VERSION ""

NS_ :

BS_:

BU_: DSAU vHS_M SHVU_RR DPSS AMP ICC RLPSM APSM RWPC RRHV RRPSM CGW_CCU APSS ATS RLHV FPM RDC PSM ASAU

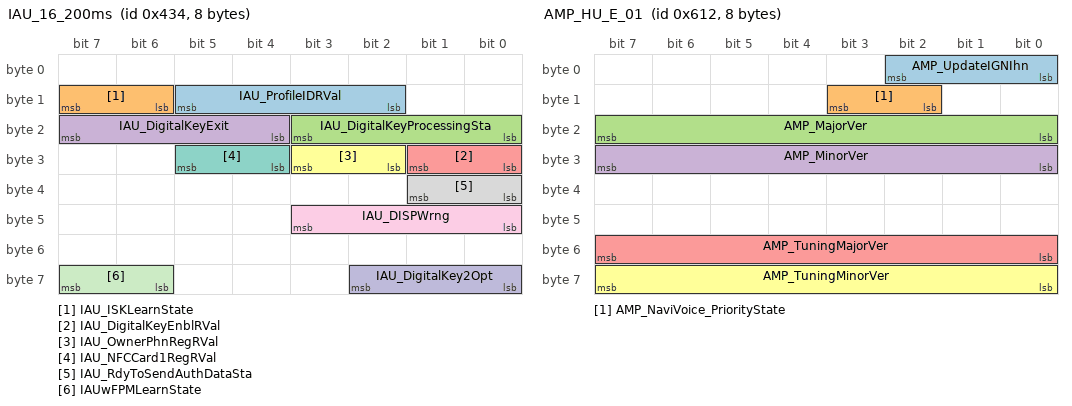
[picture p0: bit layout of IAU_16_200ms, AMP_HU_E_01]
BO_ 1076 IAU_16_200ms: 8 CGW_CCU
 SG_ IAU_ProfileIDRVal : 10|4@1+ (1,0) [0|0] ""  PSM,FPM
 SG_ IAU_ISKLearnState : 14|2@1+ (1,0) [0|0] ""  Vector__XXX
 SG_ IAU_DigitalKeyProcessingSta : 16|4@1+ (1,0) [0|0] ""  Vector__XXX
 SG_ IAU_DigitalKeyExit : 20|4@1+ (1,0) [0|0] ""  Vector__XXX
 SG_ IAU_DigitalKeyEnblRVal : 24|2@1+ (1,0) [0|0] ""  Vector__XXX
 SG_ IAU_OwnerPhnRegRVal : 26|2@1+ (1,0) [0|0] ""  Vector__XXX
 SG_ IAU_NFCCard1RegRVal : 28|2@1+ (1,0) [0|0] ""  Vector__XXX
 SG_ IAU_RdyToSendAuthDataSta : 32|2@1+ (1,0) [0|0] ""  Vector__XXX
 SG_ IAU_DISPWrng : 40|4@1+ (1,0) [0|0] ""  Vector__XXX
 SG_ IAU_DigitalKey2Opt : 56|3@1+ (1,0) [0|0] ""  Vector__XXX
 SG_ IAUwFPMLearnState : 62|2@1+ (1,0) [0|0] ""  FPM

BO_ 1554 AMP_HU_E_01: 8 AMP
 SG_ AMP_UpdateIGNIhn : 0|3@1+ (1,0) [0|0] ""  CGW_CCU
 SG_ AMP_NaviVoice_PriorityState : 10|2@1+ (1,0) [0|0] ""  CGW_CCU
 SG_ AMP_MajorVer : 16|8@1+ (1,0) [0|0] ""  CGW_CCU
 SG_ AMP_MinorVer : 24|8@1+ (1,0) [0|0] ""  CGW_CCU
 SG_ AMP_TuningMajorVer : 48|8@1+ (1,0) [0|0] ""  CGW_CCU
 SG_ AMP_TuningMinorVer : 56|8@1+ (1,0) [0|0] ""  CGW_CCU

BO_ 2563126529 HU_AMP_E_06_1: 8 CGW_CCU
 SG_ AMP_MTSVolumeStep : 0|8@1+ (1,0) [0|0] ""  AMP

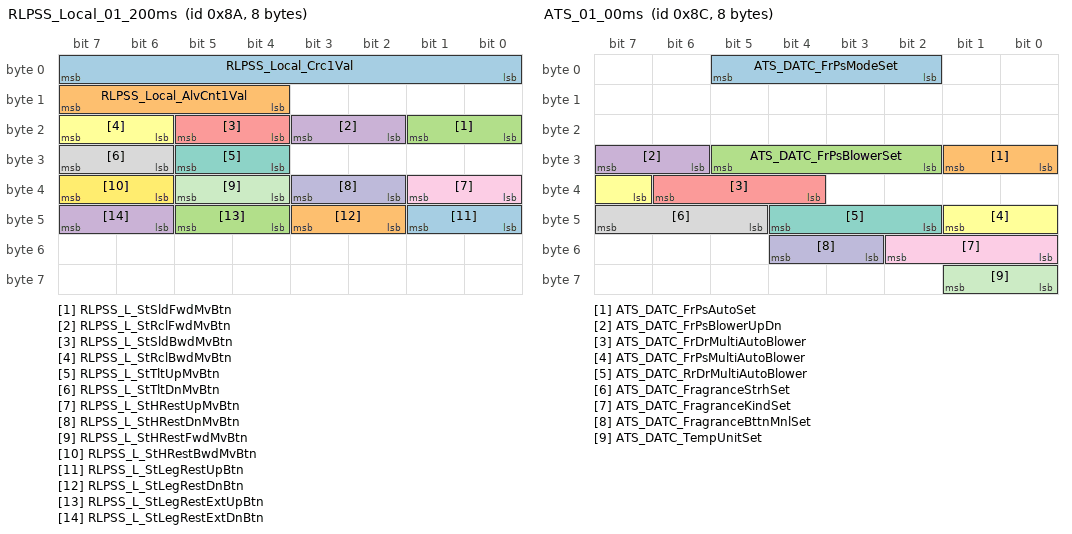
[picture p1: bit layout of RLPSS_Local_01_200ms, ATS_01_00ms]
BO_ 138 RLPSS_Local_01_200ms: 8 RLPSM
 SG_ RLPSS_Local_Crc1Val : 0|8@1+ (1,0) [0|0] ""  CGW_CCU
 SG_ RLPSS_Local_AlvCnt1Val : 12|4@1+ (1,0) [0|0] ""  CGW_CCU
 SG_ RLPSS_L_StSldFwdMvBtn : 16|2@1+ (1,0) [0|0] ""  ATS,CGW_CCU
 SG_ RLPSS_L_StRclFwdMvBtn : 18|2@1+ (1,0) [0|0] ""  ATS,CGW_CCU
 SG_ RLPSS_L_StSldBwdMvBtn : 20|2@1+ (1,0) [0|0] ""  ATS,CGW_CCU
 SG_ RLPSS_L_StRclBwdMvBtn : 22|2@1+ (1,0) [0|0] ""  ATS,CGW_CCU
 SG_ RLPSS_L_StTltUpMvBtn : 28|2@1+ (1,0) [0|0] ""  ATS,CGW_CCU
 SG_ RLPSS_L_StTltDnMvBtn : 30|2@1+ (1,0) [0|0] ""  ATS,CGW_CCU
 SG_ RLPSS_L_StHRestUpMvBtn : 32|2@1+ (1,0) [0|0] ""  ATS,CGW_CCU
 SG_ RLPSS_L_StHRestDnMvBtn : 34|2@1+ (1,0) [0|0] ""  ATS,CGW_CCU
 SG_ RLPSS_L_StHRestFwdMvBtn : 36|2@1+ (1,0) [0|0] ""  ATS,CGW_CCU
 SG_ RLPSS_L_StHRestBwdMvBtn : 38|2@1+ (1,0) [0|0] ""  ATS,CGW_CCU
 SG_ RLPSS_L_StLegRestUpBtn : 40|2@1+ (1,0) [0|0] ""  ATS,CGW_CCU
 SG_ RLPSS_L_StLegRestDnBtn : 42|2@1+ (1,0) [0|0] ""  ATS,CGW_CCU
 SG_ RLPSS_L_StLegRestExtUpBtn : 44|2@1+ (1,0) [0|0] ""  ATS,CGW_CCU
 SG_ RLPSS_L_StLegRestExtDnBtn : 46|2@1+ (1,0) [0|0] ""  ATS,CGW_CCU

BO_ 140 ATS_01_00ms: 8 ATS
 SG_ ATS_DATC_FrPsModeSet : 2|4@1+ (1,0) [0|0] ""  CGW_CCU
 SG_ ATS_DATC_FrPsAutoSet : 24|2@1+ (1,0) [0|0] ""  CGW_CCU
 SG_ ATS_DATC_FrPsBlowerSet : 26|4@1+ (1,0) [0|0] ""  CGW_CCU
 SG_ ATS_DATC_FrPsBlowerUpDn : 30|2@1+ (1,0) [0|0] ""  CGW_CCU
 SG_ ATS_DATC_FrDrMultiAutoBlower : 36|3@1+ (1,0) [0|0] ""  CGW_CCU
 SG_ ATS_DATC_FrPsMultiAutoBlower : 39|3@1+ (1,0) [0|0] ""  CGW_CCU
 SG_ ATS_DATC_RrDrMultiAutoBlower : 42|3@1+ (1,0) [0|0] ""  CGW_CCU
 SG_ ATS_DATC_FragranceStrhSet : 45|3@1+ (1,0) [0|0] ""  CGW_CCU
 SG_ ATS_DATC_FragranceKindSet : 48|3@1+ (1,0) [0|0] ""  CGW_CCU
 SG_ ATS_DATC_FragranceBttnMnlSet : 51|2@1+ (1,0) [0|0] ""  CGW_CCU
 SG_ ATS_DATC_TempUnitSet : 56|2@1+ (1,0) [0|0] ""  CGW_CCU

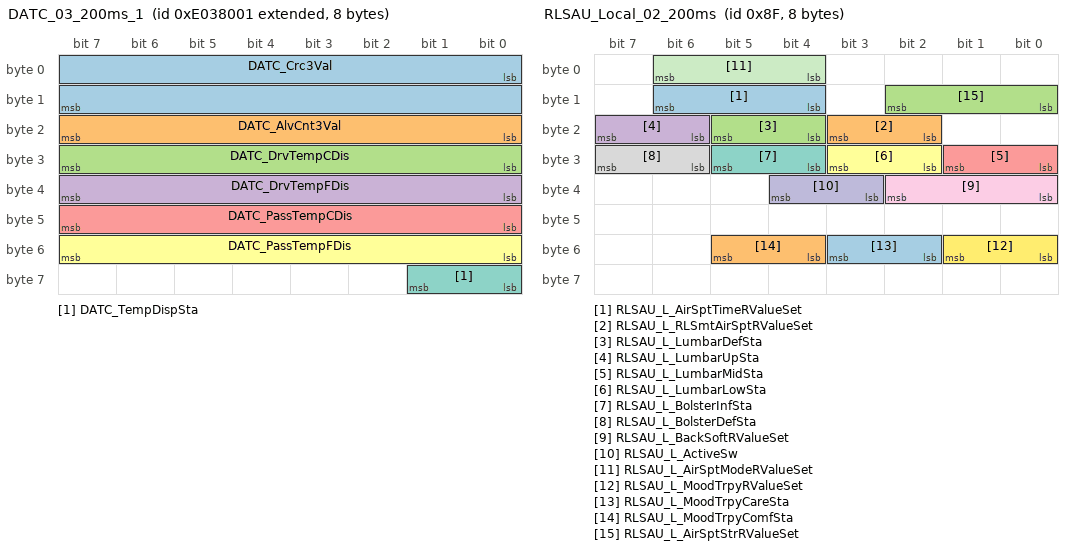
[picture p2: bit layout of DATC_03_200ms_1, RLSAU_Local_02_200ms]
BO_ 2382594049 DATC_03_200ms_1: 8 CGW_CCU
 SG_ DATC_Crc3Val : 0|16@1+ (1,0) [0|0] ""  Vector__XXX
 SG_ DATC_AlvCnt3Val : 16|8@1+ (1,0) [0|0] ""  Vector__XXX
 SG_ DATC_DrvTempCDis : 24|8@1+ (0.5,14) [0|0] "℃"  ATS
 SG_ DATC_DrvTempFDis : 32|8@1+ (1,56) [0|0] "℉"  ATS
 SG_ DATC_PassTempCDis : 40|8@1+ (0.5,14) [0|0] "℃"  ATS
 SG_ DATC_PassTempFDis : 48|8@1+ (1,56) [0|0] "℉"  ATS
 SG_ DATC_TempDispSta : 56|2@1+ (1,0) [0|0] ""  Vector__XXX

BO_ 143 RLSAU_Local_02_200ms: 8 RLPSM
 SG_ RLSAU_L_AirSptTimeRValueSet : 12|3@1+ (1,0) [0|0] ""  ATS,CGW_CCU
 SG_ RLSAU_L_RLSmtAirSptRValueSet : 18|2@1+ (1,0) [0|0] ""  ATS,CGW_CCU
 SG_ RLSAU_L_LumbarDefSta : 20|2@1+ (1,0) [0|0] ""  ATS,CGW_CCU
 SG_ RLSAU_L_LumbarUpSta : 22|2@1+ (1,0) [0|0] ""  ATS,CGW_CCU
 SG_ RLSAU_L_LumbarMidSta : 24|2@1+ (1,0) [0|0] ""  ATS,CGW_CCU
 SG_ RLSAU_L_LumbarLowSta : 26|2@1+ (1,0) [0|0] ""  ATS,CGW_CCU
 SG_ RLSAU_L_BolsterInfSta : 28|2@1+ (1,0) [0|0] ""  ATS,CGW_CCU
 SG_ RLSAU_L_BolsterDefSta : 30|2@1+ (1,0) [0|0] ""  ATS,CGW_CCU
 SG_ RLSAU_L_BackSoftRValueSet : 32|3@1+ (1,0) [0|0] ""  ATS,CGW_CCU
 SG_ RLSAU_L_ActiveSw : 35|2@1+ (1,0) [0|0] ""  ATS
 SG_ RLSAU_L_AirSptModeRValueSet : 4|3@1+ (1,0) [0|0] ""  ATS,CGW_CCU
 SG_ RLSAU_L_MoodTrpyRValueSet : 48|2@1+ (1,0) [0|0] ""  CGW_CCU
 SG_ RLSAU_L_MoodTrpyCareSta : 50|2@1+ (1,0) [0|0] ""  CGW_CCU
 SG_ RLSAU_L_MoodTrpyComfSta : 52|2@1+ (1,0) [0|0] ""  CGW_CCU
 SG_ RLSAU_L_AirSptStrRValueSet : 8|3@1+ (1,0) [0|0] ""  ATS,CGW_CCU

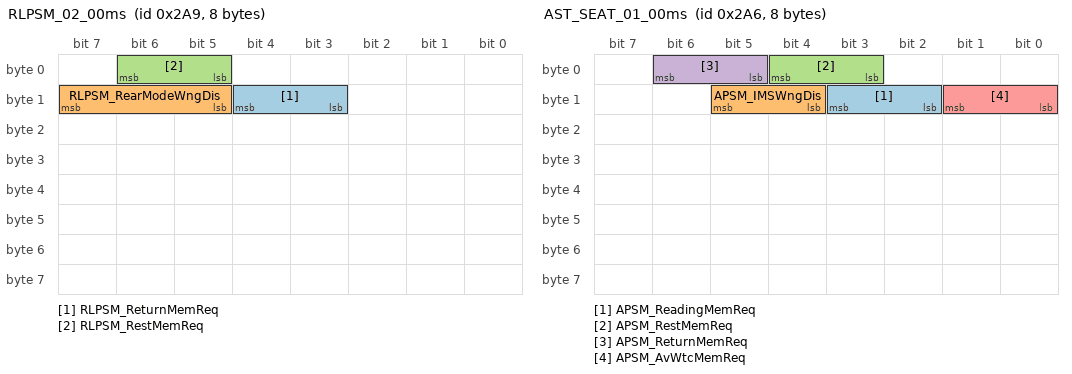
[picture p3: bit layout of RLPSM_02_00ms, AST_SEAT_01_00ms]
BO_ 681 RLPSM_02_00ms: 8 RLPSM
 SG_ RLPSM_ReturnMemReq : 11|2@1+ (1,0) [0|0] ""  ATS
 SG_ RLPSM_RearModeWngDis : 13|3@1+ (1,0) [0|0] ""  CGW_CCU
 SG_ RLPSM_RestMemReq : 5|2@1+ (1,0) [0|0] ""  ATS

BO_ 2323816451 CCU_CCS_01_00ms_3: 8 CGW_CCU

BO_ 2323816450 CCU_CCS_01_00ms_2: 8 CGW_CCU
 SG_ C_EsyAcsProfileID_CCU : 8|4@1+ (1,0) [0|0] ""  PSM

BO_ 678 AST_SEAT_01_00ms: 8 APSM
 SG_ APSM_ReadingMemReq : 10|2@1+ (1,0) [0|0] ""  ATS,RRPSM
 SG_ APSM_IMSWngDis : 12|2@1+ (1,0) [0|0] ""  ATS,CGW_CCU
 SG_ APSM_RestMemReq : 3|2@1+ (1,0) [0|0] ""  ATS,RRPSM
 SG_ APSM_ReturnMemReq : 5|2@1+ (1,0) [0|0] ""  ATS,RRPSM
 SG_ APSM_AvWtcMemReq : 8|2@1+ (1,0) [0|0] ""  ATS,RRPSM

BO_ 2323816449 CCU_CCS_01_00ms_1: 8 CGW_CCU
 SG_ C_CtrlDrLockRlyCCS_Copy_2 : 0|2@1+ (1,0) [0|0] ""  Vector__XXX
 SG_ C_TeleStrgWhlHeatingCmdIBOX_Copy_2 : 12|2@1+ (1,0) [0|0] ""  Vector__XXX
 SG_ C_TeleDefoggerHeatingCmdIBOX_Copy_2 : 14|2@1+ (1,0) [0|0] ""  Vector__XXX
 SG_ C_TeleDrvSeatOpCmdIBOX_Copy_2 : 16|4@1+ (1,0) [0|0] ""  PSM,APSM
 SG_ C_CtrlDrUnlockRlyCCS_Copy_2 : 2|2@1+ (1,0) [0|0] ""  Vector__XXX
 SG_ C_TeleAstSeatOpCmdIBOX_Copy_2 : 20|4@1+ (1,0) [0|0] ""  PSM,APSM
 SG_ C_TeleRRSeatOpCmdIBOX_Copy_2 : 24|4@1+ (1,0) [0|0] ""  RLPSM,RRPSM,RLHV,RRHV,SHVU_RR,ATS
 SG_ C_TeleRLSeatOpCmdIBOX_Copy_1 : 28|4@1+ (1,0) [0|0] ""  RLPSM,RRPSM,RLHV,RRHV,SHVU_RR,ATS
 SG_ C_DrvWindowCmdAVN_Copy_2 : 38|4@1+ (1,0) [0|0] ""  Vector__XXX
 SG_ C_HazardFromCCS_Copy_2 : 4|2@1+ (1,0) [0|0] ""  Vector__XXX
 SG_ C_AstWindowCmdAVN_Copy_2 : 42|4@1+ (1,0) [0|0] ""  Vector__XXX
 SG_ C_RRWindowCmdAVN_Copy_2 : 46|4@1+ (1,0) [0|0] ""  RDC
 SG_ C_RLWindowCmdAVN_Copy_2 : 50|4@1+ (1,0) [0|0] ""  RDC
 SG_ TailCtrlReq_Copy : 54|2@1+ (1,0) [0|0] ""  Vector__XXX
 SG_ HazardCtrlReq_Copy : 56|2@1+ (1,0) [0|0] ""  Vector__XXX
 SG_ C_PanicFromCCS_Copy_2 : 6|2@1+ (1,0) [0|0] ""  Vector__XXX
 SG_ RAC_AirCleaningCtrlReq_Copy_1 : 62|2@1+ (1,0) [0|0] ""  Vector__XXX
 SG_ C_PreCrankReq_Copy : 8|2@1+ (1,0) [0|0] ""  Vector__XXX

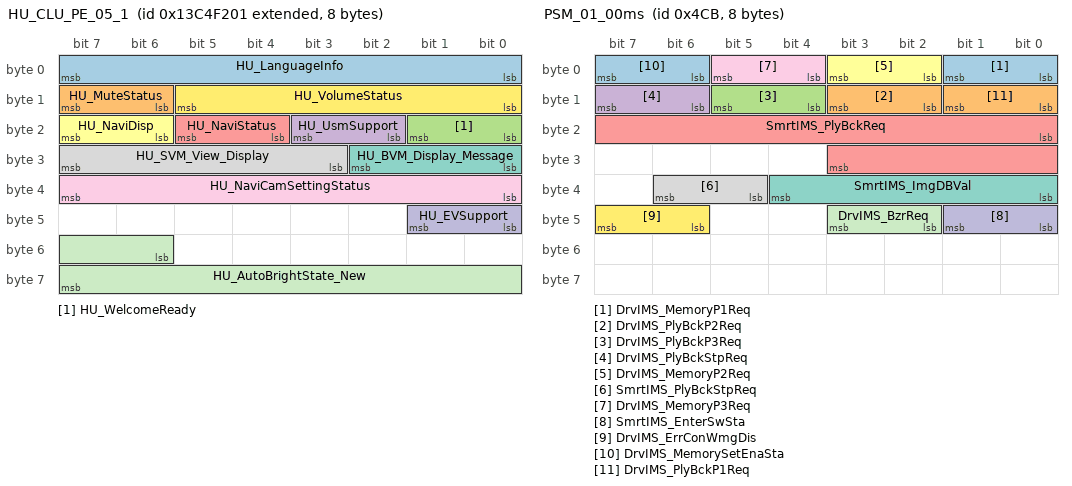
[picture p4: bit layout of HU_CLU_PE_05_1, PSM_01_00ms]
BO_ 2479157761 HU_CLU_PE_05_1: 8 CGW_CCU
 SG_ HU_LanguageInfo : 0|8@1+ (1,0) [0|0] ""  ATS
 SG_ HU_MuteStatus : 14|2@1+ (1,0) [0|0] ""  Vector__XXX
 SG_ HU_WelcomeReady : 16|2@1+ (1,0) [0|0] ""  Vector__XXX
 SG_ HU_UsmSupport : 18|2@1+ (1,0) [0|0] ""  Vector__XXX
 SG_ HU_NaviStatus : 20|2@1+ (1,0) [0|0] ""  DSAU
 SG_ HU_NaviDisp : 22|2@1+ (1,0) [0|0] ""  Vector__XXX
 SG_ HU_BVM_Display_Message : 24|3@1+ (1,0) [0|0] ""  Vector__XXX
 SG_ HU_SVM_View_Display : 27|5@1+ (1,0) [0|0] ""  Vector__XXX
 SG_ HU_NaviCamSettingStatus : 32|8@1+ (1,0) [0|0] ""  Vector__XXX
 SG_ HU_EVSupport : 40|2@1+ (1,0) [0|0] ""  Vector__XXX
 SG_ HU_AutoBrightState_New : 54|10@1+ (1,0) [0|0] ""  Vector__XXX
 SG_ HU_VolumeStatus : 8|6@1+ (1,0) [0|0] ""  Vector__XXX

BO_ 1227 PSM_01_00ms: 8 PSM
 SG_ DrvIMS_MemoryP1Req : 0|2@1+ (1,0) [0|0] ""  CGW_CCU
 SG_ DrvIMS_PlyBckP2Req : 10|2@1+ (1,0) [0|0] ""  CGW_CCU
 SG_ DrvIMS_PlyBckP3Req : 12|2@1+ (1,0) [0|0] ""  CGW_CCU
 SG_ DrvIMS_PlyBckStpReq : 14|2@1+ (1,0) [0|0] ""  CGW_CCU
 SG_ SmrtIMS_PlyBckReq : 16|12@1+ (1,0) [0|0] ""  CGW_CCU
 SG_ DrvIMS_MemoryP2Req : 2|2@1+ (1,0) [0|0] ""  CGW_CCU
 SG_ SmrtIMS_ImgDBVal : 32|5@1+ (1,0) [0|0] ""  CGW_CCU
 SG_ SmrtIMS_PlyBckStpReq : 37|2@1+ (1,0) [0|0] ""  CGW_CCU
 SG_ DrvIMS_MemoryP3Req : 4|2@1+ (1,0) [0|0] ""  CGW_CCU
 SG_ SmrtIMS_EnterSwSta : 40|2@1+ (1,0) [0|0] ""  CGW_CCU
 SG_ DrvIMS_BzrReq : 42|2@1+ (1,0) [0|0] ""  CGW_CCU
 SG_ DrvIMS_ErrConWmgDis : 46|2@1+ (1,0) [0|0] ""  CGW_CCU
 SG_ DrvIMS_MemorySetEnaSta : 6|2@1+ (1,0) [0|0] ""  CGW_CCU
 SG_ DrvIMS_PlyBckP1Req : 8|2@1+ (1,0) [0|0] ""  CGW_CCU

BO_ 2298626049 HU_HDP_PE_00_1: 8 CGW_CCU
 SG_ HU_DSW_HeadPoseYawStat : 0|5@1+ (1,0) [0|0] ""  Vector__XXX
 SG_ HU_DSW_EyeOpenStat : 13|3@1+ (1,0) [0|0] ""  Vector__XXX
 SG_ HU_DSW_RightEyeOpenStat : 16|5@1+ (1,0) [0|0] ""  Vector__XXX
 SG_ HU_DSW_LatestNumBlink : 21|3@1+ (1,0) [0|0] ""  Vector__XXX
 SG_ HU_DSW_HeadPosePitchStat : 24|4@1+ (1,0) [0|0] ""  Vector__XXX
 SG_ HU_DSW_FaceDectStat : 28|2@1+ (1,0) [0|0] ""  Vector__XXX
 SG_ HU_DSW_CamBlckdSta : 30|2@1+ (1,0) [0|0] ""  Vector__XXX
 SG_ HU_DSW_EyeGazePitchStat : 32|4@1+ (1,0) [0|0] ""  Vector__XXX
 SG_ HU_DSW_FakeStat : 36|2@1+ (1,0) [0|0] ""  Vector__XXX
 SG_ HU_DSW_DistWrngTypSta : 38|2@1+ (1,0) [0|0] ""  Vector__XXX
 SG_ HU_DSW_PerclosStat : 40|2@1+ (1,0) [0|0] ""  Vector__XXX
 SG_ HU_DSW_LongBlinkStat : 42|2@1+ (1,0) [0|0] ""  Vector__XXX
 SG_ HU_DSW_TalkStat : 44|2@1+ (1,0) [0|0] ""  Vector__XXX
 SG_ HU_DSW_DistFtgWrngSta : 46|2@1+ (1,0) [0|0] ""  DSAU
 SG_ HU_DSW_EyeGazeYawStat : 48|5@1+ (1,0) [0|0] ""  Vector__XXX
 SG_ HU_DSW_SymSta : 5|3@1+ (1,0) [0|0] ""  DSAU
 SG_ HU_DSW_EyeStat : 53|2@1+ (1,0) [0|0] ""  Vector__XXX
 SG_ HU_DSW_LatestLongClosedStat : 62|2@1+ (1,0) [0|0] ""  Vector__XXX
 SG_ HU_DSW_LeftEyeOpenStat : 8|5@1+ (1,0) [0|0] ""  Vector__XXX

BO_ 2323816452 CCU_CCS_01_00ms_4: 8 CGW_CCU

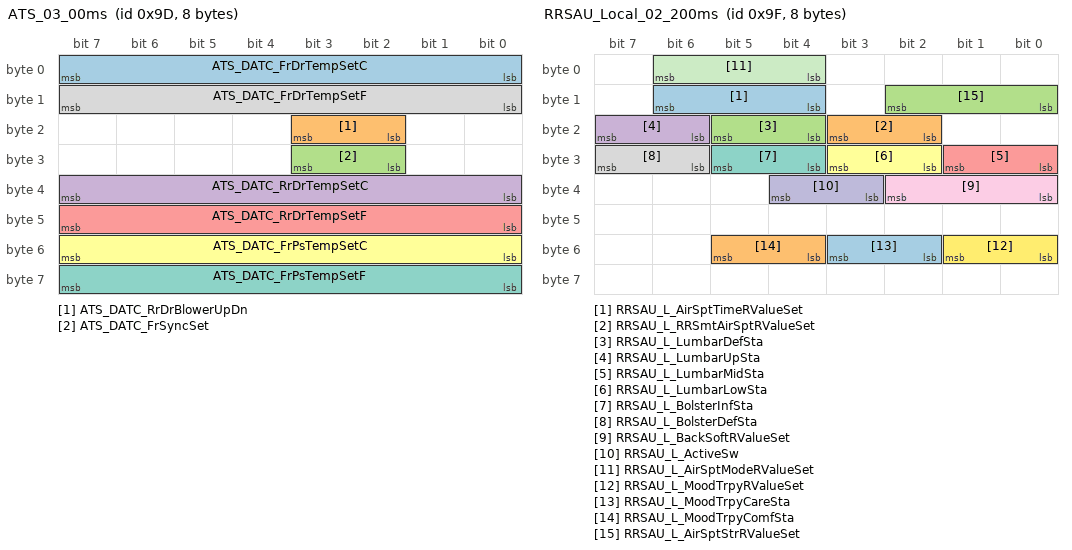
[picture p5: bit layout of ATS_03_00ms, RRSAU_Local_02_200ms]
BO_ 157 ATS_03_00ms: 8 ATS
 SG_ ATS_DATC_FrDrTempSetC : 0|8@1+ (0.5,14) [0|0] ""  CGW_CCU
 SG_ ATS_DATC_RrDrBlowerUpDn : 18|2@1+ (1,0) [0|0] ""  CGW_CCU
 SG_ ATS_DATC_FrSyncSet : 26|2@1+ (1,0) [0|0] ""  CGW_CCU
 SG_ ATS_DATC_RrDrTempSetC : 32|8@1+ (0.5,14) [0|0] ""  CGW_CCU
 SG_ ATS_DATC_RrDrTempSetF : 40|8@1+ (1,56) [0|0] ""  CGW_CCU
 SG_ ATS_DATC_FrPsTempSetC : 48|8@1+ (0.5,14) [0|0] ""  CGW_CCU
 SG_ ATS_DATC_FrPsTempSetF : 56|8@1+ (1,56) [0|0] ""  CGW_CCU
 SG_ ATS_DATC_FrDrTempSetF : 8|8@1+ (1,56) [0|0] ""  CGW_CCU

BO_ 158 ATS_02_00ms: 8 ATS
 SG_ ATS_DATC_FrDrBlowerSet : 12|4@1+ (1,0) [0|0] ""  CGW_CCU
 SG_ ATS_DATC_RrDrTempUpDn : 2|2@1+ (1,0) [0|0] ""  CGW_CCU
 SG_ ATS_DATC_RrDrBlowerSet : 20|4@1+ (1,0) [0|0] ""  CGW_CCU
 SG_ ATS_DATC_RrDrModeSet : 24|4@1+ (1,0) [0|0] ""  CGW_CCU
 SG_ ATS_DATC_FrDrModeSet : 28|4@1+ (1,0) [0|0] ""  CGW_CCU
 SG_ ATS_DATC_RrOnOffSet : 32|2@1+ (1,0) [0|0] ""  Vector__XXX
 SG_ ATS_DATC_IntakeSet : 34|2@1+ (1,0) [0|0] ""  CGW_CCU
 SG_ ATS_DATC_OffReq : 36|2@1+ (1,0) [0|0] ""  Vector__XXX
 SG_ ATS_DATC_FrDrAutoSet : 38|2@1+ (1,0) [0|0] ""  CGW_CCU
 SG_ ATS_DATC_FrPsTempUpDn : 4|2@1+ (1,0) [0|0] ""  CGW_CCU
 SG_ ATS_DATC_FrDefog : 42|2@1+ (1,0) [0|0] ""  CGW_CCU
 SG_ ATS_DATC_RrSyncSet : 44|2@1+ (1,0) [0|0] ""  CGW_CCU
 SG_ ATS_DATC_AcSet : 46|2@1+ (1,0) [0|0] ""  CGW_CCU
 SG_ ATS_DATC_AirCleaningSet : 56|2@1+ (1,0) [0|0] ""  CGW_CCU
 SG_ ATS_DATC_FrDrBlowerUpDn : 58|2@1+ (1,0) [0|0] ""  CGW_CCU
 SG_ ATS_DATC_FrDrTempUpDn : 6|2@1+ (1,0) [0|0] ""  CGW_CCU
 SG_ ATS_DATC_RrDrAutoSet : 62|2@1+ (1,0) [0|0] ""  CGW_CCU

BO_ 159 RRSAU_Local_02_200ms: 8 RLPSM
 SG_ RRSAU_L_AirSptTimeRValueSet : 12|3@1+ (1,0) [0|0] ""  ATS,CGW_CCU
 SG_ RRSAU_L_RRSmtAirSptRValueSet : 18|2@1+ (1,0) [0|0] ""  ATS,CGW_CCU
 SG_ RRSAU_L_LumbarDefSta : 20|2@1+ (1,0) [0|0] ""  ATS,CGW_CCU
 SG_ RRSAU_L_LumbarUpSta : 22|2@1+ (1,0) [0|0] ""  ATS,CGW_CCU
 SG_ RRSAU_L_LumbarMidSta : 24|2@1+ (1,0) [0|0] ""  ATS,CGW_CCU
 SG_ RRSAU_L_LumbarLowSta : 26|2@1+ (1,0) [0|0] ""  ATS,CGW_CCU
 SG_ RRSAU_L_BolsterInfSta : 28|2@1+ (1,0) [0|0] ""  ATS,CGW_CCU
 SG_ RRSAU_L_BolsterDefSta : 30|2@1+ (1,0) [0|0] ""  ATS,CGW_CCU
 SG_ RRSAU_L_BackSoftRValueSet : 32|3@1+ (1,0) [0|0] ""  ATS,CGW_CCU
 SG_ RRSAU_L_ActiveSw : 35|2@1+ (1,0) [0|0] ""  ATS
 SG_ RRSAU_L_AirSptModeRValueSet : 4|3@1+ (1,0) [0|0] ""  ATS,CGW_CCU
 SG_ RRSAU_L_MoodTrpyRValueSet : 48|2@1+ (1,0) [0|0] ""  CGW_CCU
 SG_ RRSAU_L_MoodTrpyCareSta : 50|2@1+ (1,0) [0|0] ""  CGW_CCU
 SG_ RRSAU_L_MoodTrpyComfSta : 52|2@1+ (1,0) [0|0] ""  CGW_CCU
 SG_ RRSAU_L_AirSptStrRValueSet : 8|3@1+ (1,0) [0|0] ""  ATS,CGW_CCU

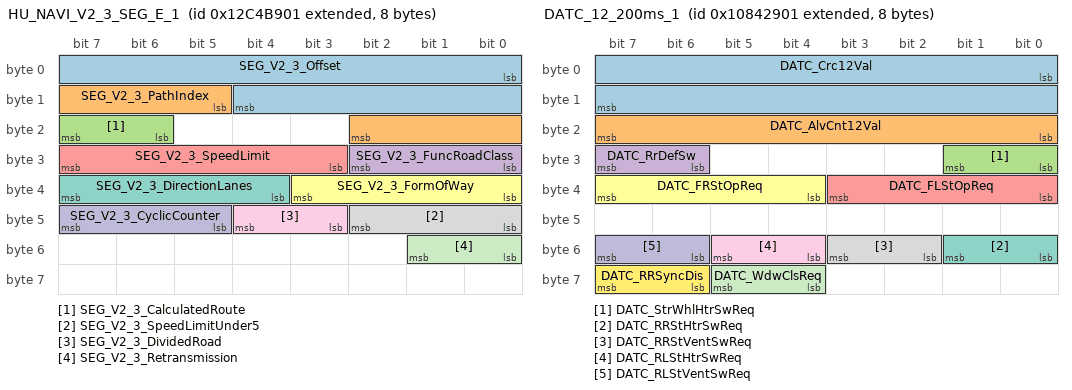
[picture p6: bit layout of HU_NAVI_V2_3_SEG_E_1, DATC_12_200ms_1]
BO_ 2462365953 HU_NAVI_V2_3_SEG_E_1: 8 CGW_CCU
 SG_ SEG_V2_3_Offset : 0|13@1+ (1,0) [0|0] "m"  DSAU
 SG_ SEG_V2_3_PathIndex : 13|6@1+ (1,0) [0|0] ""  Vector__XXX
 SG_ SEG_V2_3_CalculatedRoute : 22|2@1+ (1,0) [0|0] ""  DSAU
 SG_ SEG_V2_3_FuncRoadClass : 24|3@1+ (1,0) [0|0] ""  DSAU
 SG_ SEG_V2_3_SpeedLimit : 27|5@1+ (1,0) [0|0] ""  Vector__XXX
 SG_ SEG_V2_3_FormOfWay : 32|4@1+ (1,0) [0|0] ""  DSAU
 SG_ SEG_V2_3_DirectionLanes : 36|4@1+ (1,0) [0|0] ""  Vector__XXX
 SG_ SEG_V2_3_SpeedLimitUnder5 : 40|3@1+ (1,0) [0|0] ""  Vector__XXX
 SG_ SEG_V2_3_DividedRoad : 43|2@1+ (1,0) [0|0] ""  Vector__XXX
 SG_ SEG_V2_3_CyclicCounter : 45|3@1+ (1,0) [0|0] ""  DSAU
 SG_ SEG_V2_3_Retransmission : 48|2@1+ (1,0) [0|0] ""  Vector__XXX

BO_ 694 ASAU_02_00ms: 8 ASAU
 SG_ ASAU_NotFootMsgOperStaWarn : 0|2@1+ (1,0) [0|0] ""  CGW_CCU

BO_ 2260840449 DATC_02_20ms_1: 8 CGW_CCU
 SG_ DATC_Crc2Val : 0|16@1+ (1,0) [0|0] ""  Vector__XXX
 SG_ DATC_AlvCnt2Val : 16|8@1+ (1,0) [0|0] ""  Vector__XXX

BO_ 2260840450 DATC_02_20ms_2: 8 CGW_CCU

BO_ 2260840451 DATC_02_20ms_3: 8 CGW_CCU
 SG_ DATC_IncarSnsrTempCTestVal : 40|8@1+ (0.5,-40) [0|0] "℃"  AMP

BO_ 2260840452 DATC_02_20ms_4: 8 CGW_CCU

BO_ 2424580353 DATC_12_200ms_1: 8 CGW_CCU
 SG_ DATC_Crc12Val : 0|16@1+ (1,0) [0|0] ""  Vector__XXX
 SG_ DATC_AlvCnt12Val : 16|8@1+ (1,0) [0|0] ""  Vector__XXX
 SG_ DATC_StrWhlHtrSwReq : 24|2@1+ (1,0) [0|0] ""  Vector__XXX
 SG_ DATC_RrDefSw : 30|2@1+ (1,0) [0|0] ""  Vector__XXX
 SG_ DATC_FLStOpReq : 32|4@1+ (1,0) [0|0] ""  PSM,APSM,SHVU_RR
 SG_ DATC_FRStOpReq : 36|4@1+ (1,0) [0|0] ""  PSM,APSM,SHVU_RR
 SG_ DATC_RRStHtrSwReq : 48|2@1+ (1,0) [0|0] ""  RLPSM,RRPSM,RLHV,RRHV
 SG_ DATC_RRStVentSwReq : 50|2@1+ (1,0) [0|0] ""  RLPSM,RRPSM,RLHV,RRHV
 SG_ DATC_RLStHtrSwReq : 52|2@1+ (1,0) [0|0] ""  RLPSM,RRPSM,RLHV,RRHV
 SG_ DATC_RLStVentSwReq : 54|2@1+ (1,0) [0|0] ""  RLPSM,RRPSM,RLHV,RRHV
 SG_ DATC_WdwClsReq : 60|2@1+ (1,0) [0|0] ""  Vector__XXX
 SG_ DATC_RRSyncDis : 62|2@1+ (1,0) [0|0] ""  ATS

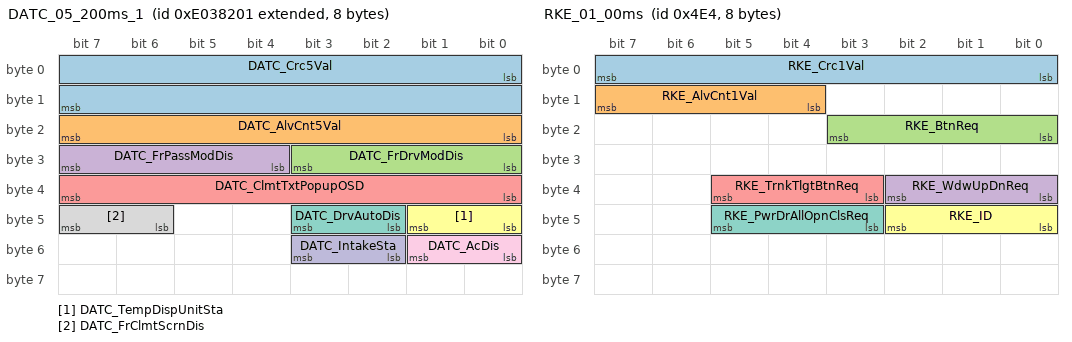
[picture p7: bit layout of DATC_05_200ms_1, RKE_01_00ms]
BO_ 2382594561 DATC_05_200ms_1: 8 CGW_CCU
 SG_ DATC_Crc5Val : 0|16@1+ (1,0) [0|0] ""  Vector__XXX
 SG_ DATC_AlvCnt5Val : 16|8@1+ (1,0) [0|0] ""  Vector__XXX
 SG_ DATC_FrDrvModDis : 24|4@1+ (1,0) [0|0] ""  ATS
 SG_ DATC_FrPassModDis : 28|4@1+ (1,0) [0|0] ""  ATS
 SG_ DATC_ClmtTxtPopupOSD : 32|8@1+ (1,0) [0|0] ""  ATS
 SG_ DATC_TempDispUnitSta : 40|2@1+ (1,0) [0|0] ""  ATS
 SG_ DATC_DrvAutoDis : 42|2@1+ (1,0) [0|0] ""  ATS
 SG_ DATC_FrClmtScrnDis : 46|2@1+ (1,0) [0|0] ""  ATS
 SG_ DATC_AcDis : 48|2@1+ (1,0) [0|0] ""  ATS
 SG_ DATC_IntakeSta : 50|2@1+ (1,0) [0|0] ""  Vector__XXX

BO_ 1253 SMK_01_00ms: 8 CGW_CCU
 SG_ SMK_Crc1Val : 0|8@1+ (1,0) [0|0] ""  Vector__XXX
 SG_ SMK_AlvCnt1Val : 12|4@1+ (1,0) [0|0] ""  Vector__XXX
 SG_ DoorLock_PsvDrLkReq : 16|3@1+ (1,0) [0|0] ""  Vector__XXX
 SG_ DoorLock_PsvDrUnLkReq : 19|3@1+ (1,0) [0|0] ""  Vector__XXX
 SG_ DoorLock_DrvDrPsvAcsReq : 22|2@1+ (1,0) [0|0] ""  Vector__XXX
 SG_ DoorLock_AsstDrPsvAcsReq : 24|2@1+ (1,0) [0|0] ""  Vector__XXX
 SG_ DoorLock_TrnkTlgtPsvAcsReq : 26|2@1+ (1,0) [0|0] ""  Vector__XXX
 SG_ DoorLock_RrLftDrPsvAcsReq : 28|2@1+ (1,0) [0|0] ""  Vector__XXX
 SG_ DoorLock_RrRtDrPsvAcsReq : 30|2@1+ (1,0) [0|0] ""  Vector__XXX
 SG_ Auth_Req : 35|3@1+ (1,0) [0|0] ""  Vector__XXX
 SG_ RSPA_DigitalKeyAuth : 38|2@1+ (1,0) [0|0] ""  Vector__XXX
 SG_ Auth_Method : 42|4@1+ (1,0) [0|0] ""  FPM
 SG_ RSPA_CanTmotFlagSta : 48|2@1+ (1,0) [0|0] ""  Vector__XXX
 SG_ Auth_ISKLearnFdbck : 50|4@1+ (1,0) [0|0] ""  Vector__XXX
 SG_ Mirror_SmrtWlcmMirrReq : 56|2@1+ (1,0) [0|0] ""  Vector__XXX
 SG_ SecureCom_Req : 58|3@1+ (1,0) [0|0] ""  Vector__XXX
 SG_ Auth_Event : 8|4@1+ (1,0) [0|0] ""  Vector__XXX

BO_ 1252 RKE_01_00ms: 8 CGW_CCU
 SG_ RKE_Crc1Val : 0|8@1+ (1,0) [0|0] ""  Vector__XXX
 SG_ RKE_AlvCnt1Val : 12|4@1+ (1,0) [0|0] ""  Vector__XXX
 SG_ RKE_BtnReq : 16|4@1+ (1,0) [0|0] ""  ATS
 SG_ RKE_WdwUpDnReq : 32|3@1+ (1,0) [0|0] ""  RDC
 SG_ RKE_TrnkTlgtBtnReq : 35|3@1+ (1,0) [0|0] ""  Vector__XXX
 SG_ RKE_ID : 40|3@1+ (1,0) [0|0] ""  Vector__XXX
 SG_ RKE_PwrDrAllOpnClsReq : 43|3@1+ (1,0) [0|0] ""  Vector__XXX

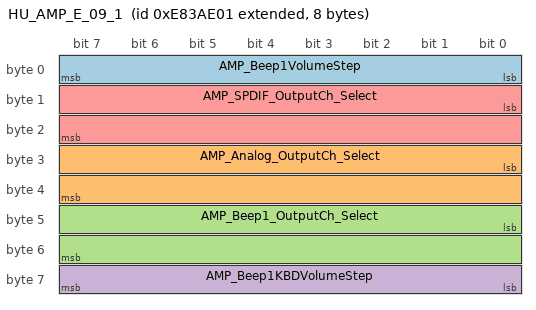
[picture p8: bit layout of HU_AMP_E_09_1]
BO_ 2390994433 HU_AMP_E_09_1: 8 CGW_CCU
 SG_ AMP_Beep1VolumeStep : 0|8@1+ (1,0) [0|0] ""  AMP,ATS
 SG_ AMP_Analog_OutputCh_Select : 24|16@1+ (1,0) [0|0] ""  AMP
 SG_ AMP_Beep1_OutputCh_Select : 40|16@1+ (1,0) [0|0] ""  AMP
 SG_ AMP_Beep1KBDVolumeStep : 56|8@1+ (1,0) [0|0] ""  AMP
 SG_ AMP_SPDIF_OutputCh_Select : 8|16@1+ (1,0) [0|0] ""  AMP

CM_ BO_ 1554 "[EC] On Event and On Change";
CM_ SG_ 1554 AMP_NaviVoice_PriorityState "Information for Current Navi Voice Priority Status-Feedback";
CM_ SG_ 1554 AMP_MajorVer "Information for Version of AMP Software";
CM_ SG_ 1554 AMP_MinorVer "Information for Version of AMP Software";
CM_ SG_ 1554 AMP_TuningMajorVer "Information for Version of AMP EQ tuning data";
CM_ SG_ 1554 AMP_TuningMinorVer "Information for Version of AMP EQ tuning data";
CM_ BO_ 694 "[EC] On Event and On Change";
CM_ SG_ 694 ASAU_NotFootMsgOperStaWarn "Passenger Foot Massage Operation Disable Mode";
CM_ BO_ 678 "[EC] On Event and On Change";
CM_ SG_ 678 APSM_ReadingMemReq "APSM_ReadingPositionMemoryRequest";
CM_ SG_ 678 APSM_IMSWngDis "Ast IMS information";
CM_ SG_ 678 APSM_RestMemReq "APSM_RestModePositionMemoryRequest";
CM_ SG_ 678 APSM_ReturnMemReq "APSM_ReturnModePositionMemoryRequest";
CM_ SG_ 678 APSM_AvWtcMemReq "APSM_AvWatchingPositionMemoryRequest";
CM_ BO_ 140 "[EC] On Event and On Change";
CM_ SG_ 140 ATS_DATC_FrPsModeSet "Front Passenger side Mode Set";
CM_ SG_ 140 ATS_DATC_FrPsAutoSet "Front Passenger side Auto Set";
CM_ SG_ 140 ATS_DATC_FrPsBlowerSet "Front Passenger side Blower Set";
CM_ SG_ 140 ATS_DATC_FrPsBlowerUpDn "Front Passenger side Blower Up Down";
CM_ SG_ 140 ATS_DATC_FrDrMultiAutoBlower "Front Driver side Multi-Auto Blower set";
CM_ SG_ 140 ATS_DATC_FrPsMultiAutoBlower "Front Passenger side Multi-Auto Blower set";
CM_ SG_ 140 ATS_DATC_RrDrMultiAutoBlower "Rear Driver side Multi-Auto Blower set";
CM_ SG_ 140 ATS_DATC_FragranceStrhSet "Fragrance Strength Set (발향 기능 향 세기 설정)";
CM_ SG_ 140 ATS_DATC_FragranceKindSet "Fragrance Kind Set (발향 기능 향 종류 설정)";
CM_ SG_ 140 ATS_DATC_FragranceBttnMnlSet "Fragrance Button Manual Set (발향 기능 버튼 수동 입력)";
CM_ SG_ 140 ATS_DATC_TempUnitSet "Temp Unit Set (온도 단위 설정)";
CM_ BO_ 158 "[EC] On Event and On Change";
CM_ SG_ 158 ATS_DATC_FrDrBlowerSet "Front Driver side Blower Set";
CM_ SG_ 158 ATS_DATC_RrDrTempUpDn "Rear Driver side Temp Up Down";
CM_ SG_ 158 ATS_DATC_RrDrBlowerSet "Rear Driver side Blower Up Down";
CM_ SG_ 158 ATS_DATC_RrDrModeSet "Rear Driver side Mode Set";
CM_ SG_ 158 ATS_DATC_FrDrModeSet "Front Driver side Mode Set";
CM_ SG_ 158 ATS_DATC_RrOnOffSet "Rear Climate On/Off Set";
CM_ SG_ 158 ATS_DATC_IntakeSet "Intake Set";
CM_ SG_ 158 ATS_DATC_OffReq "Front Climate Off Set";
CM_ SG_ 158 ATS_DATC_FrDrAutoSet "Front Driver side Auto Set";
CM_ SG_ 158 ATS_DATC_FrPsTempUpDn "Front Passenger side Temp Up Down";
CM_ SG_ 158 ATS_DATC_FrDefog "Front Defog set";
CM_ SG_ 158 ATS_DATC_RrSyncSet "Rear Sync Set";
CM_ SG_ 158 ATS_DATC_AcSet "Ac Set";
CM_ SG_ 158 ATS_DATC_AirCleaningSet "AirCleaning Set";
CM_ SG_ 158 ATS_DATC_FrDrBlowerUpDn "Front Driver Blower Up Down";
CM_ SG_ 158 ATS_DATC_FrDrTempUpDn "Front Driver side Temp Up Down";
CM_ SG_ 158 ATS_DATC_RrDrAutoSet "Rear Driver side Auto Set";
CM_ BO_ 157 "[EC] On Event and On Change";
CM_ SG_ 157 ATS_DATC_FrDrTempSetC "Front Driver side Temp Set (Celsius)";
CM_ SG_ 157 ATS_DATC_RrDrBlowerUpDn "Rear Driver side Blower Up Down";
CM_ SG_ 157 ATS_DATC_FrSyncSet "Front Sync Set";
CM_ SG_ 157 ATS_DATC_RrDrTempSetC "Rear Driver side Temp Set (Celsius)";
CM_ SG_ 157 ATS_DATC_RrDrTempSetF "Rear Driver side Temp Set (Fahrenheit)";
CM_ SG_ 157 ATS_DATC_FrPsTempSetC "Front Passenger side Temp Set (Celsius)";
CM_ SG_ 157 ATS_DATC_FrPsTempSetF "Front Passenger side Temp Set (Fahrenheit)";
CM_ SG_ 157 ATS_DATC_FrDrTempSetF "Front Driver side Temp Set (Fahrenheit)";
CM_ BO_ 2323816449 "[EC] On Event and On Change";
CM_ SG_ 2323816449 C_CtrlDrLockRlyCCS_Copy_2 "Command for Remote Door Lock";
CM_ SG_ 2323816449 C_TeleStrgWhlHeatingCmdIBOX_Copy_2 "'Command for Remote Heating
(Steering Wheel)";
CM_ SG_ 2323816449 C_TeleDefoggerHeatingCmdIBOX_Copy_2 "'Command for Remote Heating
(Rear Window, Side Mirror)";
CM_ SG_ 2323816449 C_TeleDrvSeatOpCmdIBOX_Copy_2 "Command for Remote Seat Heat/Vent control (Driver)";
CM_ SG_ 2323816449 C_CtrlDrUnlockRlyCCS_Copy_2 "Command for Remote Door UnLock";
CM_ SG_ 2323816449 C_TeleAstSeatOpCmdIBOX_Copy_2 "Command for Remote Seat Heat/Vent control (Passenger)";
CM_ SG_ 2323816449 C_TeleRRSeatOpCmdIBOX_Copy_2 "Command for Remote Seat Heat/Vent control (Rear Right)";
CM_ SG_ 2323816449 C_TeleRLSeatOpCmdIBOX_Copy_1 "Command for Remote Seat Heat/Vent control (Rear Left)";
CM_ SG_ 2323816449 C_DrvWindowCmdAVN_Copy_2 "This signal indicates DRV Window Open/Close Command";
CM_ SG_ 2323816449 C_HazardFromCCS_Copy_2 "Command for Remote Hazard";
CM_ SG_ 2323816449 C_AstWindowCmdAVN_Copy_2 "This signal indicates AST Window Open/Close Command";
CM_ SG_ 2323816449 C_RRWindowCmdAVN_Copy_2 "This signal indicates RR Window Open/Close Command";
CM_ SG_ 2323816449 C_RLWindowCmdAVN_Copy_2 "This signal indicates RL Window Open/Close Command";
CM_ SG_ 2323816449 TailCtrlReq_Copy "This signal is for cotroling Tail lamp.";
CM_ SG_ 2323816449 HazardCtrlReq_Copy "This signal is request for controling Hazard lamp.";
CM_ SG_ 2323816449 C_PanicFromCCS_Copy_2 "Command for Remote Panic (Only for USA)";
CM_ SG_ 2323816449 RAC_AirCleaningCtrlReq_Copy_1 "RAC_Air Cleaning Control Request";
CM_ SG_ 2323816449 C_PreCrankReq_Copy "Command for B-CAN wake up singal (Need to send this signal before other remote commands)";
CM_ BO_ 2323816450 "[EC] On Event and On Change";
CM_ SG_ 2323816450 C_EsyAcsProfileID_CCU "This signal indicates the current detected profile ID by smartphone APP.
(The drv seat move to the easy access position of the detected profile ID when receive the signal)";
CM_ BO_ 2323816451 "[EC] On Event and On Change";
CM_ BO_ 2323816452 "[EC] On Event and On Change";
CM_ BO_ 2260840449 "[P] Periodic";
CM_ SG_ 2260840449 DATC_Crc2Val "DATC_CyclicRedundancyCheckValue";
CM_ SG_ 2260840449 DATC_AlvCnt2Val "DATC_AliveCounter2Value";
CM_ BO_ 2260840450 "[P] Periodic";
CM_ BO_ 2260840451 "[P] Periodic";
CM_ SG_ 2260840451 DATC_IncarSnsrTempCTestVal "DATC_IncarSensorTemperatureCelciusTestValue";
CM_ BO_ 2260840452 "[P] Periodic";
CM_ BO_ 2382594049 "[PE] Periodic and On Event";
CM_ SG_ 2382594049 DATC_Crc3Val "DATC_CyclicRedundancyCheck3Value";
CM_ SG_ 2382594049 DATC_AlvCnt3Val "DATC_AliveCounter3Value";
CM_ SG_ 2382594049 DATC_DrvTempCDis "DATC_DriverTemperatureCelciusDisplay";
CM_ SG_ 2382594049 DATC_DrvTempFDis "DATC_DriverTemperatureFahrenheitDisplay";
CM_ SG_ 2382594049 DATC_PassTempCDis "DATC_PassengerTemperatureCelciusDisplay";
CM_ SG_ 2382594049 DATC_PassTempFDis "DATC_PassengerTemperatureFahrenheitDisplay";
CM_ SG_ 2382594049 DATC_TempDispSta "DATCTempDisplayStatus";
CM_ BO_ 2382594561 "[PE] Periodic and On Event";
CM_ SG_ 2382594561 DATC_Crc5Val "DATC_CyclicRedundancyCheck5Value";
CM_ SG_ 2382594561 DATC_AlvCnt5Val "DATC_AliveCounter5Value";
CM_ SG_ 2382594561 DATC_FrDrvModDis "DATC_FrontDriverModeDisplay";
CM_ SG_ 2382594561 DATC_FrPassModDis "DATC_FrontPassengerModeDisplay";
CM_ SG_ 2382594561 DATC_ClmtTxtPopupOSD "Climate Text Pop-up OSD";
CM_ SG_ 2382594561 DATC_TempDispUnitSta "DATC_TemperatureDiplayUnitStatus";
CM_ SG_ 2382594561 DATC_DrvAutoDis "DATC_DriverAutoDisplay";
CM_ SG_ 2382594561 DATC_FrClmtScrnDis "DATC_FrontClimateScreenDisplay";
CM_ SG_ 2382594561 DATC_AcDis "DATC_ACDisplay";
CM_ SG_ 2382594561 DATC_IntakeSta "DATC_IntakeStatus";
CM_ BO_ 2424580353 "[PE] Periodic and On Event";
CM_ SG_ 2424580353 DATC_Crc12Val "DATC_CyclicRedundancyCheck12Value";
CM_ SG_ 2424580353 DATC_AlvCnt12Val "DATC_AliveCounter12Value";
CM_ SG_ 2424580353 DATC_StrWhlHtrSwReq "DATC_SteeringWheelHeaterSwitchRequest";
CM_ SG_ 2424580353 DATC_RrDefSw "Rear Defog Switch";
CM_ SG_ 2424580353 DATC_FLStOpReq "DATC_FrontLeftSeatOperationRequest";
CM_ SG_ 2424580353 DATC_FRStOpReq "DATC_FrontRightSeatOperationRequest";
CM_ SG_ 2424580353 DATC_RRStHtrSwReq "DATC_RearRightSeatHeaterSwitchRequest";
CM_ SG_ 2424580353 DATC_RRStVentSwReq "DATC_RearRightSeatVentilationSwitchRequest";
CM_ SG_ 2424580353 DATC_RLStHtrSwReq "DATC_RearLeftSeatHeaterSwitchRequest";
CM_ SG_ 2424580353 DATC_RLStVentSwReq "DATC_RearLefttSeatVentilationSwitchRequest";
CM_ SG_ 2424580353 DATC_WdwClsReq "DATC_WindowCloseRequest";
CM_ SG_ 2424580353 DATC_RRSyncDis "DATC_RRSyncDisplay";
CM_ BO_ 2563126529 "[EC] On Event and On Change";
CM_ SG_ 2563126529 AMP_MTSVolumeStep "Command for MTS Call Voume Setting
-range : 0 ~ max
-max : value of AMP_MTSVolumeState(0x083)
For AVN 4.0 production diagnostic";
CM_ BO_ 2390994433 "[EC] On Event and On Change";
CM_ SG_ 2390994433 AMP_Beep1VolumeStep "Command for Touch Beep Sound Volume Setting 
-range : 0 ~ max
-max : value of AMP_MaxBeep1VolumeState(0x087)
Harman AMP Only
-This Signal's Feedback is AMP_Beep1VolumeState(0x08A)@AMP";
CM_ BO_ 2479157761 "[PE] Periodic and On Event";
CM_ SG_ 2479157761 HU_LanguageInfo "Information for System Language (for Display Font)";
CM_ SG_ 2479157761 HU_MuteStatus "Information for System Mute Display";
CM_ SG_ 2479157761 HU_WelcomeReady "HU playback ready signal to play welcome animation video";
CM_ SG_ 2479157761 HU_UsmSupport "Information whether HU can support USM or not";
CM_ SG_ 2479157761 HU_NaviStatus "Information for Navigation Status (Booting, Normal Operation, No SD card)
-AVN NAVI Transmission Signal";
CM_ SG_ 2479157761 HU_NaviDisp "Information for Navi Display status on Front Monitor";
CM_ SG_ 2479157761 HU_BVM_Display_Message "BVM Operation Message";
CM_ SG_ 2479157761 HU_SVM_View_Display "BVM View display to cluster";
CM_ SG_ 2479157761 HU_NaviCamSettingStatus "Information for Navi Camera alert setting status

+ Bit-coded field (On 1, Off 0)
   - bit 0 : Fixed Camera
   - bit 1 : Signal/Speed Violation Camera
   - bit 2 : Movable Camera
   - bit 3 : User Registration Fixed Camera
   - bit 4 : User Registration Signal/Speed Violation Camera
   - bit 5~6 : Reserved
-AVN NAVI Transmission Signal";
CM_ SG_ 2479157761 HU_EVSupport "Notification whether EV function support or not.";
CM_ SG_ 2479157761 HU_AutoBrightState_New "HU Display Brightness State(When automatically adjusted)";
CM_ SG_ 2479157761 HU_VolumeStatus "Information for AVN Volume";
CM_ BO_ 2298626049 "[PE] Periodic and On Event";
CM_ SG_ 2298626049 HU_DSW_HeadPoseYawStat "Yaw angle state of driver’s head pose";
CM_ SG_ 2298626049 HU_DSW_EyeOpenStat "Driver’s eye open state (0: fully closed, 100%: fully opened)";
CM_ SG_ 2298626049 HU_DSW_RightEyeOpenStat "Right Eye Open State (0: fully closed, 100%: fully opend)";
CM_ SG_ 2298626049 HU_DSW_LatestNumBlink "현재 송출 주기[200ms] 에서의 blink 횟수";
CM_ SG_ 2298626049 HU_DSW_HeadPosePitchStat "Pitch angle state of driver’s head pose";
CM_ SG_ 2298626049 HU_DSW_FaceDectStat "Driver’s face detection state";
CM_ SG_ 2298626049 HU_DSW_CamBlckdSta "Interior view camera blockage";
CM_ SG_ 2298626049 HU_DSW_EyeGazePitchStat "Pitch angle state of driver’s eye gaze";
CM_ SG_ 2298626049 HU_DSW_FakeStat "Real face or photo (fake)";
CM_ SG_ 2298626049 HU_DSW_DistWrngTypSta "Warning type";
CM_ SG_ 2298626049 HU_DSW_PerclosStat "PERCLOS (percentage of eye closure)";
CM_ SG_ 2298626049 HU_DSW_LongBlinkStat "Long blink repeat pattern";
CM_ SG_ 2298626049 HU_DSW_TalkStat "Driver talking type";
CM_ SG_ 2298626049 HU_DSW_DistFtgWrngSta "Distraction or fatigue/drowsiness warning based on head pose, eye gaze, and drowsiness.";
CM_ SG_ 2298626049 HU_DSW_EyeGazeYawStat "Yaw angle state of driver’s eye gaze";
CM_ SG_ 2298626049 HU_DSW_SymSta "DSW System State";
CM_ SG_ 2298626049 HU_DSW_EyeStat "현재 eye open/close 상태";
CM_ SG_ 2298626049 HU_DSW_LatestLongClosedStat "현재 [4]초 이상 연속적으로 눈 감음(eye closed) 상태인지 여부";
CM_ SG_ 2298626049 HU_DSW_LeftEyeOpenStat "Left Eye Open State (0: fully closed, 100%: fully opend)";
CM_ BO_ 2462365953 "[EC] On Event and On Change";
CM_ SG_ 2462365953 SEG_V2_3_Offset "Information for Offset of this Segment from current position";
CM_ SG_ 2462365953 SEG_V2_3_PathIndex "Information for Index of path of which this segment is part";
CM_ SG_ 2462365953 SEG_V2_3_CalculatedRoute "Information for Calculated Route: MPP/On Route/Off Route(Recalculating Route)
-MPP: Predicted Route(Not the Link from Searched Route). Used if users don’t set Destination. Used with Current Link Information.
-On Route: Link from Searched Route. Used with Current Link Information.
-Off Route: Used when trying to enter the Rest Area. 'SEG_CalculatedRoute', 'SEG_FormOfWay' and 'SEG_FunctionalRoadClass' are used together. But if it is impossible to decide values of 'SEG_FormOfWay' and 'SEG_FunctionalRoadClass', transmitt Unknown Value. If additional Information happens in forward unit distance, retransmitt it by Event.";
CM_ SG_ 2462365953 SEG_V2_3_FuncRoadClass "Information for Functional Road Class indicates relative importance of the road in the routing network and lower values indicate higher priority";
CM_ SG_ 2462365953 SEG_V2_3_SpeedLimit "Information for Current Link Speed Limit expressed as km/h or mph according to META_SpeedUnit";
CM_ SG_ 2462365953 SEG_V2_3_FormOfWay "Information for Link Class Value of Segment";
CM_ SG_ 2462365953 SEG_V2_3_DirectionLanes "Information for the Number of lanes in driving direction";
CM_ SG_ 2462365953 SEG_V2_3_SpeedLimitUnder5 "Current Link Speed Limit of less than 5 kph or mph according to META_SpeedUnit";
CM_ SG_ 2462365953 SEG_V2_3_DividedRoad "Inform whether there is a Physical Separation on the road";
CM_ SG_ 2462365953 SEG_V2_3_CyclicCounter "Information for Cyclic counter of this message type: Reconstructor can use this value to detect missing messages";
CM_ SG_ 2462365953 SEG_V2_3_Retransmission "Information for Retransmission Flag: If true, this message was sent already at least once before.";
CM_ BO_ 1076 "[PE] Periodic and On Event";
CM_ SG_ 1076 IAU_ProfileIDRVal "This signal Indicate the Current detected Profile ID by IAU.";
CM_ SG_ 1076 IAU_DigitalKeyProcessingSta "Digital Key USM settitng Process State";
CM_ SG_ 1076 IAU_DigitalKeyExit "Digital Key USM setting Exit Condition";
CM_ SG_ 1076 IAU_DigitalKeyEnblRVal "Digital Key Function Enable / Disable flag (Fob is required for changing flag)";
CM_ SG_ 1076 IAU_OwnerPhnRegRVal "Vehicle Owner's Phone is Registered for Digital Key function";
CM_ SG_ 1076 IAU_NFCCard1RegRVal "NFC Card 1 is Registered for Digital Key function";
CM_ SG_ 1076 IAU_RdyToSendAuthDataSta "This signal is sent when IAU is ready to send Authentication data";
CM_ SG_ 1076 IAU_DigitalKey2Opt "Digital Key2 Option Signal";
CM_ BO_ 1227 "[EC] On Event and On Change";
CM_ SG_ 1227 DrvIMS_MemoryP1Req "PSM_DriverSeatPositionMemoryP1Request";
CM_ SG_ 1227 DrvIMS_PlyBckP2Req "PSM_PlayBackP2Request";
CM_ SG_ 1227 DrvIMS_PlyBckP3Req "PSM_PlayBackP3Request";
CM_ SG_ 1227 DrvIMS_PlyBckStpReq "PSM_PlayBackStopRequest";
CM_ SG_ 1227 SmrtIMS_PlyBckReq "HCIMS_PlayBackRequest";
CM_ SG_ 1227 DrvIMS_MemoryP2Req "PSM_DriverSeatPositionMemoryP2Request";
CM_ SG_ 1227 SmrtIMS_ImgDBVal "Smart IMS image DB number";
CM_ SG_ 1227 SmrtIMS_PlyBckStpReq "HCIMS_Status";
CM_ SG_ 1227 DrvIMS_MemoryP3Req "PSM_DriverSeatPositionMemoryP3Request";
CM_ SG_ 1227 SmrtIMS_EnterSwSta "Smart IMS switch on using IMS switch";
CM_ SG_ 1227 DrvIMS_BzrReq "PSM_DriverSeatImsBuzzerRequest";
CM_ SG_ 1227 DrvIMS_ErrConWmgDis "Warning about IMS Mem/Play Error Condition";
CM_ SG_ 1227 DrvIMS_MemorySetEnaSta "PSM_MemorySetEnableStatus";
CM_ SG_ 1227 DrvIMS_PlyBckP1Req "PSM_PlayBackP1Request";
CM_ BO_ 1252 "[EC] On Event and On Change";
CM_ SG_ 1252 RKE_Crc1Val "RKE_CyclicRedundancyCheck1Value";
CM_ SG_ 1252 RKE_AlvCnt1Val "RKE_AliveCounter1Value";
CM_ SG_ 1252 RKE_BtnReq "RemoteKey_ButtonRequest ##2G##BCM - BCMmsg01 - C_RKECmd";
CM_ SG_ 1252 RKE_WdwUpDnReq "RemoteKey_WindowUpDownRequest ##2G##BCM - BCMmsg01 - C_WdwComfortCMDBCM";
CM_ SG_ 1252 RKE_TrnkTlgtBtnReq "RemoteKey_Trunk/TailgateButtonRequest ##2G##BCM - BCMmsg01 - C_TailgateTrunkRKECMD";
CM_ SG_ 1252 RKE_ID "RemoteKey_ID ##2G##BCM - BCMmsg01 - C_BCMRKEID";
CM_ BO_ 681 "[EC] On Event and On Change";
CM_ SG_ 681 RLPSM_ReturnMemReq "RLPSM_ReturnPositionMemoryRequest";
CM_ SG_ 681 RLPSM_RearModeWngDis "Rear Mode information for AVN Display";
CM_ SG_ 681 RLPSM_RestMemReq "RLPSM_RestModePositionMemoryRequest";
CM_ BO_ 138 "[PE] Periodic and On Event";
CM_ SG_ 138 RLPSS_Local_Crc1Val "RLPSS_CyclicRedundancyCheck1Value";
CM_ SG_ 138 RLPSS_Local_AlvCnt1Val "RLPSS_AliveCounter1Value";
CM_ SG_ 138 RLPSS_L_StSldFwdMvBtn "RLPSS_SlideForwardMoveButton";
CM_ SG_ 138 RLPSS_L_StRclFwdMvBtn "RLPSS_ReclinerForwardMoveButton";
CM_ SG_ 138 RLPSS_L_StSldBwdMvBtn "RLPSS_SlideBackwardMoveButton";
CM_ SG_ 138 RLPSS_L_StRclBwdMvBtn "RLPSS_ReclinerBackwardMoveButton";
CM_ SG_ 138 RLPSS_L_StTltUpMvBtn "RLPSS_TiltUpMoveButton";
CM_ SG_ 138 RLPSS_L_StTltDnMvBtn "RLPSS_TiltDownMoveButton";
CM_ SG_ 138 RLPSS_L_StHRestUpMvBtn "RLPSS_Head Rest UpMoveButton";
CM_ SG_ 138 RLPSS_L_StHRestDnMvBtn "RLPSS_Head Rest DownMoveButton";
CM_ SG_ 138 RLPSS_L_StHRestFwdMvBtn "RLPSS_Head Rest ForwardMoveButton";
CM_ SG_ 138 RLPSS_L_StHRestBwdMvBtn "RLPSS_StHRestBwdMvBtn";
CM_ SG_ 138 RLPSS_L_StLegRestUpBtn "RLPSS_Leg Rest Up MoveButton";
CM_ SG_ 138 RLPSS_L_StLegRestDnBtn "RLPSS_Leg Rest Down MoveButton";
CM_ SG_ 138 RLPSS_L_StLegRestExtUpBtn "RLPSS_Leg Rest Forward Move Button";
CM_ SG_ 138 RLPSS_L_StLegRestExtDnBtn "RLPSS_Leg Rest Backward Move Button";
CM_ BO_ 143 "[PE] Periodic and On Event";
CM_ SG_ 143 RLSAU_L_AirSptTimeRValueSet "RLSAU_AirSptTimeRValueSet";
CM_ SG_ 143 RLSAU_L_RLSmtAirSptRValueSet "RLSAU_RLSmtAirSptRValueSet";
CM_ SG_ 143 RLSAU_L_LumbarDefSta "Back Lumbar Def State";
CM_ SG_ 143 RLSAU_L_LumbarUpSta "Back Lumbar Up State";
CM_ SG_ 143 RLSAU_L_LumbarMidSta "Back Lumbar Mid State";
CM_ SG_ 143 RLSAU_L_LumbarLowSta "Back Lumbar Low State";
CM_ SG_ 143 RLSAU_L_BolsterInfSta "Back Bolster Inflate State";
CM_ SG_ 143 RLSAU_L_BolsterDefSta "Back Bolster Deflate State";
CM_ SG_ 143 RLSAU_L_BackSoftRValueSet "RLSAU_BackSoftRValueSet";
CM_ SG_ 143 RLSAU_L_ActiveSw "Active Switch(Massage Strenth Control) Staus";
CM_ SG_ 143 RLSAU_L_AirSptModeRValueSet "RLSAU_AirSptModeRValueSet";
CM_ SG_ 143 RLSAU_L_MoodTrpyRValueSet "Rear Left Seat Mood Therapy R Value";
CM_ SG_ 143 RLSAU_L_MoodTrpyCareSta "Rear Left Seat Mood Therapy Care Mode R Value";
CM_ SG_ 143 RLSAU_L_MoodTrpyComfSta "Rear Left Seat Mood Therapy Comfort Mode R Value";
CM_ SG_ 143 RLSAU_L_AirSptStrRValueSet "RLSAU_AirSptStrRValueSet";
CM_ BO_ 159 "[PE] Periodic and On Event";
CM_ SG_ 159 RRSAU_L_AirSptTimeRValueSet "RRSAU_AirSptTimeRValueSet";
CM_ SG_ 159 RRSAU_L_RRSmtAirSptRValueSet "RRSAU_RRSmtAirSptRValueSet";
CM_ SG_ 159 RRSAU_L_LumbarDefSta "Back Lumbar Deflate State";
CM_ SG_ 159 RRSAU_L_LumbarUpSta "Back Lumbar Up State";
CM_ SG_ 159 RRSAU_L_LumbarMidSta "Back Lumbar Mid State";
CM_ SG_ 159 RRSAU_L_LumbarLowSta "Back Lumbar Low State";
CM_ SG_ 159 RRSAU_L_BolsterInfSta "Back Bolster Inflate State";
CM_ SG_ 159 RRSAU_L_BolsterDefSta "Back Bolster Deflate State";
CM_ SG_ 159 RRSAU_L_BackSoftRValueSet "RRSAU_BackSoftRValueSet";
CM_ SG_ 159 RRSAU_L_ActiveSw "Active Switch(Massage Strenth Control) Staus";
CM_ SG_ 159 RRSAU_L_AirSptModeRValueSet "RRSAU_AirSptModeRValueSet";
CM_ SG_ 159 RRSAU_L_MoodTrpyRValueSet "Rear Right Seat Mood Therapy R Value";
CM_ SG_ 159 RRSAU_L_MoodTrpyCareSta "Rear Right Seat Mood Therapy Care Mode R Value";
CM_ SG_ 159 RRSAU_L_MoodTrpyComfSta "Rear Right Seat Mood Therapy Comfort Mode R Value";
CM_ SG_ 159 RRSAU_L_AirSptStrRValueSet "RRSAU_AirSptStrRValueSet";
CM_ BO_ 1253 "[EC] On Event and On Change";
CM_ SG_ 1253 SMK_Crc1Val "SMK_CyclicRedundancyCheck1Value";
CM_ SG_ 1253 SMK_AlvCnt1Val "SMK_AliveCounter1Value";
CM_ SG_ 1253 DoorLock_PsvDrLkReq "DoorLock_PassiveDoorLockRequest ##2G##SMK - SMKmsg01 - C_PassiveAccessLock";
CM_ SG_ 1253 DoorLock_PsvDrUnLkReq "DoorLock_PassiveDoorUnLockRequest ##2G##SMK - SMKmsg01 - C_PassiveAccessUnlock";
CM_ SG_ 1253 DoorLock_DrvDrPsvAcsReq "DoorLock_DriverDoorPassiveAccessRequest ##2G##SMK - SMKmsg01 - C_PassiveFrtDrv";
CM_ SG_ 1253 DoorLock_AsstDrPsvAcsReq "DoorLock_AssistDoorPassiveAccessRequest ##2G##SMK - SMKmsg01 - C_PassiveFrtAst";
CM_ SG_ 1253 DoorLock_TrnkTlgtPsvAcsReq "DoorLock_TrunkTailgatePassiveAccessRequest ##2G##SMK - SMKmsg01 - C_PassiveTrunkTg";
CM_ SG_ 1253 DoorLock_RrLftDrPsvAcsReq "DoorLock_RearLeftDoorPassiveAccessRequest ##2G##SMK - SMKmsg01 - C_PassiveRrDrv";
CM_ SG_ 1253 DoorLock_RrRtDrPsvAcsReq "DoorLock_RearRightDoorPassiveAccessRequest ##2G##SMK - SMKmsg01 - C_PassiveRrAst";
CM_ SG_ 1253 Auth_Req "Authentication_Request ##2G##SMK - SMKmsg03 - C_SMK_AuthReq";
CM_ SG_ 1253 RSPA_DigitalKeyAuth "2G##SMK - SMKmsg01 - C_RSPADigitalKeyAuth";
CM_ SG_ 1253 Auth_Method "Authentication_Request ##2G##SMK - SMKmsg01 -C_SMK_AuthMethod";
CM_ SG_ 1253 RSPA_CanTmotFlagSta "RSPA_CANTimeoutFlagStatus ##2G##SMK - SMKmsg18 - C_RSPATimeoutFlag";
CM_ SG_ 1253 Auth_ISKLearnFdbck "Authentication_Request ##2G##SMK - SMKmsg01 - C_IBUISKLearnFB";
CM_ SG_ 1253 Mirror_SmrtWlcmMirrReq "Mirror_SmartWelcomeMirrorRequest ##2G##SMK - SMKmsg01 - C_OSMirrCmdSMK";
BA_DEF_ BO_ "DiagState" ENUM "No","Yes" ;
BA_DEF_ BO_ "DiagResponse" ENUM "No","Yes" ;
BA_DEF_ BO_ "DiagRequest" ENUM "No","Yes" ;
BA_DEF_ BO_ "TpMessage" ENUM "No","Yes" ;
BA_DEF_ BO_ "UsrMsgIDSforwardDeviation" INT 0 100 ;
BA_DEF_ BO_ "UsrMsgIDSbackwardDeviation" INT 50 1000 ;
BA_DEF_ BO_ "GenMsgCycleTime" INT 0 2000 ;
BA_DEF_ BO_ "GenMsgStartDelayTime" INT 0 2000 ;
BA_DEF_ BO_ "GenMsgSendType" ENUM "Cyclic","NoMsgSendType" ;
BA_DEF_ BO_ "GenMsgCycleTimeFast" INT 0 500 ;
BA_DEF_ BO_ "GenMsgDelayTime" INT 0 20 ;
BA_DEF_ BO_ "GenMsgILSupport" ENUM "No","Yes" ;
BA_DEF_ BO_ "GenMsgNrOfRepetition" INT 0 3 ;
BA_DEF_ BO_ "NmMessage" ENUM "No","Yes" ;
BA_DEF_ BO_ "NWM-Botschaft" ENUM "No","Yes" ;
BA_DEF_ BO_ "TpTxIndex" INT 0 255 ;
BA_DEF_ BO_ "VFrameFormat" ENUM "StandardCAN","ExtendedCAN","reserved","reserved","reserved","reserved","reserved","reserved","reserved","reserved","reserved","reserved","reserved","reserved","StandardCAN_FD","ExtendedCAN_FD" ;
BA_DEF_ SG_ "UserSigValidity" ENUM "B+","ACC","IG","IG1","IG2","IG3","IG1 or IG2","IG1 or IG3","Undef" ;
BA_DEF_ SG_ "TimeoutValue" STRING ;
BA_DEF_ SG_ "UsrSigPurpose" ENUM "Undef","FN","DIAG","DIAG(Req)","DIAG(Res)","DIAG(Phy)","DEV","CCP(Req)","CCP(Res)","NM","TP" ;
BA_DEF_ SG_ "GenSigStartValue" INT 0 1215752192 ;
BA_DEF_ SG_ "NetworkRequest" ENUM "Yes","No" ;
BA_DEF_ SG_ "NetworkRequestHoldingTime" INT 0 65535 ;
BA_DEF_ SG_ "Description" STRING ;
BA_DEF_ SG_ "Version" STRING ;
BA_DEF_ SG_ "GenSigEnvVarType" ENUM "Int","Float","Undef" ;
BA_DEF_ SG_ "GenSigSendType" ENUM "Cyclic","OnWrite","OnWriteWithRepetition","OnChange","OnChangeWithRepetition","IfActive","IfActiveWithRepetition","NoSigSendType","OnChangeAndIfActive","OnChangeAndIfActiveWithRepetition" ;
BA_DEF_ SG_ "GwSigLatencyTime" INT 0 65536 ;
BA_DEF_ SG_ "GwSigMissingSourceType" ENUM "Undef","OldValue","DefaultValue","InitialValue" ;
BA_DEF_ SG_ "NWM-WakeupAllowed" ENUM "<n.a.>" ;
BA_DEF_ SG_ "RoutingFactor" INT 1 1215752192 ;
BA_DEF_REL_ BU_SG_REL_ "GenSigTimeoutTime" INT 0 7000 ;
BA_DEF_DEF_ "DiagState" "No" ;
BA_DEF_DEF_ "DiagResponse" "No" ;
BA_DEF_DEF_ "DiagRequest" "No" ;
BA_DEF_DEF_ "TpMessage" "No" ;
BA_DEF_DEF_ "UsrMsgIDSforwardDeviation" 10 ;
BA_DEF_DEF_ "UsrMsgIDSbackwardDeviation" 100 ;
BA_DEF_DEF_ "GenMsgCycleTime" 200 ;
BA_DEF_DEF_ "GenMsgStartDelayTime" 0 ;
BA_DEF_DEF_ "GenMsgSendType" "NoMsgSendType" ;
BA_DEF_DEF_ "GenMsgCycleTimeFast" 40 ;
BA_DEF_DEF_ "GenMsgDelayTime" 20 ;
BA_DEF_DEF_ "GenMsgILSupport" "Yes" ;
BA_DEF_DEF_ "GenMsgNrOfRepetition" 3 ;
BA_DEF_DEF_ "NmMessage" "No" ;
BA_DEF_DEF_ "NWM-Botschaft" "No" ;
BA_DEF_DEF_ "TpTxIndex" 0 ;
BA_DEF_DEF_ "VFrameFormat" "StandardCAN" ;
BA_DEF_DEF_ "UserSigValidity" "IG" ;
BA_DEF_DEF_ "TimeoutValue" "" ;
BA_DEF_DEF_ "UsrSigPurpose" "FN" ;
BA_DEF_DEF_ "GenSigStartValue" 0 ;
BA_DEF_DEF_ "NetworkRequest" "No" ;
BA_DEF_DEF_ "NetworkRequestHoldingTime" 0 ;
BA_DEF_DEF_ "Description" "" ;
BA_DEF_DEF_ "Version" "" ;
BA_DEF_DEF_ "GenSigEnvVarType" "Undef" ;
BA_DEF_DEF_ "GenSigSendType" "NoSigSendType" ;
BA_DEF_DEF_ "GwSigLatencyTime" 40 ;
BA_DEF_DEF_ "GwSigMissingSourceType" "Undef" ;
BA_DEF_DEF_ "NWM-WakeupAllowed" "<n.a.>" ;
BA_DEF_DEF_ "RoutingFactor" 1 ;
BA_DEF_DEF_REL_ "GenSigTimeoutTime" 500 ;
BA_ "GenMsgCycleTime" BO_ 1554 0;
BA_ "Description" SG_ 1554 AMP_UpdateIGNIhn "This signal is only used by IBU for Ignition control.



This signal is applied for External AMP software update



Other units should not use this signal.";
BA_ "GenSigSendType" SG_ 1554 AMP_UpdateIGNIhn 4;
BA_ "UserSigValidity" SG_ 1554 AMP_UpdateIGNIhn 0;
BA_REL_ "GenSigTimeoutTime" BU_SG_REL_ CGW_CCU SG_ 1554 AMP_UpdateIGNIhn 0;
BA_ "NetworkRequest" SG_ 1554 AMP_UpdateIGNIhn 0;
BA_ "NetworkRequestHoldingTime" SG_ 1554 AMP_UpdateIGNIhn 5000;
BA_ "Version" SG_ 1554 AMP_UpdateIGNIhn "20.07.10";
BA_ "Description" SG_ 1554 AMP_NaviVoice_PriorityState "Navi voice priority status";
BA_ "GenSigSendType" SG_ 1554 AMP_NaviVoice_PriorityState 4;
BA_ "GenSigStartValue" SG_ 1554 AMP_NaviVoice_PriorityState 3;
BA_ "UserSigValidity" SG_ 1554 AMP_NaviVoice_PriorityState 1;
BA_REL_ "GenSigTimeoutTime" BU_SG_REL_ CGW_CCU SG_ 1554 AMP_NaviVoice_PriorityState 0;
BA_ "Version" SG_ 1554 AMP_NaviVoice_PriorityState "19.01.07";
BA_ "GenSigSendType" SG_ 1554 AMP_MajorVer 4;
BA_ "GenSigStartValue" SG_ 1554 AMP_MajorVer 255;
BA_ "UserSigValidity" SG_ 1554 AMP_MajorVer 1;
BA_REL_ "GenSigTimeoutTime" BU_SG_REL_ CGW_CCU SG_ 1554 AMP_MajorVer 0;
BA_ "NetworkRequest" SG_ 1554 AMP_MajorVer 0;
BA_ "Version" SG_ 1554 AMP_MajorVer "19.01.07";
BA_ "GenSigSendType" SG_ 1554 AMP_MinorVer 4;
BA_ "GenSigStartValue" SG_ 1554 AMP_MinorVer 255;
BA_ "UserSigValidity" SG_ 1554 AMP_MinorVer 1;
BA_REL_ "GenSigTimeoutTime" BU_SG_REL_ CGW_CCU SG_ 1554 AMP_MinorVer 0;
BA_ "NetworkRequest" SG_ 1554 AMP_MinorVer 0;
BA_ "Version" SG_ 1554 AMP_MinorVer "19.01.07";
BA_ "GenSigSendType" SG_ 1554 AMP_TuningMajorVer 4;
BA_ "GenSigStartValue" SG_ 1554 AMP_TuningMajorVer 255;
BA_ "UserSigValidity" SG_ 1554 AMP_TuningMajorVer 1;
BA_REL_ "GenSigTimeoutTime" BU_SG_REL_ CGW_CCU SG_ 1554 AMP_TuningMajorVer 0;
BA_ "NetworkRequest" SG_ 1554 AMP_TuningMajorVer 0;
BA_ "Version" SG_ 1554 AMP_TuningMajorVer "19.01.07";
BA_ "GenSigSendType" SG_ 1554 AMP_TuningMinorVer 4;
BA_ "GenSigStartValue" SG_ 1554 AMP_TuningMinorVer 255;
BA_ "UserSigValidity" SG_ 1554 AMP_TuningMinorVer 1;
BA_REL_ "GenSigTimeoutTime" BU_SG_REL_ CGW_CCU SG_ 1554 AMP_TuningMinorVer 0;
BA_ "NetworkRequest" SG_ 1554 AMP_TuningMinorVer 0;
BA_ "Version" SG_ 1554 AMP_TuningMinorVer "19.01.07";
BA_ "GenMsgCycleTime" BO_ 694 0;
BA_ "Description" SG_ 694 ASAU_NotFootMsgOperStaWarn "Passenger Foot Massage Operation Disable Mode";
BA_ "GenSigSendType" SG_ 694 ASAU_NotFootMsgOperStaWarn 4;
BA_ "UserSigValidity" SG_ 694 ASAU_NotFootMsgOperStaWarn 3;
BA_REL_ "GenSigTimeoutTime" BU_SG_REL_ CGW_CCU SG_ 694 ASAU_NotFootMsgOperStaWarn 0;
BA_ "NetworkRequest" SG_ 694 ASAU_NotFootMsgOperStaWarn 0;
BA_ "NetworkRequestHoldingTime" SG_ 694 ASAU_NotFootMsgOperStaWarn 5000;
BA_ "RoutingFactor" SG_ 694 ASAU_NotFootMsgOperStaWarn 0;
BA_ "Version" SG_ 694 ASAU_NotFootMsgOperStaWarn "20.08.00";
BA_ "GenMsgCycleTime" BO_ 678 0;
BA_ "GenSigSendType" SG_ 678 APSM_ReadingMemReq 4;
BA_ "UserSigValidity" SG_ 678 APSM_ReadingMemReq 3;
BA_REL_ "GenSigTimeoutTime" BU_SG_REL_ ATS SG_ 678 APSM_ReadingMemReq 0;
BA_REL_ "GenSigTimeoutTime" BU_SG_REL_ RRPSM SG_ 678 APSM_ReadingMemReq 0;
BA_ "NetworkRequest" SG_ 678 APSM_ReadingMemReq 0;
BA_ "NetworkRequestHoldingTime" SG_ 678 APSM_ReadingMemReq 5000;
BA_ "RoutingFactor" SG_ 678 APSM_ReadingMemReq 0;
BA_ "Version" SG_ 678 APSM_ReadingMemReq "21.01.02";
BA_ "GenSigSendType" SG_ 678 APSM_IMSWngDis 4;
BA_ "UserSigValidity" SG_ 678 APSM_IMSWngDis 0;
BA_REL_ "GenSigTimeoutTime" BU_SG_REL_ ATS SG_ 678 APSM_IMSWngDis 0;
BA_REL_ "GenSigTimeoutTime" BU_SG_REL_ CGW_CCU SG_ 678 APSM_IMSWngDis 0;
BA_ "NetworkRequest" SG_ 678 APSM_IMSWngDis 0;
BA_ "NetworkRequestHoldingTime" SG_ 678 APSM_IMSWngDis 5000;
BA_ "RoutingFactor" SG_ 678 APSM_IMSWngDis 0;
BA_ "Version" SG_ 678 APSM_IMSWngDis "21.08.01";
BA_ "GenSigSendType" SG_ 678 APSM_RestMemReq 4;
BA_ "UserSigValidity" SG_ 678 APSM_RestMemReq 3;
BA_REL_ "GenSigTimeoutTime" BU_SG_REL_ ATS SG_ 678 APSM_RestMemReq 0;
BA_REL_ "GenSigTimeoutTime" BU_SG_REL_ RRPSM SG_ 678 APSM_RestMemReq 0;
BA_ "NetworkRequest" SG_ 678 APSM_RestMemReq 0;
BA_ "NetworkRequestHoldingTime" SG_ 678 APSM_RestMemReq 5000;
BA_ "RoutingFactor" SG_ 678 APSM_RestMemReq 0;
BA_ "Version" SG_ 678 APSM_RestMemReq "21.01.02";
BA_ "GenSigSendType" SG_ 678 APSM_ReturnMemReq 4;
BA_ "UserSigValidity" SG_ 678 APSM_ReturnMemReq 3;
BA_REL_ "GenSigTimeoutTime" BU_SG_REL_ ATS SG_ 678 APSM_ReturnMemReq 0;
BA_REL_ "GenSigTimeoutTime" BU_SG_REL_ RRPSM SG_ 678 APSM_ReturnMemReq 0;
BA_ "NetworkRequest" SG_ 678 APSM_ReturnMemReq 0;
BA_ "NetworkRequestHoldingTime" SG_ 678 APSM_ReturnMemReq 5000;
BA_ "RoutingFactor" SG_ 678 APSM_ReturnMemReq 0;
BA_ "Version" SG_ 678 APSM_ReturnMemReq "21.01.02";
BA_ "GenSigSendType" SG_ 678 APSM_AvWtcMemReq 4;
BA_ "UserSigValidity" SG_ 678 APSM_AvWtcMemReq 3;
BA_REL_ "GenSigTimeoutTime" BU_SG_REL_ ATS SG_ 678 APSM_AvWtcMemReq 0;
BA_REL_ "GenSigTimeoutTime" BU_SG_REL_ RRPSM SG_ 678 APSM_AvWtcMemReq 0;
BA_ "NetworkRequest" SG_ 678 APSM_AvWtcMemReq 0;
BA_ "NetworkRequestHoldingTime" SG_ 678 APSM_AvWtcMemReq 5000;
BA_ "RoutingFactor" SG_ 678 APSM_AvWtcMemReq 0;
BA_ "Version" SG_ 678 APSM_AvWtcMemReq "21.01.02";
BA_ "GenMsgCycleTime" BO_ 140 0;
BA_ "Description" SG_ 140 ATS_DATC_FrPsModeSet "전석 조수석 측 모드 설정";
BA_ "GenSigSendType" SG_ 140 ATS_DATC_FrPsModeSet 4;
BA_ "UserSigValidity" SG_ 140 ATS_DATC_FrPsModeSet 3;
BA_REL_ "GenSigTimeoutTime" BU_SG_REL_ CGW_CCU SG_ 140 ATS_DATC_FrPsModeSet 0;
BA_ "Version" SG_ 140 ATS_DATC_FrPsModeSet "19.12.08";
BA_ "Description" SG_ 140 ATS_DATC_FrPsAutoSet "전석 조수석 측 AUTO 설정";
BA_ "GenSigSendType" SG_ 140 ATS_DATC_FrPsAutoSet 4;
BA_ "UserSigValidity" SG_ 140 ATS_DATC_FrPsAutoSet 3;
BA_REL_ "GenSigTimeoutTime" BU_SG_REL_ CGW_CCU SG_ 140 ATS_DATC_FrPsAutoSet 0;
BA_ "Version" SG_ 140 ATS_DATC_FrPsAutoSet "19.12.08";
BA_ "Description" SG_ 140 ATS_DATC_FrPsBlowerSet "전석 조수석 측 블로워 단수 설정";
BA_ "GenSigSendType" SG_ 140 ATS_DATC_FrPsBlowerSet 4;
BA_ "GenSigStartValue" SG_ 140 ATS_DATC_FrPsBlowerSet 15;
BA_ "UserSigValidity" SG_ 140 ATS_DATC_FrPsBlowerSet 3;
BA_REL_ "GenSigTimeoutTime" BU_SG_REL_ CGW_CCU SG_ 140 ATS_DATC_FrPsBlowerSet 0;
BA_ "Version" SG_ 140 ATS_DATC_FrPsBlowerSet "19.12.08";
BA_ "Description" SG_ 140 ATS_DATC_FrPsBlowerUpDn "전석 조수석 측 블로워 증감 설정";
BA_ "GenSigSendType" SG_ 140 ATS_DATC_FrPsBlowerUpDn 4;
BA_ "UserSigValidity" SG_ 140 ATS_DATC_FrPsBlowerUpDn 3;
BA_REL_ "GenSigTimeoutTime" BU_SG_REL_ CGW_CCU SG_ 140 ATS_DATC_FrPsBlowerUpDn 0;
BA_ "Version" SG_ 140 ATS_DATC_FrPsBlowerUpDn "19.12.08";
BA_ "Description" SG_ 140 ATS_DATC_FrDrMultiAutoBlower "전석 운전석 측 멀티오토블로워 설정";
BA_ "GenSigSendType" SG_ 140 ATS_DATC_FrDrMultiAutoBlower 4;
BA_ "UserSigValidity" SG_ 140 ATS_DATC_FrDrMultiAutoBlower 3;
BA_REL_ "GenSigTimeoutTime" BU_SG_REL_ CGW_CCU SG_ 140 ATS_DATC_FrDrMultiAutoBlower 0;
BA_ "Version" SG_ 140 ATS_DATC_FrDrMultiAutoBlower "19.12.08";
BA_ "Description" SG_ 140 ATS_DATC_FrPsMultiAutoBlower "전석 조수석 측 멀티오토블로워 설정";
BA_ "GenSigSendType" SG_ 140 ATS_DATC_FrPsMultiAutoBlower 4;
BA_ "UserSigValidity" SG_ 140 ATS_DATC_FrPsMultiAutoBlower 3;
BA_REL_ "GenSigTimeoutTime" BU_SG_REL_ CGW_CCU SG_ 140 ATS_DATC_FrPsMultiAutoBlower 0;
BA_ "Version" SG_ 140 ATS_DATC_FrPsMultiAutoBlower "19.12.08";
BA_ "Description" SG_ 140 ATS_DATC_RrDrMultiAutoBlower "후석 운전석 측 멀티오토블로워 설정";
BA_ "GenSigSendType" SG_ 140 ATS_DATC_RrDrMultiAutoBlower 4;
BA_ "UserSigValidity" SG_ 140 ATS_DATC_RrDrMultiAutoBlower 3;
BA_REL_ "GenSigTimeoutTime" BU_SG_REL_ CGW_CCU SG_ 140 ATS_DATC_RrDrMultiAutoBlower 0;
BA_ "Version" SG_ 140 ATS_DATC_RrDrMultiAutoBlower "19.12.08";
BA_ "Description" SG_ 140 ATS_DATC_FragranceStrhSet "Fragrance Strength Set (발향 기능 향 세기 설정)";
BA_ "GenSigSendType" SG_ 140 ATS_DATC_FragranceStrhSet 4;
BA_ "GenSigStartValue" SG_ 140 ATS_DATC_FragranceStrhSet 7;
BA_ "UserSigValidity" SG_ 140 ATS_DATC_FragranceStrhSet 3;
BA_REL_ "GenSigTimeoutTime" BU_SG_REL_ CGW_CCU SG_ 140 ATS_DATC_FragranceStrhSet 0;
BA_ "Version" SG_ 140 ATS_DATC_FragranceStrhSet "20.03.01";
BA_ "Description" SG_ 140 ATS_DATC_FragranceKindSet "Fragrance Kind Set (발향 기능 향 종류 설정)";
BA_ "GenSigSendType" SG_ 140 ATS_DATC_FragranceKindSet 4;
BA_ "GenSigStartValue" SG_ 140 ATS_DATC_FragranceKindSet 7;
BA_ "UserSigValidity" SG_ 140 ATS_DATC_FragranceKindSet 3;
BA_REL_ "GenSigTimeoutTime" BU_SG_REL_ CGW_CCU SG_ 140 ATS_DATC_FragranceKindSet 0;
BA_ "Version" SG_ 140 ATS_DATC_FragranceKindSet "20.03.01";
BA_ "Description" SG_ 140 ATS_DATC_FragranceBttnMnlSet "Fragrance Button Manual Set (발향 기능 버튼 수동 입력)";
BA_ "GenSigSendType" SG_ 140 ATS_DATC_FragranceBttnMnlSet 4;
BA_ "GenSigStartValue" SG_ 140 ATS_DATC_FragranceBttnMnlSet 3;
BA_ "UserSigValidity" SG_ 140 ATS_DATC_FragranceBttnMnlSet 3;
BA_REL_ "GenSigTimeoutTime" BU_SG_REL_ CGW_CCU SG_ 140 ATS_DATC_FragranceBttnMnlSet 0;
BA_ "Version" SG_ 140 ATS_DATC_FragranceBttnMnlSet "20.03.01";
BA_ "Description" SG_ 140 ATS_DATC_TempUnitSet "Temp Unit Set (온도 단위 설정)";
BA_ "GenSigSendType" SG_ 140 ATS_DATC_TempUnitSet 4;
BA_ "GenSigStartValue" SG_ 140 ATS_DATC_TempUnitSet 3;
BA_ "UserSigValidity" SG_ 140 ATS_DATC_TempUnitSet 3;
BA_REL_ "GenSigTimeoutTime" BU_SG_REL_ CGW_CCU SG_ 140 ATS_DATC_TempUnitSet 0;
BA_ "Version" SG_ 140 ATS_DATC_TempUnitSet "20.04.02";
BA_ "GenMsgCycleTime" BO_ 158 0;
BA_ "Description" SG_ 158 ATS_DATC_FrDrBlowerSet "전석 운전석 측 블로워 단수 설정";
BA_ "GenSigSendType" SG_ 158 ATS_DATC_FrDrBlowerSet 4;
BA_ "GenSigStartValue" SG_ 158 ATS_DATC_FrDrBlowerSet 15;
BA_ "UserSigValidity" SG_ 158 ATS_DATC_FrDrBlowerSet 3;
BA_REL_ "GenSigTimeoutTime" BU_SG_REL_ CGW_CCU SG_ 158 ATS_DATC_FrDrBlowerSet 0;
BA_ "Version" SG_ 158 ATS_DATC_FrDrBlowerSet "19.12.08";
BA_ "Description" SG_ 158 ATS_DATC_RrDrTempUpDn "후석 운전석 측 설정온도 증감 설정";
BA_ "GenSigSendType" SG_ 158 ATS_DATC_RrDrTempUpDn 4;
BA_ "UserSigValidity" SG_ 158 ATS_DATC_RrDrTempUpDn 3;
BA_REL_ "GenSigTimeoutTime" BU_SG_REL_ CGW_CCU SG_ 158 ATS_DATC_RrDrTempUpDn 0;
BA_ "Version" SG_ 158 ATS_DATC_RrDrTempUpDn "19.12.08";
BA_ "Description" SG_ 158 ATS_DATC_RrDrBlowerSet "후석 운전석 측 블로워 증감 설정";
BA_ "GenSigSendType" SG_ 158 ATS_DATC_RrDrBlowerSet 4;
BA_ "GenSigStartValue" SG_ 158 ATS_DATC_RrDrBlowerSet 15;
BA_ "UserSigValidity" SG_ 158 ATS_DATC_RrDrBlowerSet 3;
BA_REL_ "GenSigTimeoutTime" BU_SG_REL_ CGW_CCU SG_ 158 ATS_DATC_RrDrBlowerSet 0;
BA_ "Version" SG_ 158 ATS_DATC_RrDrBlowerSet "19.12.08";
BA_ "Description" SG_ 158 ATS_DATC_RrDrModeSet "후석 운전석 측 모드 설정";
BA_ "GenSigSendType" SG_ 158 ATS_DATC_RrDrModeSet 4;
BA_ "GenSigStartValue" SG_ 158 ATS_DATC_RrDrModeSet 15;
BA_ "UserSigValidity" SG_ 158 ATS_DATC_RrDrModeSet 3;
BA_REL_ "GenSigTimeoutTime" BU_SG_REL_ CGW_CCU SG_ 158 ATS_DATC_RrDrModeSet 0;
BA_ "Version" SG_ 158 ATS_DATC_RrDrModeSet "19.12.08";
BA_ "Description" SG_ 158 ATS_DATC_FrDrModeSet "전석 운전석 측 모드 설정";
BA_ "GenSigSendType" SG_ 158 ATS_DATC_FrDrModeSet 4;
BA_ "UserSigValidity" SG_ 158 ATS_DATC_FrDrModeSet 3;
BA_REL_ "GenSigTimeoutTime" BU_SG_REL_ CGW_CCU SG_ 158 ATS_DATC_FrDrModeSet 0;
BA_ "Version" SG_ 158 ATS_DATC_FrDrModeSet "19.12.08";
BA_ "Description" SG_ 158 ATS_DATC_RrOnOffSet "후석 공조 온오프 설정";
BA_ "GenSigSendType" SG_ 158 ATS_DATC_RrOnOffSet 4;
BA_ "GenSigStartValue" SG_ 158 ATS_DATC_RrOnOffSet 3;
BA_ "UserSigValidity" SG_ 158 ATS_DATC_RrOnOffSet 3;
BA_ "Version" SG_ 158 ATS_DATC_RrOnOffSet "19.12.08";
BA_ "Description" SG_ 158 ATS_DATC_IntakeSet "내외기 설정";
BA_ "GenSigSendType" SG_ 158 ATS_DATC_IntakeSet 4;
BA_ "GenSigStartValue" SG_ 158 ATS_DATC_IntakeSet 3;
BA_ "UserSigValidity" SG_ 158 ATS_DATC_IntakeSet 3;
BA_REL_ "GenSigTimeoutTime" BU_SG_REL_ CGW_CCU SG_ 158 ATS_DATC_IntakeSet 0;
BA_ "Version" SG_ 158 ATS_DATC_IntakeSet "19.12.08";
BA_ "Description" SG_ 158 ATS_DATC_OffReq "전석 공조 오프 설정";
BA_ "GenSigSendType" SG_ 158 ATS_DATC_OffReq 4;
BA_ "UserSigValidity" SG_ 158 ATS_DATC_OffReq 3;
BA_ "Version" SG_ 158 ATS_DATC_OffReq "19.12.08";
BA_ "Description" SG_ 158 ATS_DATC_FrDrAutoSet "전석 운전석 측 AUTO 설정";
BA_ "GenSigSendType" SG_ 158 ATS_DATC_FrDrAutoSet 4;
BA_ "UserSigValidity" SG_ 158 ATS_DATC_FrDrAutoSet 3;
BA_REL_ "GenSigTimeoutTime" BU_SG_REL_ CGW_CCU SG_ 158 ATS_DATC_FrDrAutoSet 0;
BA_ "Version" SG_ 158 ATS_DATC_FrDrAutoSet "19.12.08";
BA_ "Description" SG_ 158 ATS_DATC_FrPsTempUpDn "전석 조수석 측 설정온도 증감 설정";
BA_ "GenSigSendType" SG_ 158 ATS_DATC_FrPsTempUpDn 4;
BA_ "UserSigValidity" SG_ 158 ATS_DATC_FrPsTempUpDn 3;
BA_REL_ "GenSigTimeoutTime" BU_SG_REL_ CGW_CCU SG_ 158 ATS_DATC_FrPsTempUpDn 0;
BA_ "Version" SG_ 158 ATS_DATC_FrPsTempUpDn "19.12.08";
BA_ "Description" SG_ 158 ATS_DATC_FrDefog "전석 DEF 설정";
BA_ "GenSigSendType" SG_ 158 ATS_DATC_FrDefog 4;
BA_ "GenSigStartValue" SG_ 158 ATS_DATC_FrDefog 3;
BA_ "UserSigValidity" SG_ 158 ATS_DATC_FrDefog 3;
BA_REL_ "GenSigTimeoutTime" BU_SG_REL_ CGW_CCU SG_ 158 ATS_DATC_FrDefog 0;
BA_ "Version" SG_ 158 ATS_DATC_FrDefog "19.12.08";
BA_ "Description" SG_ 158 ATS_DATC_RrSyncSet "후석 SYNC 설정";
BA_ "GenSigSendType" SG_ 158 ATS_DATC_RrSyncSet 4;
BA_ "UserSigValidity" SG_ 158 ATS_DATC_RrSyncSet 3;
BA_REL_ "GenSigTimeoutTime" BU_SG_REL_ CGW_CCU SG_ 158 ATS_DATC_RrSyncSet 0;
BA_ "Version" SG_ 158 ATS_DATC_RrSyncSet "19.12.08";
BA_ "Description" SG_ 158 ATS_DATC_AcSet "AC 설정";
BA_ "GenSigSendType" SG_ 158 ATS_DATC_AcSet 4;
BA_ "GenSigStartValue" SG_ 158 ATS_DATC_AcSet 3;
BA_ "UserSigValidity" SG_ 158 ATS_DATC_AcSet 3;
BA_REL_ "GenSigTimeoutTime" BU_SG_REL_ CGW_CCU SG_ 158 ATS_DATC_AcSet 0;
BA_ "Version" SG_ 158 ATS_DATC_AcSet "19.12.08";
BA_ "Description" SG_ 158 ATS_DATC_AirCleaningSet "공기청정모드 설정";
BA_ "GenSigSendType" SG_ 158 ATS_DATC_AirCleaningSet 4;
BA_ "GenSigStartValue" SG_ 158 ATS_DATC_AirCleaningSet 3;
BA_ "UserSigValidity" SG_ 158 ATS_DATC_AirCleaningSet 3;
BA_REL_ "GenSigTimeoutTime" BU_SG_REL_ CGW_CCU SG_ 158 ATS_DATC_AirCleaningSet 0;
BA_ "Version" SG_ 158 ATS_DATC_AirCleaningSet "19.12.08";
BA_ "Description" SG_ 158 ATS_DATC_FrDrBlowerUpDn "전석 운전석 측 블로워 증감 설정";
BA_ "GenSigSendType" SG_ 158 ATS_DATC_FrDrBlowerUpDn 4;
BA_ "UserSigValidity" SG_ 158 ATS_DATC_FrDrBlowerUpDn 3;
BA_REL_ "GenSigTimeoutTime" BU_SG_REL_ CGW_CCU SG_ 158 ATS_DATC_FrDrBlowerUpDn 0;
BA_ "Version" SG_ 158 ATS_DATC_FrDrBlowerUpDn "19.12.08";
BA_ "Description" SG_ 158 ATS_DATC_FrDrTempUpDn "전석 운전석 측 설정온도 증감 설정";
BA_ "GenSigSendType" SG_ 158 ATS_DATC_FrDrTempUpDn 4;
BA_ "UserSigValidity" SG_ 158 ATS_DATC_FrDrTempUpDn 3;
BA_REL_ "GenSigTimeoutTime" BU_SG_REL_ CGW_CCU SG_ 158 ATS_DATC_FrDrTempUpDn 0;
BA_ "Version" SG_ 158 ATS_DATC_FrDrTempUpDn "19.12.08";
BA_ "Description" SG_ 158 ATS_DATC_RrDrAutoSet "후석 운전석 측 AUTO 설정";
BA_ "GenSigSendType" SG_ 158 ATS_DATC_RrDrAutoSet 4;
BA_ "GenSigStartValue" SG_ 158 ATS_DATC_RrDrAutoSet 3;
BA_ "UserSigValidity" SG_ 158 ATS_DATC_RrDrAutoSet 3;
BA_REL_ "GenSigTimeoutTime" BU_SG_REL_ CGW_CCU SG_ 158 ATS_DATC_RrDrAutoSet 0;
BA_ "Version" SG_ 158 ATS_DATC_RrDrAutoSet "19.12.08";
BA_ "GenMsgCycleTime" BO_ 157 0;
BA_ "Description" SG_ 157 ATS_DATC_FrDrTempSetC "전석 운전석 측 설정온도값(섭씨) 설정";
BA_ "GenSigSendType" SG_ 157 ATS_DATC_FrDrTempSetC 4;
BA_ "GenSigStartValue" SG_ 157 ATS_DATC_FrDrTempSetC 255;
BA_ "UserSigValidity" SG_ 157 ATS_DATC_FrDrTempSetC 3;
BA_REL_ "GenSigTimeoutTime" BU_SG_REL_ CGW_CCU SG_ 157 ATS_DATC_FrDrTempSetC 0;
BA_ "Version" SG_ 157 ATS_DATC_FrDrTempSetC "19.12.08";
BA_ "Description" SG_ 157 ATS_DATC_RrDrBlowerUpDn "후석 운전석 측 블로워 증감 설정";
BA_ "GenSigSendType" SG_ 157 ATS_DATC_RrDrBlowerUpDn 4;
BA_ "UserSigValidity" SG_ 157 ATS_DATC_RrDrBlowerUpDn 3;
BA_REL_ "GenSigTimeoutTime" BU_SG_REL_ CGW_CCU SG_ 157 ATS_DATC_RrDrBlowerUpDn 0;
BA_ "Version" SG_ 157 ATS_DATC_RrDrBlowerUpDn "19.12.08";
BA_ "Description" SG_ 157 ATS_DATC_FrSyncSet "전석 SYNC 설정";
BA_ "GenSigSendType" SG_ 157 ATS_DATC_FrSyncSet 4;
BA_ "UserSigValidity" SG_ 157 ATS_DATC_FrSyncSet 3;
BA_REL_ "GenSigTimeoutTime" BU_SG_REL_ CGW_CCU SG_ 157 ATS_DATC_FrSyncSet 0;
BA_ "Version" SG_ 157 ATS_DATC_FrSyncSet "19.12.08";
BA_ "Description" SG_ 157 ATS_DATC_RrDrTempSetC "후석 운전석 측 설정온도값(섭씨) 설정";
BA_ "GenSigSendType" SG_ 157 ATS_DATC_RrDrTempSetC 4;
BA_ "GenSigStartValue" SG_ 157 ATS_DATC_RrDrTempSetC 255;
BA_ "UserSigValidity" SG_ 157 ATS_DATC_RrDrTempSetC 3;
BA_REL_ "GenSigTimeoutTime" BU_SG_REL_ CGW_CCU SG_ 157 ATS_DATC_RrDrTempSetC 0;
BA_ "Version" SG_ 157 ATS_DATC_RrDrTempSetC "19.12.08";
BA_ "Description" SG_ 157 ATS_DATC_RrDrTempSetF "후석 운전석 측 설정온도값(화씨) 설정";
BA_ "GenSigSendType" SG_ 157 ATS_DATC_RrDrTempSetF 4;
BA_ "GenSigStartValue" SG_ 157 ATS_DATC_RrDrTempSetF 255;
BA_ "UserSigValidity" SG_ 157 ATS_DATC_RrDrTempSetF 3;
BA_REL_ "GenSigTimeoutTime" BU_SG_REL_ CGW_CCU SG_ 157 ATS_DATC_RrDrTempSetF 0;
BA_ "Version" SG_ 157 ATS_DATC_RrDrTempSetF "19.12.08";
BA_ "Description" SG_ 157 ATS_DATC_FrPsTempSetC "전석 조수석 측 설정온도값(섭씨) 설정";
BA_ "GenSigSendType" SG_ 157 ATS_DATC_FrPsTempSetC 4;
BA_ "GenSigStartValue" SG_ 157 ATS_DATC_FrPsTempSetC 255;
BA_ "UserSigValidity" SG_ 157 ATS_DATC_FrPsTempSetC 3;
BA_REL_ "GenSigTimeoutTime" BU_SG_REL_ CGW_CCU SG_ 157 ATS_DATC_FrPsTempSetC 0;
BA_ "Version" SG_ 157 ATS_DATC_FrPsTempSetC "19.12.08";
BA_ "Description" SG_ 157 ATS_DATC_FrPsTempSetF "전석 조수석 측 설정온도값(화씨) 설정";
BA_ "GenSigSendType" SG_ 157 ATS_DATC_FrPsTempSetF 4;
BA_ "GenSigStartValue" SG_ 157 ATS_DATC_FrPsTempSetF 255;
BA_ "UserSigValidity" SG_ 157 ATS_DATC_FrPsTempSetF 3;
BA_REL_ "GenSigTimeoutTime" BU_SG_REL_ CGW_CCU SG_ 157 ATS_DATC_FrPsTempSetF 0;
BA_ "Version" SG_ 157 ATS_DATC_FrPsTempSetF "19.12.08";
BA_ "Description" SG_ 157 ATS_DATC_FrDrTempSetF "전석 운전석 측 설정온도값(화씨) 설정";
BA_ "GenSigSendType" SG_ 157 ATS_DATC_FrDrTempSetF 4;
BA_ "GenSigStartValue" SG_ 157 ATS_DATC_FrDrTempSetF 255;
BA_ "UserSigValidity" SG_ 157 ATS_DATC_FrDrTempSetF 3;
BA_REL_ "GenSigTimeoutTime" BU_SG_REL_ CGW_CCU SG_ 157 ATS_DATC_FrDrTempSetF 0;
BA_ "Version" SG_ 157 ATS_DATC_FrDrTempSetF "19.12.08";
BA_ "GenMsgCycleTime" BO_ 2323816449 0;
BA_ "VFrameFormat" BO_ 2323816449 1;
BA_ "GenSigSendType" SG_ 2323816449 C_CtrlDrLockRlyCCS_Copy_2 4;
BA_ "UserSigValidity" SG_ 2323816449 C_CtrlDrLockRlyCCS_Copy_2 0;
BA_ "NetworkRequest" SG_ 2323816449 C_CtrlDrLockRlyCCS_Copy_2 0;
BA_ "NetworkRequestHoldingTime" SG_ 2323816449 C_CtrlDrLockRlyCCS_Copy_2 2000;
BA_ "Version" SG_ 2323816449 C_CtrlDrLockRlyCCS_Copy_2 "20.08.07";
BA_ "GenSigSendType" SG_ 2323816449 C_TeleStrgWhlHeatingCmdIBOX_Copy_2 4;
BA_ "GenSigStartValue" SG_ 2323816449 C_TeleStrgWhlHeatingCmdIBOX_Copy_2 3;
BA_ "UserSigValidity" SG_ 2323816449 C_TeleStrgWhlHeatingCmdIBOX_Copy_2 0;
BA_ "NetworkRequest" SG_ 2323816449 C_TeleStrgWhlHeatingCmdIBOX_Copy_2 0;
BA_ "NetworkRequestHoldingTime" SG_ 2323816449 C_TeleStrgWhlHeatingCmdIBOX_Copy_2 2000;
BA_ "Version" SG_ 2323816449 C_TeleStrgWhlHeatingCmdIBOX_Copy_2 "20.08.07";
BA_ "GenSigSendType" SG_ 2323816449 C_TeleDefoggerHeatingCmdIBOX_Copy_2 4;
BA_ "GenSigStartValue" SG_ 2323816449 C_TeleDefoggerHeatingCmdIBOX_Copy_2 3;
BA_ "UserSigValidity" SG_ 2323816449 C_TeleDefoggerHeatingCmdIBOX_Copy_2 0;
BA_ "NetworkRequest" SG_ 2323816449 C_TeleDefoggerHeatingCmdIBOX_Copy_2 0;
BA_ "NetworkRequestHoldingTime" SG_ 2323816449 C_TeleDefoggerHeatingCmdIBOX_Copy_2 2000;
BA_ "Version" SG_ 2323816449 C_TeleDefoggerHeatingCmdIBOX_Copy_2 "20.08.07";
BA_ "GenSigSendType" SG_ 2323816449 C_TeleDrvSeatOpCmdIBOX_Copy_2 4;
BA_ "UserSigValidity" SG_ 2323816449 C_TeleDrvSeatOpCmdIBOX_Copy_2 3;
BA_REL_ "GenSigTimeoutTime" BU_SG_REL_ PSM SG_ 2323816449 C_TeleDrvSeatOpCmdIBOX_Copy_2 0;
BA_REL_ "GenSigTimeoutTime" BU_SG_REL_ APSM SG_ 2323816449 C_TeleDrvSeatOpCmdIBOX_Copy_2 0;
BA_ "Version" SG_ 2323816449 C_TeleDrvSeatOpCmdIBOX_Copy_2 "20.08.07";
BA_ "GenSigSendType" SG_ 2323816449 C_CtrlDrUnlockRlyCCS_Copy_2 4;
BA_ "UserSigValidity" SG_ 2323816449 C_CtrlDrUnlockRlyCCS_Copy_2 0;
BA_ "NetworkRequest" SG_ 2323816449 C_CtrlDrUnlockRlyCCS_Copy_2 0;
BA_ "NetworkRequestHoldingTime" SG_ 2323816449 C_CtrlDrUnlockRlyCCS_Copy_2 2000;
BA_ "Version" SG_ 2323816449 C_CtrlDrUnlockRlyCCS_Copy_2 "20.08.07";
BA_ "GenSigSendType" SG_ 2323816449 C_TeleAstSeatOpCmdIBOX_Copy_2 4;
BA_ "UserSigValidity" SG_ 2323816449 C_TeleAstSeatOpCmdIBOX_Copy_2 3;
BA_REL_ "GenSigTimeoutTime" BU_SG_REL_ PSM SG_ 2323816449 C_TeleAstSeatOpCmdIBOX_Copy_2 0;
BA_REL_ "GenSigTimeoutTime" BU_SG_REL_ APSM SG_ 2323816449 C_TeleAstSeatOpCmdIBOX_Copy_2 0;
BA_ "Version" SG_ 2323816449 C_TeleAstSeatOpCmdIBOX_Copy_2 "20.08.07";
BA_ "GenSigSendType" SG_ 2323816449 C_TeleRRSeatOpCmdIBOX_Copy_2 4;
BA_ "UserSigValidity" SG_ 2323816449 C_TeleRRSeatOpCmdIBOX_Copy_2 3;
BA_REL_ "GenSigTimeoutTime" BU_SG_REL_ RLPSM SG_ 2323816449 C_TeleRRSeatOpCmdIBOX_Copy_2 0;
BA_REL_ "GenSigTimeoutTime" BU_SG_REL_ RRPSM SG_ 2323816449 C_TeleRRSeatOpCmdIBOX_Copy_2 0;
BA_REL_ "GenSigTimeoutTime" BU_SG_REL_ RLHV SG_ 2323816449 C_TeleRRSeatOpCmdIBOX_Copy_2 0;
BA_REL_ "GenSigTimeoutTime" BU_SG_REL_ RRHV SG_ 2323816449 C_TeleRRSeatOpCmdIBOX_Copy_2 0;
BA_REL_ "GenSigTimeoutTime" BU_SG_REL_ SHVU_RR SG_ 2323816449 C_TeleRRSeatOpCmdIBOX_Copy_2 0;
BA_REL_ "GenSigTimeoutTime" BU_SG_REL_ ATS SG_ 2323816449 C_TeleRRSeatOpCmdIBOX_Copy_2 0;
BA_ "Version" SG_ 2323816449 C_TeleRRSeatOpCmdIBOX_Copy_2 "20.08.07";
BA_ "GenSigSendType" SG_ 2323816449 C_TeleRLSeatOpCmdIBOX_Copy_1 4;
BA_ "UserSigValidity" SG_ 2323816449 C_TeleRLSeatOpCmdIBOX_Copy_1 3;
BA_REL_ "GenSigTimeoutTime" BU_SG_REL_ RLPSM SG_ 2323816449 C_TeleRLSeatOpCmdIBOX_Copy_1 0;
BA_REL_ "GenSigTimeoutTime" BU_SG_REL_ RRPSM SG_ 2323816449 C_TeleRLSeatOpCmdIBOX_Copy_1 0;
BA_REL_ "GenSigTimeoutTime" BU_SG_REL_ RLHV SG_ 2323816449 C_TeleRLSeatOpCmdIBOX_Copy_1 0;
BA_REL_ "GenSigTimeoutTime" BU_SG_REL_ RRHV SG_ 2323816449 C_TeleRLSeatOpCmdIBOX_Copy_1 0;
BA_REL_ "GenSigTimeoutTime" BU_SG_REL_ SHVU_RR SG_ 2323816449 C_TeleRLSeatOpCmdIBOX_Copy_1 0;
BA_REL_ "GenSigTimeoutTime" BU_SG_REL_ ATS SG_ 2323816449 C_TeleRLSeatOpCmdIBOX_Copy_1 0;
BA_ "Version" SG_ 2323816449 C_TeleRLSeatOpCmdIBOX_Copy_1 "20.08.07";
BA_ "GenSigSendType" SG_ 2323816449 C_DrvWindowCmdAVN_Copy_2 4;
BA_ "GenSigStartValue" SG_ 2323816449 C_DrvWindowCmdAVN_Copy_2 15;
BA_ "UserSigValidity" SG_ 2323816449 C_DrvWindowCmdAVN_Copy_2 0;
BA_ "Version" SG_ 2323816449 C_DrvWindowCmdAVN_Copy_2 "20.08.07";
BA_ "GenSigSendType" SG_ 2323816449 C_HazardFromCCS_Copy_2 4;
BA_ "UserSigValidity" SG_ 2323816449 C_HazardFromCCS_Copy_2 0;
BA_ "NetworkRequest" SG_ 2323816449 C_HazardFromCCS_Copy_2 0;
BA_ "NetworkRequestHoldingTime" SG_ 2323816449 C_HazardFromCCS_Copy_2 2000;
BA_ "Version" SG_ 2323816449 C_HazardFromCCS_Copy_2 "20.08.07";
BA_ "GenSigSendType" SG_ 2323816449 C_AstWindowCmdAVN_Copy_2 4;
BA_ "GenSigStartValue" SG_ 2323816449 C_AstWindowCmdAVN_Copy_2 15;
BA_ "UserSigValidity" SG_ 2323816449 C_AstWindowCmdAVN_Copy_2 0;
BA_ "Version" SG_ 2323816449 C_AstWindowCmdAVN_Copy_2 "20.08.07";
BA_ "GenSigSendType" SG_ 2323816449 C_RRWindowCmdAVN_Copy_2 4;
BA_ "GenSigStartValue" SG_ 2323816449 C_RRWindowCmdAVN_Copy_2 15;
BA_ "UserSigValidity" SG_ 2323816449 C_RRWindowCmdAVN_Copy_2 0;
BA_REL_ "GenSigTimeoutTime" BU_SG_REL_ RDC SG_ 2323816449 C_RRWindowCmdAVN_Copy_2 0;
BA_ "Version" SG_ 2323816449 C_RRWindowCmdAVN_Copy_2 "20.08.07";
BA_ "GenSigSendType" SG_ 2323816449 C_RLWindowCmdAVN_Copy_2 4;
BA_ "GenSigStartValue" SG_ 2323816449 C_RLWindowCmdAVN_Copy_2 15;
BA_ "UserSigValidity" SG_ 2323816449 C_RLWindowCmdAVN_Copy_2 0;
BA_REL_ "GenSigTimeoutTime" BU_SG_REL_ RDC SG_ 2323816449 C_RLWindowCmdAVN_Copy_2 0;
BA_ "Version" SG_ 2323816449 C_RLWindowCmdAVN_Copy_2 "20.08.07";
BA_ "Description" SG_ 2323816449 TailCtrlReq_Copy "This signal is for cotroling Tail lamp.";
BA_ "GenSigSendType" SG_ 2323816449 TailCtrlReq_Copy 4;
BA_ "UserSigValidity" SG_ 2323816449 TailCtrlReq_Copy 0;
BA_ "Version" SG_ 2323816449 TailCtrlReq_Copy "20.08.07";
BA_ "Description" SG_ 2323816449 HazardCtrlReq_Copy "This signal is request for controling Hazard lamp.";
BA_ "GenSigSendType" SG_ 2323816449 HazardCtrlReq_Copy 4;
BA_ "UserSigValidity" SG_ 2323816449 HazardCtrlReq_Copy 0;
BA_ "Version" SG_ 2323816449 HazardCtrlReq_Copy "20.08.07";
BA_ "GenSigSendType" SG_ 2323816449 C_PanicFromCCS_Copy_2 4;
BA_ "UserSigValidity" SG_ 2323816449 C_PanicFromCCS_Copy_2 0;
BA_ "NetworkRequest" SG_ 2323816449 C_PanicFromCCS_Copy_2 0;
BA_ "NetworkRequestHoldingTime" SG_ 2323816449 C_PanicFromCCS_Copy_2 2000;
BA_ "Version" SG_ 2323816449 C_PanicFromCCS_Copy_2 "20.08.07";
BA_ "Description" SG_ 2323816449 RAC_AirCleaningCtrlReq_Copy_1 "CCS Module(Telematics unit) transmits this signal to control the air cleaning when the remote air-condition is request.";
BA_ "GenSigSendType" SG_ 2323816449 RAC_AirCleaningCtrlReq_Copy_1 4;
BA_ "UserSigValidity" SG_ 2323816449 RAC_AirCleaningCtrlReq_Copy_1 3;
BA_ "Version" SG_ 2323816449 RAC_AirCleaningCtrlReq_Copy_1 "20.09.00";
BA_ "GenSigSendType" SG_ 2323816449 C_PreCrankReq_Copy 4;
BA_ "UserSigValidity" SG_ 2323816449 C_PreCrankReq_Copy 0;
BA_ "NetworkRequest" SG_ 2323816449 C_PreCrankReq_Copy 0;
BA_ "Version" SG_ 2323816449 C_PreCrankReq_Copy "20.08.07";
BA_ "GenMsgCycleTime" BO_ 2323816450 0;
BA_ "VFrameFormat" BO_ 2323816450 1;
BA_ "GenSigSendType" SG_ 2323816450 C_EsyAcsProfileID_CCU 4;
BA_ "UserSigValidity" SG_ 2323816450 C_EsyAcsProfileID_CCU 0;
BA_REL_ "GenSigTimeoutTime" BU_SG_REL_ PSM SG_ 2323816450 C_EsyAcsProfileID_CCU 0;
BA_ "Version" SG_ 2323816450 C_EsyAcsProfileID_CCU "20.09.00";
BA_ "GenMsgCycleTime" BO_ 2323816451 0;
BA_ "VFrameFormat" BO_ 2323816451 1;
BA_ "GenMsgCycleTime" BO_ 2323816452 0;
BA_ "VFrameFormat" BO_ 2323816452 1;
BA_ "GenMsgSendType" BO_ 2260840449 0;
BA_ "GenMsgCycleTime" BO_ 2260840449 100;
BA_ "GenMsgCycleTimeFast" BO_ 2260840449 0;
BA_ "GenMsgNrOfRepetition" BO_ 2260840449 0;
BA_ "VFrameFormat" BO_ 2260840449 1;
BA_ "Description" SG_ 2260840449 DATC_Crc2Val "The data area for CRC calculation is based on the data length (DLC) of the message DB.

The CRC shall be calculated over the entire data block (excluding the CRC bytes) including the user data, alive counter and Data ID

 

- CRC Polynomial (0x1021) , Initial Value : 0xFFFF, XOR value : 0x0000, Data ID : Message ID + 0xF800 

- The initial value is for CRC calculation and the message should be sent with the calculated result value. 

- The mathematical expression to 16 bit CRC polynomial is given here. G(x) = x16 + x12 + x5 + 1";
BA_ "GenSigStartValue" SG_ 2260840449 DATC_Crc2Val 65535;
BA_ "UserSigValidity" SG_ 2260840449 DATC_Crc2Val 7;
BA_ "RoutingFactor" SG_ 2260840449 DATC_Crc2Val 5;
BA_ "Version" SG_ 2260840449 DATC_Crc2Val "18.11.08";
BA_ "Description" SG_ 2260840449 DATC_AlvCnt2Val "For the first transmission request for a data element the counter shall be initialized with 0 and shall be incremented by 1 for every subsequent send request. 

When the counter reaches the maximum value(0xFF), then it shall restart with 0 for the next send request";
BA_ "UserSigValidity" SG_ 2260840449 DATC_AlvCnt2Val 7;
BA_ "RoutingFactor" SG_ 2260840449 DATC_AlvCnt2Val 5;
BA_ "Version" SG_ 2260840449 DATC_AlvCnt2Val "18.11.08";
BA_ "GenMsgSendType" BO_ 2260840450 0;
BA_ "GenMsgCycleTime" BO_ 2260840450 100;
BA_ "GenMsgCycleTimeFast" BO_ 2260840450 0;
BA_ "GenMsgNrOfRepetition" BO_ 2260840450 0;
BA_ "VFrameFormat" BO_ 2260840450 1;
BA_ "GenMsgSendType" BO_ 2260840451 0;
BA_ "GenMsgCycleTime" BO_ 2260840451 100;
BA_ "GenMsgCycleTimeFast" BO_ 2260840451 0;
BA_ "GenMsgNrOfRepetition" BO_ 2260840451 0;
BA_ "VFrameFormat" BO_ 2260840451 1;
BA_ "Description" SG_ 2260840451 DATC_IncarSnsrTempCTestVal "This signal indicates Incar Temperature(℃)";
BA_ "UserSigValidity" SG_ 2260840451 DATC_IncarSnsrTempCTestVal 5;
BA_REL_ "GenSigTimeoutTime" BU_SG_REL_ AMP SG_ 2260840451 DATC_IncarSnsrTempCTestVal 1500;
BA_ "RoutingFactor" SG_ 2260840451 DATC_IncarSnsrTempCTestVal 5;
BA_ "Version" SG_ 2260840451 DATC_IncarSnsrTempCTestVal "17.11.00";
BA_ "GenMsgSendType" BO_ 2260840452 0;
BA_ "GenMsgCycleTime" BO_ 2260840452 100;
BA_ "GenMsgCycleTimeFast" BO_ 2260840452 0;
BA_ "GenMsgNrOfRepetition" BO_ 2260840452 0;
BA_ "VFrameFormat" BO_ 2260840452 1;
BA_ "GenMsgSendType" BO_ 2382594049 0;
BA_ "VFrameFormat" BO_ 2382594049 1;
BA_ "Description" SG_ 2382594049 DATC_Crc3Val "The data area for CRC calculation is based on the data length (DLC) of the message DB.

The CRC shall be calculated over the entire data block (excluding the CRC bytes) including the user data, alive counter and Data ID

 

- CRC Polynomial (0x1021) , Initial Value : 0xFFFF, XOR value : 0x0000, Data ID : Message ID + 0xF800 

- The initial value is for CRC calculation and the message should be sent with the calculated result value. 

- The mathematical expression to 16 bit CRC polynomial is given here. G(x) = x16 + x12 + x5 + 1";
BA_ "GenSigSendType" SG_ 2382594049 DATC_Crc3Val 4;
BA_ "GenSigStartValue" SG_ 2382594049 DATC_Crc3Val 65535;
BA_ "UserSigValidity" SG_ 2382594049 DATC_Crc3Val 3;
BA_ "Version" SG_ 2382594049 DATC_Crc3Val "18.11.08";
BA_ "Description" SG_ 2382594049 DATC_AlvCnt3Val "For the first transmission request for a data element the counter shall be initialized with 0 and shall be incremented by 1 for every subsequent send request. 

When the counter reaches the maximum value(0xFF), then it shall restart with 0 for the next send request";
BA_ "GenSigSendType" SG_ 2382594049 DATC_AlvCnt3Val 4;
BA_ "UserSigValidity" SG_ 2382594049 DATC_AlvCnt3Val 3;
BA_ "Version" SG_ 2382594049 DATC_AlvCnt3Val "18.11.08";
BA_ "Description" SG_ 2382594049 DATC_DrvTempCDis "This signal indicates setting temperature (℃) of Driver Side.";
BA_ "GenSigSendType" SG_ 2382594049 DATC_DrvTempCDis 4;
BA_ "UserSigValidity" SG_ 2382594049 DATC_DrvTempCDis 6;
BA_REL_ "GenSigTimeoutTime" BU_SG_REL_ ATS SG_ 2382594049 DATC_DrvTempCDis 1500;
BA_ "Version" SG_ 2382594049 DATC_DrvTempCDis "18.05.01";
BA_ "Description" SG_ 2382594049 DATC_DrvTempFDis "This signal indicates setting temperature (℉) of Driver Side.";
BA_ "GenSigSendType" SG_ 2382594049 DATC_DrvTempFDis 4;
BA_ "UserSigValidity" SG_ 2382594049 DATC_DrvTempFDis 6;
BA_REL_ "GenSigTimeoutTime" BU_SG_REL_ ATS SG_ 2382594049 DATC_DrvTempFDis 1500;
BA_ "Version" SG_ 2382594049 DATC_DrvTempFDis "18.05.01";
BA_ "Description" SG_ 2382594049 DATC_PassTempCDis "This signal indicates setting temperature (℃) of Passenger Side.";
BA_ "GenSigSendType" SG_ 2382594049 DATC_PassTempCDis 4;
BA_ "UserSigValidity" SG_ 2382594049 DATC_PassTempCDis 6;
BA_REL_ "GenSigTimeoutTime" BU_SG_REL_ ATS SG_ 2382594049 DATC_PassTempCDis 1500;
BA_ "Version" SG_ 2382594049 DATC_PassTempCDis "18.05.01";
BA_ "Description" SG_ 2382594049 DATC_PassTempFDis "This signal indicates setting temperature (℉) of Passenger Side.";
BA_ "GenSigSendType" SG_ 2382594049 DATC_PassTempFDis 4;
BA_ "UserSigValidity" SG_ 2382594049 DATC_PassTempFDis 6;
BA_REL_ "GenSigTimeoutTime" BU_SG_REL_ ATS SG_ 2382594049 DATC_PassTempFDis 1500;
BA_ "Version" SG_ 2382594049 DATC_PassTempFDis "18.05.01";
BA_ "Description" SG_ 2382594049 DATC_TempDispSta "This signal is an information display of the set temperature range of DATC.";
BA_ "GenSigSendType" SG_ 2382594049 DATC_TempDispSta 4;
BA_ "UserSigValidity" SG_ 2382594049 DATC_TempDispSta 7;
BA_ "Version" SG_ 2382594049 DATC_TempDispSta "17.11.00";
BA_ "GenMsgSendType" BO_ 2382594561 0;
BA_ "VFrameFormat" BO_ 2382594561 1;
BA_ "Description" SG_ 2382594561 DATC_Crc5Val "The data area for CRC calculation is based on the data length (DLC) of the message DB.

The CRC shall be calculated over the entire data block (excluding the CRC bytes) including the user data, alive counter and Data ID

 

- CRC Polynomial (0x1021) , Initial Value : 0xFFFF, XOR value : 0x0000, Data ID : Message ID + 0xF800 

- The initial value is for CRC calculation and the message should be sent with the calculated result value. 

- The mathematical expression to 16 bit CRC polynomial is given here. G(x) = x16 + x12 + x5 + 1";
BA_ "GenSigSendType" SG_ 2382594561 DATC_Crc5Val 4;
BA_ "GenSigStartValue" SG_ 2382594561 DATC_Crc5Val 65535;
BA_ "UserSigValidity" SG_ 2382594561 DATC_Crc5Val 3;
BA_ "Version" SG_ 2382594561 DATC_Crc5Val "18.11.08";
BA_ "Description" SG_ 2382594561 DATC_AlvCnt5Val "For the first transmission request for a data element the counter shall be initialized with 0 and shall be incremented by 1 for every subsequent send request. 

When the counter reaches the maximum value(0xFF), then it shall restart with 0 for the next send request";
BA_ "GenSigSendType" SG_ 2382594561 DATC_AlvCnt5Val 4;
BA_ "UserSigValidity" SG_ 2382594561 DATC_AlvCnt5Val 3;
BA_ "Version" SG_ 2382594561 DATC_AlvCnt5Val "18.11.08";
BA_ "Description" SG_ 2382594561 DATC_FrDrvModDis "This signal indicates MODE of HTR Control (VENT, B/L, FLOOR, MIX, DEF, AUTO Defog).

This signal occurs when MODE switch(button) is selected either manually or automatically.";
BA_ "GenSigSendType" SG_ 2382594561 DATC_FrDrvModDis 4;
BA_ "UserSigValidity" SG_ 2382594561 DATC_FrDrvModDis 7;
BA_REL_ "GenSigTimeoutTime" BU_SG_REL_ ATS SG_ 2382594561 DATC_FrDrvModDis 1500;
BA_ "Version" SG_ 2382594561 DATC_FrDrvModDis "18.11.06";
BA_ "Description" SG_ 2382594561 DATC_FrPassModDis "This signal indicates Passenger MODE of HTR Control

 (VENT, B/L, FLOOR, MIX, DEF, AUTO Defog)

This signal occurs when MODE switch(button) is selected either manually or automatically";
BA_ "GenSigSendType" SG_ 2382594561 DATC_FrPassModDis 4;
BA_ "UserSigValidity" SG_ 2382594561 DATC_FrPassModDis 7;
BA_REL_ "GenSigTimeoutTime" BU_SG_REL_ ATS SG_ 2382594561 DATC_FrPassModDis 1500;
BA_ "Version" SG_ 2382594561 DATC_FrPassModDis "18.11.05";
BA_ "Description" SG_ 2382594561 DATC_ClmtTxtPopupOSD "Climate Text Pop-up OSD";
BA_ "GenSigSendType" SG_ 2382594561 DATC_ClmtTxtPopupOSD 4;
BA_ "TimeoutValue" SG_ 2382594561 DATC_ClmtTxtPopupOSD "0x0";
BA_ "UserSigValidity" SG_ 2382594561 DATC_ClmtTxtPopupOSD 7;
BA_REL_ "GenSigTimeoutTime" BU_SG_REL_ ATS SG_ 2382594561 DATC_ClmtTxtPopupOSD 1500;
BA_ "Version" SG_ 2382594561 DATC_ClmtTxtPopupOSD "21.04.10";
BA_ "Description" SG_ 2382594561 DATC_TempDispUnitSta "This signal indicates Temp unit of HTR Control (℃, ℉).";
BA_ "GenSigSendType" SG_ 2382594561 DATC_TempDispUnitSta 4;
BA_ "UserSigValidity" SG_ 2382594561 DATC_TempDispUnitSta 6;
BA_REL_ "GenSigTimeoutTime" BU_SG_REL_ ATS SG_ 2382594561 DATC_TempDispUnitSta 1500;
BA_ "Version" SG_ 2382594561 DATC_TempDispUnitSta "17.11.00";
BA_ "Description" SG_ 2382594561 DATC_DrvAutoDis "This signal indicates AUTO Graphic On & Off.

This signal occurs when AUTO switch(button) is selected either manually or automatically.";
BA_ "GenSigSendType" SG_ 2382594561 DATC_DrvAutoDis 4;
BA_ "UserSigValidity" SG_ 2382594561 DATC_DrvAutoDis 6;
BA_REL_ "GenSigTimeoutTime" BU_SG_REL_ ATS SG_ 2382594561 DATC_DrvAutoDis 1500;
BA_ "Version" SG_ 2382594561 DATC_DrvAutoDis "17.11.00";
BA_ "Description" SG_ 2382594561 DATC_FrClmtScrnDis "This signal indicates that screen change to Climate Full screen.



This signal occurs when Climate switch(button) is selected manually.";
BA_ "GenSigSendType" SG_ 2382594561 DATC_FrClmtScrnDis 4;
BA_ "UserSigValidity" SG_ 2382594561 DATC_FrClmtScrnDis 6;
BA_REL_ "GenSigTimeoutTime" BU_SG_REL_ ATS SG_ 2382594561 DATC_FrClmtScrnDis 1500;
BA_ "Version" SG_ 2382594561 DATC_FrClmtScrnDis "17.11.00";
BA_ "Description" SG_ 2382594561 DATC_AcDis "This signal indicates A/C Graphic On & Off.

This signal occurs when A/C switch(button) is selected either manually or automatically.";
BA_ "GenSigSendType" SG_ 2382594561 DATC_AcDis 4;
BA_ "UserSigValidity" SG_ 2382594561 DATC_AcDis 6;
BA_REL_ "GenSigTimeoutTime" BU_SG_REL_ ATS SG_ 2382594561 DATC_AcDis 1500;
BA_ "Version" SG_ 2382594561 DATC_AcDis "17.11.00";
BA_ "Description" SG_ 2382594561 DATC_IntakeSta "This signal indicates Intake status (REC or FRE).";
BA_ "GenSigSendType" SG_ 2382594561 DATC_IntakeSta 4;
BA_ "UserSigValidity" SG_ 2382594561 DATC_IntakeSta 7;
BA_ "Version" SG_ 2382594561 DATC_IntakeSta "17.11.00";
BA_ "GenMsgSendType" BO_ 2424580353 0;
BA_ "VFrameFormat" BO_ 2424580353 1;
BA_ "Description" SG_ 2424580353 DATC_Crc12Val "The data area for CRC calculation is based on the data length (DLC) of the message DB.

The CRC shall be calculated over the entire data block (excluding the CRC bytes) including the user data, alive counter and Data ID

 

- CRC Polynomial (0x1021) , Initial Value : 0xFFFF, XOR value : 0x0000, Data ID : Message ID + 0xF800 

- The initial value is for CRC calculation and the message should be sent with the calculated result value. 

- The mathematical expression to 16 bit CRC polynomial is given here. G(x) = x16 + x12 + x5 + 1";
BA_ "GenSigSendType" SG_ 2424580353 DATC_Crc12Val 4;
BA_ "GenSigStartValue" SG_ 2424580353 DATC_Crc12Val 65535;
BA_ "UserSigValidity" SG_ 2424580353 DATC_Crc12Val 3;
BA_ "Version" SG_ 2424580353 DATC_Crc12Val "18.11.08";
BA_ "Description" SG_ 2424580353 DATC_AlvCnt12Val "For the first transmission request for a data element the counter shall be initialized with 0 and shall be incremented by 1 for every subsequent send request. 

When the counter reaches the maximum value(0xFF), then it shall restart with 0 for the next send request";
BA_ "GenSigSendType" SG_ 2424580353 DATC_AlvCnt12Val 4;
BA_ "UserSigValidity" SG_ 2424580353 DATC_AlvCnt12Val 3;
BA_ "Version" SG_ 2424580353 DATC_AlvCnt12Val "18.11.08";
BA_ "Description" SG_ 2424580353 DATC_StrWhlHtrSwReq "Steering Wheel heater S/W";
BA_ "GenSigSendType" SG_ 2424580353 DATC_StrWhlHtrSwReq 4;
BA_ "UserSigValidity" SG_ 2424580353 DATC_StrWhlHtrSwReq 7;
BA_ "Version" SG_ 2424580353 DATC_StrWhlHtrSwReq "17.11.00";
BA_ "Description" SG_ 2424580353 DATC_RrDefSw "Rear Defog Switch";
BA_ "GenSigSendType" SG_ 2424580353 DATC_RrDefSw 4;
BA_ "UserSigValidity" SG_ 2424580353 DATC_RrDefSw 3;
BA_ "Version" SG_ 2424580353 DATC_RrDefSw "19.04.06";
BA_ "Description" SG_ 2424580353 DATC_FLStOpReq "Left Seat warmer / Ventilation Operation request";
BA_ "GenSigSendType" SG_ 2424580353 DATC_FLStOpReq 4;
BA_ "UserSigValidity" SG_ 2424580353 DATC_FLStOpReq 7;
BA_REL_ "GenSigTimeoutTime" BU_SG_REL_ PSM SG_ 2424580353 DATC_FLStOpReq 1500;
BA_REL_ "GenSigTimeoutTime" BU_SG_REL_ APSM SG_ 2424580353 DATC_FLStOpReq 1500;
BA_REL_ "GenSigTimeoutTime" BU_SG_REL_ SHVU_RR SG_ 2424580353 DATC_FLStOpReq 1500;
BA_ "Version" SG_ 2424580353 DATC_FLStOpReq "17.11.00";
BA_ "Description" SG_ 2424580353 DATC_FRStOpReq "Right Seat Warmer / Ventilation Operation request";
BA_ "GenSigSendType" SG_ 2424580353 DATC_FRStOpReq 4;
BA_ "UserSigValidity" SG_ 2424580353 DATC_FRStOpReq 7;
BA_REL_ "GenSigTimeoutTime" BU_SG_REL_ PSM SG_ 2424580353 DATC_FRStOpReq 1500;
BA_REL_ "GenSigTimeoutTime" BU_SG_REL_ APSM SG_ 2424580353 DATC_FRStOpReq 1500;
BA_REL_ "GenSigTimeoutTime" BU_SG_REL_ SHVU_RR SG_ 2424580353 DATC_FRStOpReq 1500;
BA_ "Version" SG_ 2424580353 DATC_FRStOpReq "17.11.00";
BA_ "Description" SG_ 2424580353 DATC_RRStHtrSwReq "This signal indicate DATC Rear Right Seat Heater Switch Request";
BA_ "GenSigSendType" SG_ 2424580353 DATC_RRStHtrSwReq 4;
BA_ "UserSigValidity" SG_ 2424580353 DATC_RRStHtrSwReq 7;
BA_REL_ "GenSigTimeoutTime" BU_SG_REL_ RLPSM SG_ 2424580353 DATC_RRStHtrSwReq 1500;
BA_REL_ "GenSigTimeoutTime" BU_SG_REL_ RRPSM SG_ 2424580353 DATC_RRStHtrSwReq 1500;
BA_REL_ "GenSigTimeoutTime" BU_SG_REL_ RLHV SG_ 2424580353 DATC_RRStHtrSwReq 1500;
BA_REL_ "GenSigTimeoutTime" BU_SG_REL_ RRHV SG_ 2424580353 DATC_RRStHtrSwReq 1500;
BA_ "Version" SG_ 2424580353 DATC_RRStHtrSwReq "18.03.05";
BA_ "Description" SG_ 2424580353 DATC_RRStVentSwReq "This signal indicates DATC Rear Right Seat Ventilation Switch Request";
BA_ "GenSigSendType" SG_ 2424580353 DATC_RRStVentSwReq 4;
BA_ "UserSigValidity" SG_ 2424580353 DATC_RRStVentSwReq 7;
BA_REL_ "GenSigTimeoutTime" BU_SG_REL_ RLPSM SG_ 2424580353 DATC_RRStVentSwReq 1500;
BA_REL_ "GenSigTimeoutTime" BU_SG_REL_ RRPSM SG_ 2424580353 DATC_RRStVentSwReq 1500;
BA_REL_ "GenSigTimeoutTime" BU_SG_REL_ RLHV SG_ 2424580353 DATC_RRStVentSwReq 1500;
BA_REL_ "GenSigTimeoutTime" BU_SG_REL_ RRHV SG_ 2424580353 DATC_RRStVentSwReq 1500;
BA_ "Version" SG_ 2424580353 DATC_RRStVentSwReq "18.03.05";
BA_ "Description" SG_ 2424580353 DATC_RLStHtrSwReq "This signal indicates DATC Rear Left Seat Heater Switch Request";
BA_ "GenSigSendType" SG_ 2424580353 DATC_RLStHtrSwReq 4;
BA_ "UserSigValidity" SG_ 2424580353 DATC_RLStHtrSwReq 7;
BA_REL_ "GenSigTimeoutTime" BU_SG_REL_ RLPSM SG_ 2424580353 DATC_RLStHtrSwReq 1500;
BA_REL_ "GenSigTimeoutTime" BU_SG_REL_ RRPSM SG_ 2424580353 DATC_RLStHtrSwReq 1500;
BA_REL_ "GenSigTimeoutTime" BU_SG_REL_ RLHV SG_ 2424580353 DATC_RLStHtrSwReq 1500;
BA_REL_ "GenSigTimeoutTime" BU_SG_REL_ RRHV SG_ 2424580353 DATC_RLStHtrSwReq 1500;
BA_ "Version" SG_ 2424580353 DATC_RLStHtrSwReq "19.06.00";
BA_ "Description" SG_ 2424580353 DATC_RLStVentSwReq "This signal indicates DATC Rear Left Seat Ventilation Switch Request";
BA_ "GenSigSendType" SG_ 2424580353 DATC_RLStVentSwReq 4;
BA_ "UserSigValidity" SG_ 2424580353 DATC_RLStVentSwReq 7;
BA_REL_ "GenSigTimeoutTime" BU_SG_REL_ RLPSM SG_ 2424580353 DATC_RLStVentSwReq 1500;
BA_REL_ "GenSigTimeoutTime" BU_SG_REL_ RRPSM SG_ 2424580353 DATC_RLStVentSwReq 1500;
BA_REL_ "GenSigTimeoutTime" BU_SG_REL_ RLHV SG_ 2424580353 DATC_RLStVentSwReq 1500;
BA_REL_ "GenSigTimeoutTime" BU_SG_REL_ RRHV SG_ 2424580353 DATC_RLStVentSwReq 1500;
BA_ "Version" SG_ 2424580353 DATC_RLStVentSwReq "18.03.05";
BA_ "Description" SG_ 2424580353 DATC_WdwClsReq "This signal indicates Window Close Request.

(This signal is used for Closing Control of Window when AirClean Switch is selecting)";
BA_ "GenSigSendType" SG_ 2424580353 DATC_WdwClsReq 4;
BA_ "UserSigValidity" SG_ 2424580353 DATC_WdwClsReq 7;
BA_ "Version" SG_ 2424580353 DATC_WdwClsReq "19.07.06";
BA_ "Description" SG_ 2424580353 DATC_RRSyncDis "This signal indicates SYNC Graphic On & Off.

This signal occurs when Rear SYNC switch(button) is selected either manually or automatically.";
BA_ "GenSigSendType" SG_ 2424580353 DATC_RRSyncDis 4;
BA_ "UserSigValidity" SG_ 2424580353 DATC_RRSyncDis 7;
BA_REL_ "GenSigTimeoutTime" BU_SG_REL_ ATS SG_ 2424580353 DATC_RRSyncDis 1500;
BA_ "Version" SG_ 2424580353 DATC_RRSyncDis "19.12.00";
BA_ "GenMsgCycleTime" BO_ 2563126529 0;
BA_ "VFrameFormat" BO_ 2563126529 1;
BA_ "GenSigSendType" SG_ 2563126529 AMP_MTSVolumeStep 4;
BA_ "GenSigStartValue" SG_ 2563126529 AMP_MTSVolumeStep 255;
BA_ "UserSigValidity" SG_ 2563126529 AMP_MTSVolumeStep 1;
BA_REL_ "GenSigTimeoutTime" BU_SG_REL_ AMP SG_ 2563126529 AMP_MTSVolumeStep 0;
BA_ "NetworkRequest" SG_ 2563126529 AMP_MTSVolumeStep 0;
BA_ "Version" SG_ 2563126529 AMP_MTSVolumeStep "18.12.06";
BA_ "GenMsgCycleTime" BO_ 2390994433 0;
BA_ "VFrameFormat" BO_ 2390994433 1;
BA_ "GenSigSendType" SG_ 2390994433 AMP_Beep1VolumeStep 4;
BA_ "GenSigStartValue" SG_ 2390994433 AMP_Beep1VolumeStep 255;
BA_ "UserSigValidity" SG_ 2390994433 AMP_Beep1VolumeStep 1;
BA_REL_ "GenSigTimeoutTime" BU_SG_REL_ AMP SG_ 2390994433 AMP_Beep1VolumeStep 0;
BA_REL_ "GenSigTimeoutTime" BU_SG_REL_ ATS SG_ 2390994433 AMP_Beep1VolumeStep 0;
BA_ "NetworkRequest" SG_ 2390994433 AMP_Beep1VolumeStep 0;
BA_ "Version" SG_ 2390994433 AMP_Beep1VolumeStep "19.02.03";
BA_ "Description" SG_ 2390994433 AMP_Analog_OutputCh_Select "Command for Set Analog Output Channel to identify which Speakers will output Sound

- per bit, 0 means 'Not Output Channel' and 1 means 'Output Channel'

bit0 : FL / bit1 : FR / bit2 : RL / bit3 : RR / bit4 : CTR / bit5 : Surround L /

bit6 : Surround R / bit7 : SWF / bit8 : Headrest L / bit9 : Headrest R / bit10 : Loof L /

bit11 : Loof CTR / bit12 : Loof R / bit13~bit15 : Reserved

- This Signal's Feedback is AMP_Analog_OutputCh_State@AMP";
BA_ "GenSigSendType" SG_ 2390994433 AMP_Analog_OutputCh_Select 4;
BA_ "UserSigValidity" SG_ 2390994433 AMP_Analog_OutputCh_Select 1;
BA_REL_ "GenSigTimeoutTime" BU_SG_REL_ AMP SG_ 2390994433 AMP_Analog_OutputCh_Select 0;
BA_ "Version" SG_ 2390994433 AMP_Analog_OutputCh_Select "20.01.01";
BA_ "Description" SG_ 2390994433 AMP_Beep1_OutputCh_Select "Command for Set Beep1 Output Channel to identify which Speakers will output Sound

- per bit, 0 means 'Not Output Channel' and 1 means 'Output Channel'

bit0 : FL / bit1 : FR / bit2 : RL / bit3 : RR / bit4 : CTR / bit5 : Surround L /

bit6 : Surround R / bit7 : SWF / bit8 : Headrest L / bit9 : Headrest R / bit10 : Loof L /

bit11 : Loof CTR / bit12 : Loof R / bit13~bit15 : Reserved

- This Signal's Feedback is AMP_Beep1_OutputCh_State@AMP";
BA_ "GenSigSendType" SG_ 2390994433 AMP_Beep1_OutputCh_Select 4;
BA_ "GenSigStartValue" SG_ 2390994433 AMP_Beep1_OutputCh_Select 65535;
BA_ "UserSigValidity" SG_ 2390994433 AMP_Beep1_OutputCh_Select 1;
BA_REL_ "GenSigTimeoutTime" BU_SG_REL_ AMP SG_ 2390994433 AMP_Beep1_OutputCh_Select 0;
BA_ "Version" SG_ 2390994433 AMP_Beep1_OutputCh_Select "19.12.08";
BA_ "Description" SG_ 2390994433 AMP_Beep1KBDVolumeStep "Command for AVN keyboard Touch Beep Sound Volume Setting 

-range : 0 ~ max

-max : value of AMP_MaxBeep1VolumeState

This Signal's Feedback is AMP_Beep1KBDVolumeState@AMP";
BA_ "GenSigSendType" SG_ 2390994433 AMP_Beep1KBDVolumeStep 4;
BA_ "GenSigStartValue" SG_ 2390994433 AMP_Beep1KBDVolumeStep 255;
BA_ "UserSigValidity" SG_ 2390994433 AMP_Beep1KBDVolumeStep 1;
BA_REL_ "GenSigTimeoutTime" BU_SG_REL_ AMP SG_ 2390994433 AMP_Beep1KBDVolumeStep 0;
BA_ "Version" SG_ 2390994433 AMP_Beep1KBDVolumeStep "20.06.01";
BA_ "Description" SG_ 2390994433 AMP_SPDIF_OutputCh_Select "Command for Set SPDIF Output Channel to identify which Speakers will output Sound

- per bit, 0 means 'Not Output Channel' and 1 means 'Output Channel'

bit0 : FL / bit1 : FR / bit2 : RL / bit3 : RR / bit4 : CTR / bit5 : Surround L /

bit6 : Surround R / bit7 : SWF / bit8 : Headrest L / bit9 : Headrest R / bit10 : Loof L /

bit11 : Loof CTR / bit12 : Loof R / bit13~bit15 : Reserved

- This Signal's Feedback is AMP_SPDIF_OutputCh_State@AMP";
BA_ "GenSigSendType" SG_ 2390994433 AMP_SPDIF_OutputCh_Select 4;
BA_ "GenSigStartValue" SG_ 2390994433 AMP_SPDIF_OutputCh_Select 255;
BA_ "UserSigValidity" SG_ 2390994433 AMP_SPDIF_OutputCh_Select 1;
BA_REL_ "GenSigTimeoutTime" BU_SG_REL_ AMP SG_ 2390994433 AMP_SPDIF_OutputCh_Select 0;
BA_ "Version" SG_ 2390994433 AMP_SPDIF_OutputCh_Select "19.12.02";
BA_ "GenMsgSendType" BO_ 2479157761 0;
BA_ "GenMsgCycleTime" BO_ 2479157761 1000;
BA_ "VFrameFormat" BO_ 2479157761 1;
BA_ "GenSigSendType" SG_ 2479157761 HU_LanguageInfo 4;
BA_ "GenSigStartValue" SG_ 2479157761 HU_LanguageInfo 255;
BA_ "UserSigValidity" SG_ 2479157761 HU_LanguageInfo 1;
BA_REL_ "GenSigTimeoutTime" BU_SG_REL_ ATS SG_ 2479157761 HU_LanguageInfo 5000;
BA_ "NetworkRequest" SG_ 2479157761 HU_LanguageInfo 0;
BA_ "NetworkRequestHoldingTime" SG_ 2479157761 HU_LanguageInfo 5000;
BA_ "Version" SG_ 2479157761 HU_LanguageInfo "20.07.00";
BA_ "GenSigSendType" SG_ 2479157761 HU_MuteStatus 4;
BA_ "GenSigStartValue" SG_ 2479157761 HU_MuteStatus 3;
BA_ "UserSigValidity" SG_ 2479157761 HU_MuteStatus 1;
BA_ "NetworkRequest" SG_ 2479157761 HU_MuteStatus 0;
BA_ "Version" SG_ 2479157761 HU_MuteStatus "18.04.02";
BA_ "Description" SG_ 2479157761 HU_WelcomeReady "HU playback ready signal to play welcome animation video";
BA_ "GenSigSendType" SG_ 2479157761 HU_WelcomeReady 4;
BA_ "UserSigValidity" SG_ 2479157761 HU_WelcomeReady 0;
BA_ "Version" SG_ 2479157761 HU_WelcomeReady "19.04.06";
BA_ "GenSigSendType" SG_ 2479157761 HU_UsmSupport 4;
BA_ "GenSigStartValue" SG_ 2479157761 HU_UsmSupport 3;
BA_ "UserSigValidity" SG_ 2479157761 HU_UsmSupport 1;
BA_ "Version" SG_ 2479157761 HU_UsmSupport "18.04.02";
BA_ "GenSigSendType" SG_ 2479157761 HU_NaviStatus 4;
BA_ "UserSigValidity" SG_ 2479157761 HU_NaviStatus 1;
BA_REL_ "GenSigTimeoutTime" BU_SG_REL_ DSAU SG_ 2479157761 HU_NaviStatus 5000;
BA_ "NetworkRequest" SG_ 2479157761 HU_NaviStatus 0;
BA_ "Version" SG_ 2479157761 HU_NaviStatus "18.11.01";
BA_ "GenSigSendType" SG_ 2479157761 HU_NaviDisp 4;
BA_ "GenSigStartValue" SG_ 2479157761 HU_NaviDisp 3;
BA_ "UserSigValidity" SG_ 2479157761 HU_NaviDisp 1;
BA_ "NetworkRequest" SG_ 2479157761 HU_NaviDisp 0;
BA_ "Version" SG_ 2479157761 HU_NaviDisp "18.04.02";
BA_ "GenSigSendType" SG_ 2479157761 HU_BVM_Display_Message 4;
BA_ "GenSigStartValue" SG_ 2479157761 HU_BVM_Display_Message 7;
BA_ "UserSigValidity" SG_ 2479157761 HU_BVM_Display_Message 3;
BA_ "Version" SG_ 2479157761 HU_BVM_Display_Message "18.09.02";
BA_ "GenSigSendType" SG_ 2479157761 HU_SVM_View_Display 4;
BA_ "GenSigStartValue" SG_ 2479157761 HU_SVM_View_Display 31;
BA_ "UserSigValidity" SG_ 2479157761 HU_SVM_View_Display 3;
BA_ "Version" SG_ 2479157761 HU_SVM_View_Display "18.04.02";
BA_ "GenSigSendType" SG_ 2479157761 HU_NaviCamSettingStatus 4;
BA_ "GenSigStartValue" SG_ 2479157761 HU_NaviCamSettingStatus 255;
BA_ "UserSigValidity" SG_ 2479157761 HU_NaviCamSettingStatus 1;
BA_ "NetworkRequest" SG_ 2479157761 HU_NaviCamSettingStatus 0;
BA_ "Version" SG_ 2479157761 HU_NaviCamSettingStatus "18.09.02";
BA_ "Description" SG_ 2479157761 HU_EVSupport "Notification whether EV function support or not.";
BA_ "GenSigSendType" SG_ 2479157761 HU_EVSupport 4;
BA_ "GenSigStartValue" SG_ 2479157761 HU_EVSupport 3;
BA_ "UserSigValidity" SG_ 2479157761 HU_EVSupport 7;
BA_ "Version" SG_ 2479157761 HU_EVSupport "19.08.06";
BA_ "Description" SG_ 2479157761 HU_AutoBrightState_New "HU Display Brightness State(When automatically adjusted)";
BA_ "GenSigSendType" SG_ 2479157761 HU_AutoBrightState_New 4;
BA_ "UserSigValidity" SG_ 2479157761 HU_AutoBrightState_New 0;
BA_ "Version" SG_ 2479157761 HU_AutoBrightState_New "20.09.01";
BA_ "GenSigSendType" SG_ 2479157761 HU_VolumeStatus 4;
BA_ "GenSigStartValue" SG_ 2479157761 HU_VolumeStatus 63;
BA_ "UserSigValidity" SG_ 2479157761 HU_VolumeStatus 1;
BA_ "NetworkRequest" SG_ 2479157761 HU_VolumeStatus 0;
BA_ "Version" SG_ 2479157761 HU_VolumeStatus "18.04.02";
BA_ "GenMsgSendType" BO_ 2298626049 0;
BA_ "VFrameFormat" BO_ 2298626049 1;
BA_ "Description" SG_ 2298626049 HU_DSW_HeadPoseYawStat "Yaw angle state of driver’s head pose";
BA_ "GenSigSendType" SG_ 2298626049 HU_DSW_HeadPoseYawStat 4;
BA_ "GenSigStartValue" SG_ 2298626049 HU_DSW_HeadPoseYawStat 31;
BA_ "UserSigValidity" SG_ 2298626049 HU_DSW_HeadPoseYawStat 1;
BA_ "Version" SG_ 2298626049 HU_DSW_HeadPoseYawStat "19.10.06";
BA_ "Description" SG_ 2298626049 HU_DSW_EyeOpenStat "Driver’s eye open state (0: fully closed, 100%: fully opened)";
BA_ "GenSigSendType" SG_ 2298626049 HU_DSW_EyeOpenStat 4;
BA_ "GenSigStartValue" SG_ 2298626049 HU_DSW_EyeOpenStat 7;
BA_ "UserSigValidity" SG_ 2298626049 HU_DSW_EyeOpenStat 1;
BA_ "Version" SG_ 2298626049 HU_DSW_EyeOpenStat "19.10.06";
BA_ "Description" SG_ 2298626049 HU_DSW_RightEyeOpenStat "Right Eye Open State (0: fully closed, 100%: fully opend)";
BA_ "GenSigSendType" SG_ 2298626049 HU_DSW_RightEyeOpenStat 4;
BA_ "GenSigStartValue" SG_ 2298626049 HU_DSW_RightEyeOpenStat 31;
BA_ "UserSigValidity" SG_ 2298626049 HU_DSW_RightEyeOpenStat 1;
BA_ "Version" SG_ 2298626049 HU_DSW_RightEyeOpenStat "19.10.06";
BA_ "Description" SG_ 2298626049 HU_DSW_LatestNumBlink "현재 송출 주기[200ms] 에서의 blink 횟수, blink 판단 이 모호한 경계구간인 경우, 다음 송출신호에 반영되어 데이터의 loss가 발생하지 않도록 함";
BA_ "GenSigSendType" SG_ 2298626049 HU_DSW_LatestNumBlink 4;
BA_ "GenSigStartValue" SG_ 2298626049 HU_DSW_LatestNumBlink 7;
BA_ "UserSigValidity" SG_ 2298626049 HU_DSW_LatestNumBlink 1;
BA_ "Version" SG_ 2298626049 HU_DSW_LatestNumBlink "19.10.06";
BA_ "Description" SG_ 2298626049 HU_DSW_HeadPosePitchStat "Pitch angle state of driver’s head pose";
BA_ "GenSigSendType" SG_ 2298626049 HU_DSW_HeadPosePitchStat 4;
BA_ "GenSigStartValue" SG_ 2298626049 HU_DSW_HeadPosePitchStat 15;
BA_ "UserSigValidity" SG_ 2298626049 HU_DSW_HeadPosePitchStat 1;
BA_ "Version" SG_ 2298626049 HU_DSW_HeadPosePitchStat "19.10.06";
BA_ "Description" SG_ 2298626049 HU_DSW_FaceDectStat "Driver’s face detection state";
BA_ "GenSigSendType" SG_ 2298626049 HU_DSW_FaceDectStat 4;
BA_ "GenSigStartValue" SG_ 2298626049 HU_DSW_FaceDectStat 3;
BA_ "UserSigValidity" SG_ 2298626049 HU_DSW_FaceDectStat 1;
BA_ "Version" SG_ 2298626049 HU_DSW_FaceDectStat "19.10.06";
BA_ "Description" SG_ 2298626049 HU_DSW_CamBlckdSta "Interior view camera blockage";
BA_ "GenSigSendType" SG_ 2298626049 HU_DSW_CamBlckdSta 4;
BA_ "GenSigStartValue" SG_ 2298626049 HU_DSW_CamBlckdSta 3;
BA_ "UserSigValidity" SG_ 2298626049 HU_DSW_CamBlckdSta 1;
BA_ "Version" SG_ 2298626049 HU_DSW_CamBlckdSta "19.10.06";
BA_ "Description" SG_ 2298626049 HU_DSW_EyeGazePitchStat "Pitch angle state of driver’s eye gaze";
BA_ "GenSigSendType" SG_ 2298626049 HU_DSW_EyeGazePitchStat 4;
BA_ "GenSigStartValue" SG_ 2298626049 HU_DSW_EyeGazePitchStat 15;
BA_ "UserSigValidity" SG_ 2298626049 HU_DSW_EyeGazePitchStat 1;
BA_ "Version" SG_ 2298626049 HU_DSW_EyeGazePitchStat "19.10.06";
BA_ "Description" SG_ 2298626049 HU_DSW_FakeStat "Real face or photo (fake)";
BA_ "GenSigSendType" SG_ 2298626049 HU_DSW_FakeStat 4;
BA_ "GenSigStartValue" SG_ 2298626049 HU_DSW_FakeStat 3;
BA_ "UserSigValidity" SG_ 2298626049 HU_DSW_FakeStat 1;
BA_ "Version" SG_ 2298626049 HU_DSW_FakeStat "19.10.06";
BA_ "Description" SG_ 2298626049 HU_DSW_DistWrngTypSta "Warning type";
BA_ "GenSigSendType" SG_ 2298626049 HU_DSW_DistWrngTypSta 4;
BA_ "GenSigStartValue" SG_ 2298626049 HU_DSW_DistWrngTypSta 3;
BA_ "UserSigValidity" SG_ 2298626049 HU_DSW_DistWrngTypSta 1;
BA_ "Version" SG_ 2298626049 HU_DSW_DistWrngTypSta "19.10.06";
BA_ "Description" SG_ 2298626049 HU_DSW_PerclosStat "PERCLOS (percentage of eye closure)";
BA_ "GenSigSendType" SG_ 2298626049 HU_DSW_PerclosStat 4;
BA_ "GenSigStartValue" SG_ 2298626049 HU_DSW_PerclosStat 3;
BA_ "UserSigValidity" SG_ 2298626049 HU_DSW_PerclosStat 1;
BA_ "Version" SG_ 2298626049 HU_DSW_PerclosStat "19.10.06";
BA_ "Description" SG_ 2298626049 HU_DSW_LongBlinkStat "Long blink repeat pattern";
BA_ "GenSigSendType" SG_ 2298626049 HU_DSW_LongBlinkStat 4;
BA_ "GenSigStartValue" SG_ 2298626049 HU_DSW_LongBlinkStat 3;
BA_ "UserSigValidity" SG_ 2298626049 HU_DSW_LongBlinkStat 1;
BA_ "Version" SG_ 2298626049 HU_DSW_LongBlinkStat "19.10.06";
BA_ "Description" SG_ 2298626049 HU_DSW_TalkStat "Driver talking type";
BA_ "GenSigSendType" SG_ 2298626049 HU_DSW_TalkStat 4;
BA_ "GenSigStartValue" SG_ 2298626049 HU_DSW_TalkStat 3;
BA_ "UserSigValidity" SG_ 2298626049 HU_DSW_TalkStat 1;
BA_ "Version" SG_ 2298626049 HU_DSW_TalkStat "19.10.06";
BA_ "Description" SG_ 2298626049 HU_DSW_DistFtgWrngSta "Distraction or fatigue/drowsiness warning based on head pose, eye gaze, and drowsiness.

This signal will remain on for 20 seconds to delay the warning if it overlaps with other system warnings.";
BA_ "GenSigSendType" SG_ 2298626049 HU_DSW_DistFtgWrngSta 4;
BA_ "GenSigStartValue" SG_ 2298626049 HU_DSW_DistFtgWrngSta 3;
BA_ "UserSigValidity" SG_ 2298626049 HU_DSW_DistFtgWrngSta 1;
BA_REL_ "GenSigTimeoutTime" BU_SG_REL_ DSAU SG_ 2298626049 HU_DSW_DistFtgWrngSta 1500;
BA_ "Version" SG_ 2298626049 HU_DSW_DistFtgWrngSta "19.10.06";
BA_ "Description" SG_ 2298626049 HU_DSW_EyeGazeYawStat "Yaw angle state of driver’s eye gaze";
BA_ "GenSigSendType" SG_ 2298626049 HU_DSW_EyeGazeYawStat 4;
BA_ "GenSigStartValue" SG_ 2298626049 HU_DSW_EyeGazeYawStat 31;
BA_ "UserSigValidity" SG_ 2298626049 HU_DSW_EyeGazeYawStat 1;
BA_ "Version" SG_ 2298626049 HU_DSW_EyeGazeYawStat "19.10.06";
BA_ "Description" SG_ 2298626049 HU_DSW_SymSta "DSW System State : Include signal to check the status of the function, including options and interior view camera malfunction";
BA_ "GenSigSendType" SG_ 2298626049 HU_DSW_SymSta 4;
BA_ "GenSigStartValue" SG_ 2298626049 HU_DSW_SymSta 7;
BA_ "UserSigValidity" SG_ 2298626049 HU_DSW_SymSta 1;
BA_REL_ "GenSigTimeoutTime" BU_SG_REL_ DSAU SG_ 2298626049 HU_DSW_SymSta 1500;
BA_ "Version" SG_ 2298626049 HU_DSW_SymSta "19.10.06";
BA_ "Description" SG_ 2298626049 HU_DSW_EyeStat "현재 eye open/close 상태";
BA_ "GenSigSendType" SG_ 2298626049 HU_DSW_EyeStat 4;
BA_ "GenSigStartValue" SG_ 2298626049 HU_DSW_EyeStat 3;
BA_ "UserSigValidity" SG_ 2298626049 HU_DSW_EyeStat 1;
BA_ "Version" SG_ 2298626049 HU_DSW_EyeStat "19.10.06";
BA_ "Description" SG_ 2298626049 HU_DSW_LatestLongClosedStat "현재 [4]초 이상 연속적으로 눈 감음(eye closed) 상태인지 여부";
BA_ "GenSigSendType" SG_ 2298626049 HU_DSW_LatestLongClosedStat 4;
BA_ "GenSigStartValue" SG_ 2298626049 HU_DSW_LatestLongClosedStat 3;
BA_ "UserSigValidity" SG_ 2298626049 HU_DSW_LatestLongClosedStat 1;
BA_ "Version" SG_ 2298626049 HU_DSW_LatestLongClosedStat "19.10.06";
BA_ "Description" SG_ 2298626049 HU_DSW_LeftEyeOpenStat "Left Eye Open State (0: fully closed, 100%: fully opend)";
BA_ "GenSigSendType" SG_ 2298626049 HU_DSW_LeftEyeOpenStat 4;
BA_ "GenSigStartValue" SG_ 2298626049 HU_DSW_LeftEyeOpenStat 31;
BA_ "UserSigValidity" SG_ 2298626049 HU_DSW_LeftEyeOpenStat 1;
BA_ "Version" SG_ 2298626049 HU_DSW_LeftEyeOpenStat "19.10.06";
BA_ "GenMsgCycleTime" BO_ 2462365953 0;
BA_ "VFrameFormat" BO_ 2462365953 1;
BA_ "GenSigSendType" SG_ 2462365953 SEG_V2_3_Offset 4;
BA_ "UserSigValidity" SG_ 2462365953 SEG_V2_3_Offset 3;
BA_REL_ "GenSigTimeoutTime" BU_SG_REL_ DSAU SG_ 2462365953 SEG_V2_3_Offset 0;
BA_ "Version" SG_ 2462365953 SEG_V2_3_Offset "20.03.06";
BA_ "GenSigSendType" SG_ 2462365953 SEG_V2_3_PathIndex 4;
BA_ "UserSigValidity" SG_ 2462365953 SEG_V2_3_PathIndex 3;
BA_ "Version" SG_ 2462365953 SEG_V2_3_PathIndex "20.03.06";
BA_ "GenSigSendType" SG_ 2462365953 SEG_V2_3_CalculatedRoute 4;
BA_ "GenSigStartValue" SG_ 2462365953 SEG_V2_3_CalculatedRoute 2;
BA_ "UserSigValidity" SG_ 2462365953 SEG_V2_3_CalculatedRoute 3;
BA_REL_ "GenSigTimeoutTime" BU_SG_REL_ DSAU SG_ 2462365953 SEG_V2_3_CalculatedRoute 0;
BA_ "Version" SG_ 2462365953 SEG_V2_3_CalculatedRoute "20.03.06";
BA_ "GenSigSendType" SG_ 2462365953 SEG_V2_3_FuncRoadClass 4;
BA_ "UserSigValidity" SG_ 2462365953 SEG_V2_3_FuncRoadClass 3;
BA_REL_ "GenSigTimeoutTime" BU_SG_REL_ DSAU SG_ 2462365953 SEG_V2_3_FuncRoadClass 0;
BA_ "Version" SG_ 2462365953 SEG_V2_3_FuncRoadClass "20.03.06";
BA_ "GenSigSendType" SG_ 2462365953 SEG_V2_3_SpeedLimit 4;
BA_ "UserSigValidity" SG_ 2462365953 SEG_V2_3_SpeedLimit 3;
BA_ "Version" SG_ 2462365953 SEG_V2_3_SpeedLimit "20.03.06";
BA_ "GenSigSendType" SG_ 2462365953 SEG_V2_3_FormOfWay 4;
BA_ "UserSigValidity" SG_ 2462365953 SEG_V2_3_FormOfWay 3;
BA_REL_ "GenSigTimeoutTime" BU_SG_REL_ DSAU SG_ 2462365953 SEG_V2_3_FormOfWay 0;
BA_ "Version" SG_ 2462365953 SEG_V2_3_FormOfWay "20.03.06";
BA_ "GenSigSendType" SG_ 2462365953 SEG_V2_3_DirectionLanes 4;
BA_ "UserSigValidity" SG_ 2462365953 SEG_V2_3_DirectionLanes 3;
BA_ "Version" SG_ 2462365953 SEG_V2_3_DirectionLanes "20.03.06";
BA_ "GenSigSendType" SG_ 2462365953 SEG_V2_3_SpeedLimitUnder5 4;
BA_ "UserSigValidity" SG_ 2462365953 SEG_V2_3_SpeedLimitUnder5 3;
BA_ "Version" SG_ 2462365953 SEG_V2_3_SpeedLimitUnder5 "20.03.06";
BA_ "Description" SG_ 2462365953 SEG_V2_3_DividedRoad "Segment Divided Road Information";
BA_ "GenSigSendType" SG_ 2462365953 SEG_V2_3_DividedRoad 4;
BA_ "GenSigStartValue" SG_ 2462365953 SEG_V2_3_DividedRoad 2;
BA_ "UserSigValidity" SG_ 2462365953 SEG_V2_3_DividedRoad 3;
BA_ "Version" SG_ 2462365953 SEG_V2_3_DividedRoad "20.09.00";
BA_ "GenSigSendType" SG_ 2462365953 SEG_V2_3_CyclicCounter 4;
BA_ "UserSigValidity" SG_ 2462365953 SEG_V2_3_CyclicCounter 3;
BA_REL_ "GenSigTimeoutTime" BU_SG_REL_ DSAU SG_ 2462365953 SEG_V2_3_CyclicCounter 0;
BA_ "Version" SG_ 2462365953 SEG_V2_3_CyclicCounter "20.03.06";
BA_ "GenSigSendType" SG_ 2462365953 SEG_V2_3_Retransmission 4;
BA_ "UserSigValidity" SG_ 2462365953 SEG_V2_3_Retransmission 3;
BA_ "Version" SG_ 2462365953 SEG_V2_3_Retransmission "20.03.06";
BA_ "GenMsgSendType" BO_ 1076 0;
BA_ "GenSigSendType" SG_ 1076 IAU_ProfileIDRVal 4;
BA_ "UserSigValidity" SG_ 1076 IAU_ProfileIDRVal 0;
BA_REL_ "GenSigTimeoutTime" BU_SG_REL_ PSM SG_ 1076 IAU_ProfileIDRVal 1500;
BA_REL_ "GenSigTimeoutTime" BU_SG_REL_ FPM SG_ 1076 IAU_ProfileIDRVal 1500;
BA_ "NetworkRequest" SG_ 1076 IAU_ProfileIDRVal 0;
BA_ "NetworkRequestHoldingTime" SG_ 1076 IAU_ProfileIDRVal 5000;
BA_ "Version" SG_ 1076 IAU_ProfileIDRVal "20.05.02";
BA_ "Description" SG_ 1076 IAU_ISKLearnState "This signal is State of IAU Learning";
BA_ "GenSigSendType" SG_ 1076 IAU_ISKLearnState 4;
BA_ "UserSigValidity" SG_ 1076 IAU_ISKLearnState 0;
BA_ "NetworkRequest" SG_ 1076 IAU_ISKLearnState 0;
BA_ "NetworkRequestHoldingTime" SG_ 1076 IAU_ISKLearnState 5000;
BA_ "Version" SG_ 1076 IAU_ISKLearnState "18.08.05";
BA_ "GenSigSendType" SG_ 1076 IAU_DigitalKeyProcessingSta 4;
BA_ "UserSigValidity" SG_ 1076 IAU_DigitalKeyProcessingSta 3;
BA_ "NetworkRequest" SG_ 1076 IAU_DigitalKeyProcessingSta 0;
BA_ "NetworkRequestHoldingTime" SG_ 1076 IAU_DigitalKeyProcessingSta 5000;
BA_ "Version" SG_ 1076 IAU_DigitalKeyProcessingSta "20.11.02";
BA_ "Description" SG_ 1076 IAU_DigitalKeyExit "Digital Key USM setting Exit Condition";
BA_ "GenSigSendType" SG_ 1076 IAU_DigitalKeyExit 4;
BA_ "UserSigValidity" SG_ 1076 IAU_DigitalKeyExit 3;
BA_ "NetworkRequest" SG_ 1076 IAU_DigitalKeyExit 0;
BA_ "NetworkRequestHoldingTime" SG_ 1076 IAU_DigitalKeyExit 5000;
BA_ "Version" SG_ 1076 IAU_DigitalKeyExit "20.09.00";
BA_ "GenSigSendType" SG_ 1076 IAU_DigitalKeyEnblRVal 4;
BA_ "UserSigValidity" SG_ 1076 IAU_DigitalKeyEnblRVal 0;
BA_ "NetworkRequest" SG_ 1076 IAU_DigitalKeyEnblRVal 0;
BA_ "NetworkRequestHoldingTime" SG_ 1076 IAU_DigitalKeyEnblRVal 5000;
BA_ "Version" SG_ 1076 IAU_DigitalKeyEnblRVal "20.05.02";
BA_ "GenSigSendType" SG_ 1076 IAU_OwnerPhnRegRVal 4;
BA_ "UserSigValidity" SG_ 1076 IAU_OwnerPhnRegRVal 0;
BA_ "NetworkRequest" SG_ 1076 IAU_OwnerPhnRegRVal 0;
BA_ "NetworkRequestHoldingTime" SG_ 1076 IAU_OwnerPhnRegRVal 5000;
BA_ "Version" SG_ 1076 IAU_OwnerPhnRegRVal "20.05.02";
BA_ "GenSigSendType" SG_ 1076 IAU_NFCCard1RegRVal 4;
BA_ "UserSigValidity" SG_ 1076 IAU_NFCCard1RegRVal 0;
BA_ "NetworkRequest" SG_ 1076 IAU_NFCCard1RegRVal 0;
BA_ "NetworkRequestHoldingTime" SG_ 1076 IAU_NFCCard1RegRVal 5000;
BA_ "Version" SG_ 1076 IAU_NFCCard1RegRVal "17.12.08";
BA_ "GenSigSendType" SG_ 1076 IAU_RdyToSendAuthDataSta 4;
BA_ "UserSigValidity" SG_ 1076 IAU_RdyToSendAuthDataSta 0;
BA_ "NetworkRequest" SG_ 1076 IAU_RdyToSendAuthDataSta 0;
BA_ "NetworkRequestHoldingTime" SG_ 1076 IAU_RdyToSendAuthDataSta 5000;
BA_ "Version" SG_ 1076 IAU_RdyToSendAuthDataSta "17.12.08";
BA_ "Description" SG_ 1076 IAU_DISPWrng "This siganl warning from IAU";
BA_ "GenSigSendType" SG_ 1076 IAU_DISPWrng 4;
BA_ "UserSigValidity" SG_ 1076 IAU_DISPWrng 0;
BA_ "NetworkRequest" SG_ 1076 IAU_DISPWrng 0;
BA_ "NetworkRequestHoldingTime" SG_ 1076 IAU_DISPWrng 5000;
BA_ "Version" SG_ 1076 IAU_DISPWrng "20.08.07";
BA_ "Description" SG_ 1076 IAU_DigitalKey2Opt "This signal describe Digital Key capability";
BA_ "GenSigSendType" SG_ 1076 IAU_DigitalKey2Opt 4;
BA_ "UserSigValidity" SG_ 1076 IAU_DigitalKey2Opt 0;
BA_ "NetworkRequest" SG_ 1076 IAU_DigitalKey2Opt 0;
BA_ "NetworkRequestHoldingTime" SG_ 1076 IAU_DigitalKey2Opt 5000;
BA_ "Version" SG_ 1076 IAU_DigitalKey2Opt "20.08.00";
BA_ "Description" SG_ 1076 IAUwFPMLearnState "This signal indicates learning process stste between IAU and FPM";
BA_ "GenSigSendType" SG_ 1076 IAUwFPMLearnState 4;
BA_ "UserSigValidity" SG_ 1076 IAUwFPMLearnState 0;
BA_REL_ "GenSigTimeoutTime" BU_SG_REL_ FPM SG_ 1076 IAUwFPMLearnState 1500;
BA_ "NetworkRequest" SG_ 1076 IAUwFPMLearnState 0;
BA_ "NetworkRequestHoldingTime" SG_ 1076 IAUwFPMLearnState 5000;
BA_ "Version" SG_ 1076 IAUwFPMLearnState "20.04.05";
BA_ "GenMsgCycleTime" BO_ 1227 0;
BA_ "Description" SG_ 1227 DrvIMS_MemoryP1Req "-(Old)C_MEMP1CMD";
BA_ "GenSigSendType" SG_ 1227 DrvIMS_MemoryP1Req 4;
BA_ "UserSigValidity" SG_ 1227 DrvIMS_MemoryP1Req 0;
BA_REL_ "GenSigTimeoutTime" BU_SG_REL_ CGW_CCU SG_ 1227 DrvIMS_MemoryP1Req 0;
BA_ "NetworkRequest" SG_ 1227 DrvIMS_MemoryP1Req 0;
BA_ "NetworkRequestHoldingTime" SG_ 1227 DrvIMS_MemoryP1Req 5000;
BA_ "Version" SG_ 1227 DrvIMS_MemoryP1Req "17.11.00";
BA_ "GenSigSendType" SG_ 1227 DrvIMS_PlyBckP2Req 4;
BA_ "UserSigValidity" SG_ 1227 DrvIMS_PlyBckP2Req 0;
BA_REL_ "GenSigTimeoutTime" BU_SG_REL_ CGW_CCU SG_ 1227 DrvIMS_PlyBckP2Req 0;
BA_ "NetworkRequest" SG_ 1227 DrvIMS_PlyBckP2Req 0;
BA_ "NetworkRequestHoldingTime" SG_ 1227 DrvIMS_PlyBckP2Req 5000;
BA_ "Version" SG_ 1227 DrvIMS_PlyBckP2Req "17.11.00";
BA_ "Description" SG_ 1227 DrvIMS_PlyBckP3Req "PLAY IMS3";
BA_ "GenSigSendType" SG_ 1227 DrvIMS_PlyBckP3Req 4;
BA_ "UserSigValidity" SG_ 1227 DrvIMS_PlyBckP3Req 0;
BA_REL_ "GenSigTimeoutTime" BU_SG_REL_ CGW_CCU SG_ 1227 DrvIMS_PlyBckP3Req 0;
BA_ "NetworkRequest" SG_ 1227 DrvIMS_PlyBckP3Req 0;
BA_ "NetworkRequestHoldingTime" SG_ 1227 DrvIMS_PlyBckP3Req 5000;
BA_ "Version" SG_ 1227 DrvIMS_PlyBckP3Req "17.11.00";
BA_ "Description" SG_ 1227 DrvIMS_PlyBckStpReq "This signal is used to stop during playback";
BA_ "GenSigSendType" SG_ 1227 DrvIMS_PlyBckStpReq 4;
BA_ "UserSigValidity" SG_ 1227 DrvIMS_PlyBckStpReq 0;
BA_REL_ "GenSigTimeoutTime" BU_SG_REL_ CGW_CCU SG_ 1227 DrvIMS_PlyBckStpReq 0;
BA_ "NetworkRequest" SG_ 1227 DrvIMS_PlyBckStpReq 0;
BA_ "NetworkRequestHoldingTime" SG_ 1227 DrvIMS_PlyBckStpReq 5000;
BA_ "Version" SG_ 1227 DrvIMS_PlyBckStpReq "17.11.00";
BA_ "Description" SG_ 1227 SmrtIMS_PlyBckReq "Signal for Health Care IMS Playback DB Number";
BA_ "GenSigSendType" SG_ 1227 SmrtIMS_PlyBckReq 4;
BA_ "UserSigValidity" SG_ 1227 SmrtIMS_PlyBckReq 0;
BA_REL_ "GenSigTimeoutTime" BU_SG_REL_ CGW_CCU SG_ 1227 SmrtIMS_PlyBckReq 0;
BA_ "NetworkRequest" SG_ 1227 SmrtIMS_PlyBckReq 0;
BA_ "NetworkRequestHoldingTime" SG_ 1227 SmrtIMS_PlyBckReq 5000;
BA_ "Version" SG_ 1227 SmrtIMS_PlyBckReq "21.07.05";
BA_ "Description" SG_ 1227 DrvIMS_MemoryP2Req "-(Old)C_MEMP2CMD";
BA_ "GenSigSendType" SG_ 1227 DrvIMS_MemoryP2Req 4;
BA_ "UserSigValidity" SG_ 1227 DrvIMS_MemoryP2Req 0;
BA_REL_ "GenSigTimeoutTime" BU_SG_REL_ CGW_CCU SG_ 1227 DrvIMS_MemoryP2Req 0;
BA_ "NetworkRequest" SG_ 1227 DrvIMS_MemoryP2Req 0;
BA_ "NetworkRequestHoldingTime" SG_ 1227 DrvIMS_MemoryP2Req 5000;
BA_ "Version" SG_ 1227 DrvIMS_MemoryP2Req "17.11.00";
BA_ "Description" SG_ 1227 SmrtIMS_ImgDBVal "-(Old)C_SmartIMSImageDB";
BA_ "GenSigSendType" SG_ 1227 SmrtIMS_ImgDBVal 4;
BA_ "UserSigValidity" SG_ 1227 SmrtIMS_ImgDBVal 0;
BA_REL_ "GenSigTimeoutTime" BU_SG_REL_ CGW_CCU SG_ 1227 SmrtIMS_ImgDBVal 0;
BA_ "NetworkRequest" SG_ 1227 SmrtIMS_ImgDBVal 0;
BA_ "NetworkRequestHoldingTime" SG_ 1227 SmrtIMS_ImgDBVal 5000;
BA_ "Version" SG_ 1227 SmrtIMS_ImgDBVal "17.11.00";
BA_ "Description" SG_ 1227 SmrtIMS_PlyBckStpReq "Health Care IMS On/Off Flag";
BA_ "GenSigSendType" SG_ 1227 SmrtIMS_PlyBckStpReq 4;
BA_ "UserSigValidity" SG_ 1227 SmrtIMS_PlyBckStpReq 0;
BA_REL_ "GenSigTimeoutTime" BU_SG_REL_ CGW_CCU SG_ 1227 SmrtIMS_PlyBckStpReq 0;
BA_ "NetworkRequest" SG_ 1227 SmrtIMS_PlyBckStpReq 0;
BA_ "NetworkRequestHoldingTime" SG_ 1227 SmrtIMS_PlyBckStpReq 5000;
BA_ "Version" SG_ 1227 SmrtIMS_PlyBckStpReq "17.11.00";
BA_ "Description" SG_ 1227 DrvIMS_MemoryP3Req "Memory IMS3";
BA_ "GenSigSendType" SG_ 1227 DrvIMS_MemoryP3Req 4;
BA_ "UserSigValidity" SG_ 1227 DrvIMS_MemoryP3Req 0;
BA_REL_ "GenSigTimeoutTime" BU_SG_REL_ CGW_CCU SG_ 1227 DrvIMS_MemoryP3Req 0;
BA_ "NetworkRequest" SG_ 1227 DrvIMS_MemoryP3Req 0;
BA_ "NetworkRequestHoldingTime" SG_ 1227 DrvIMS_MemoryP3Req 5000;
BA_ "Version" SG_ 1227 DrvIMS_MemoryP3Req "17.11.00";
BA_ "Description" SG_ 1227 SmrtIMS_EnterSwSta "-(Old)C_SmartIMSOn";
BA_ "GenSigSendType" SG_ 1227 SmrtIMS_EnterSwSta 4;
BA_ "UserSigValidity" SG_ 1227 SmrtIMS_EnterSwSta 0;
BA_REL_ "GenSigTimeoutTime" BU_SG_REL_ CGW_CCU SG_ 1227 SmrtIMS_EnterSwSta 0;
BA_ "NetworkRequest" SG_ 1227 SmrtIMS_EnterSwSta 0;
BA_ "NetworkRequestHoldingTime" SG_ 1227 SmrtIMS_EnterSwSta 5000;
BA_ "Version" SG_ 1227 SmrtIMS_EnterSwSta "17.11.00";
BA_ "Description" SG_ 1227 DrvIMS_BzrReq "IMS 부져음을 클러스터 스피커에서 출력하기 위한 시그널";
BA_ "GenSigSendType" SG_ 1227 DrvIMS_BzrReq 4;
BA_ "UserSigValidity" SG_ 1227 DrvIMS_BzrReq 0;
BA_REL_ "GenSigTimeoutTime" BU_SG_REL_ CGW_CCU SG_ 1227 DrvIMS_BzrReq 0;
BA_ "NetworkRequest" SG_ 1227 DrvIMS_BzrReq 0;
BA_ "NetworkRequestHoldingTime" SG_ 1227 DrvIMS_BzrReq 5000;
BA_ "Version" SG_ 1227 DrvIMS_BzrReq "17.11.00";
BA_ "Description" SG_ 1227 DrvIMS_ErrConWmgDis "IMS 기억/재생 조건 에러 출력 시그널";
BA_ "GenSigSendType" SG_ 1227 DrvIMS_ErrConWmgDis 4;
BA_ "UserSigValidity" SG_ 1227 DrvIMS_ErrConWmgDis 0;
BA_REL_ "GenSigTimeoutTime" BU_SG_REL_ CGW_CCU SG_ 1227 DrvIMS_ErrConWmgDis 0;
BA_ "NetworkRequest" SG_ 1227 DrvIMS_ErrConWmgDis 0;
BA_ "NetworkRequestHoldingTime" SG_ 1227 DrvIMS_ErrConWmgDis 5000;
BA_ "Version" SG_ 1227 DrvIMS_ErrConWmgDis "18.07.01";
BA_ "Description" SG_ 1227 DrvIMS_MemorySetEnaSta "-(Old)C_MEMENB";
BA_ "GenSigSendType" SG_ 1227 DrvIMS_MemorySetEnaSta 4;
BA_ "UserSigValidity" SG_ 1227 DrvIMS_MemorySetEnaSta 0;
BA_REL_ "GenSigTimeoutTime" BU_SG_REL_ CGW_CCU SG_ 1227 DrvIMS_MemorySetEnaSta 0;
BA_ "NetworkRequest" SG_ 1227 DrvIMS_MemorySetEnaSta 0;
BA_ "NetworkRequestHoldingTime" SG_ 1227 DrvIMS_MemorySetEnaSta 5000;
BA_ "Version" SG_ 1227 DrvIMS_MemorySetEnaSta "17.11.00";
BA_ "GenSigSendType" SG_ 1227 DrvIMS_PlyBckP1Req 4;
BA_ "UserSigValidity" SG_ 1227 DrvIMS_PlyBckP1Req 0;
BA_REL_ "GenSigTimeoutTime" BU_SG_REL_ CGW_CCU SG_ 1227 DrvIMS_PlyBckP1Req 0;
BA_ "NetworkRequest" SG_ 1227 DrvIMS_PlyBckP1Req 0;
BA_ "NetworkRequestHoldingTime" SG_ 1227 DrvIMS_PlyBckP1Req 5000;
BA_ "Version" SG_ 1227 DrvIMS_PlyBckP1Req "17.11.00";
BA_ "GenMsgCycleTime" BO_ 1252 0;
BA_ "Description" SG_ 1252 RKE_Crc1Val "The data area for CRC calculation is based on the data length (DLC) of the message DB.

The CRC shall be calculated over the entire data block (excluding the CRC bytes) including the user data, alive counter and Data ID 

 

- CRC Polynomial (0x1D) , Initial Value : 0x00, XOR value : 0xFF, Data ID Mode : Both, Data ID : Message ID + 0xF800 

- The initial value is for CRC calculation and the message should be sent with the calculated result value. 

The mathematical expression to 8 bit CRC polynomial is given here. G(x) = x8 + x4 + x3 + x2 + 1";
BA_ "GenSigSendType" SG_ 1252 RKE_Crc1Val 4;
BA_ "GenSigStartValue" SG_ 1252 RKE_Crc1Val 255;
BA_ "UserSigValidity" SG_ 1252 RKE_Crc1Val 0;
BA_ "Version" SG_ 1252 RKE_Crc1Val "18.11.08";
BA_ "Description" SG_ 1252 RKE_AlvCnt1Val "For the first transmission request for a data element the counter shall be initialized with 0 and shall be incremented by 1

for every subsequent send request. When the counter reaches the maximum value(0xE), then it shall restart with 0 for the next send request";
BA_ "GenSigSendType" SG_ 1252 RKE_AlvCnt1Val 4;
BA_ "UserSigValidity" SG_ 1252 RKE_AlvCnt1Val 0;
BA_ "Version" SG_ 1252 RKE_AlvCnt1Val "18.11.08";
BA_ "Description" SG_ 1252 RKE_BtnReq "Remote Key Button Request from Folding Key or Smart Key";
BA_ "GenSigSendType" SG_ 1252 RKE_BtnReq 4;
BA_ "UserSigValidity" SG_ 1252 RKE_BtnReq 0;
BA_REL_ "GenSigTimeoutTime" BU_SG_REL_ ATS SG_ 1252 RKE_BtnReq 0;
BA_ "NetworkRequest" SG_ 1252 RKE_BtnReq 0;
BA_ "NetworkRequestHoldingTime" SG_ 1252 RKE_BtnReq 5000;
BA_ "Version" SG_ 1252 RKE_BtnReq "19.05.06";
BA_ "Description" SG_ 1252 RKE_WdwUpDnReq "Remote Key Window Up and Down Request from Folding Key or Smart Key";
BA_ "GenSigSendType" SG_ 1252 RKE_WdwUpDnReq 4;
BA_ "UserSigValidity" SG_ 1252 RKE_WdwUpDnReq 0;
BA_REL_ "GenSigTimeoutTime" BU_SG_REL_ RDC SG_ 1252 RKE_WdwUpDnReq 0;
BA_ "NetworkRequest" SG_ 1252 RKE_WdwUpDnReq 0;
BA_ "NetworkRequestHoldingTime" SG_ 1252 RKE_WdwUpDnReq 5000;
BA_ "Version" SG_ 1252 RKE_WdwUpDnReq "17.12.00";
BA_ "Description" SG_ 1252 RKE_TrnkTlgtBtnReq "This signal for Tailgate or Trunk open CMD

While RKE Tailgate(Trunk) Button push, This Signal Tx On

While Tailgate(Trunk) Button released, This Signal Tx Off";
BA_ "GenSigSendType" SG_ 1252 RKE_TrnkTlgtBtnReq 4;
BA_ "UserSigValidity" SG_ 1252 RKE_TrnkTlgtBtnReq 0;
BA_ "NetworkRequest" SG_ 1252 RKE_TrnkTlgtBtnReq 0;
BA_ "NetworkRequestHoldingTime" SG_ 1252 RKE_TrnkTlgtBtnReq 5000;
BA_ "Version" SG_ 1252 RKE_TrnkTlgtBtnReq "18.07.01";
BA_ "Description" SG_ 1252 RKE_ID "Remote Key Window Up and Down Request from Folding Key or Smart Key



Folding key or smart key ID for recently received RF frame";
BA_ "GenSigSendType" SG_ 1252 RKE_ID 4;
BA_ "UserSigValidity" SG_ 1252 RKE_ID 0;
BA_ "Version" SG_ 1252 RKE_ID "17.12.00";
BA_ "Description" SG_ 1252 RKE_PwrDrAllOpnClsReq "Remote Key Button Signal for PSD and PTG opening or closing together";
BA_ "GenSigSendType" SG_ 1252 RKE_PwrDrAllOpnClsReq 4;
BA_ "UserSigValidity" SG_ 1252 RKE_PwrDrAllOpnClsReq 0;
BA_ "NetworkRequest" SG_ 1252 RKE_PwrDrAllOpnClsReq 0;
BA_ "NetworkRequestHoldingTime" SG_ 1252 RKE_PwrDrAllOpnClsReq 5000;
BA_ "Version" SG_ 1252 RKE_PwrDrAllOpnClsReq "19.04.04";
BA_ "GenMsgCycleTime" BO_ 681 0;
BA_ "GenSigSendType" SG_ 681 RLPSM_ReturnMemReq 4;
BA_ "UserSigValidity" SG_ 681 RLPSM_ReturnMemReq 3;
BA_REL_ "GenSigTimeoutTime" BU_SG_REL_ ATS SG_ 681 RLPSM_ReturnMemReq 0;
BA_ "NetworkRequest" SG_ 681 RLPSM_ReturnMemReq 0;
BA_ "NetworkRequestHoldingTime" SG_ 681 RLPSM_ReturnMemReq 5000;
BA_ "Version" SG_ 681 RLPSM_ReturnMemReq "21.01.02";
BA_ "GenSigSendType" SG_ 681 RLPSM_RearModeWngDis 4;
BA_ "UserSigValidity" SG_ 681 RLPSM_RearModeWngDis 1;
BA_REL_ "GenSigTimeoutTime" BU_SG_REL_ CGW_CCU SG_ 681 RLPSM_RearModeWngDis 0;
BA_ "NetworkRequest" SG_ 681 RLPSM_RearModeWngDis 0;
BA_ "NetworkRequestHoldingTime" SG_ 681 RLPSM_RearModeWngDis 5000;
BA_ "Version" SG_ 681 RLPSM_RearModeWngDis "21.04.00";
BA_ "GenSigSendType" SG_ 681 RLPSM_RestMemReq 4;
BA_ "UserSigValidity" SG_ 681 RLPSM_RestMemReq 3;
BA_REL_ "GenSigTimeoutTime" BU_SG_REL_ ATS SG_ 681 RLPSM_RestMemReq 0;
BA_ "NetworkRequest" SG_ 681 RLPSM_RestMemReq 0;
BA_ "NetworkRequestHoldingTime" SG_ 681 RLPSM_RestMemReq 5000;
BA_ "Version" SG_ 681 RLPSM_RestMemReq "21.01.02";
BA_ "GenMsgSendType" BO_ 138 0;
BA_ "Description" SG_ 138 RLPSS_Local_Crc1Val "The data area for CRC calculation is based on the data length (DLC) of the message DB.

The CRC shall be calculated over the entire data block (excluding the CRC bytes) including the user data, alive counter and Data ID 

 

- CRC Polynomial (0x1D) , Initial Value : 0x00, XOR value : 0xFF, Data ID Mode : Both, Data ID : Message ID + 0xF800 

- The initial value is for CRC calculation and the message should be sent with the calculated result value. 

The mathematical expression to 8 bit CRC polynomial is given here. G(x) = x8 + x4 + x3 + x2 + 1";
BA_ "GenSigSendType" SG_ 138 RLPSS_Local_Crc1Val 4;
BA_ "GenSigStartValue" SG_ 138 RLPSS_Local_Crc1Val 255;
BA_ "UserSigValidity" SG_ 138 RLPSS_Local_Crc1Val 0;
BA_REL_ "GenSigTimeoutTime" BU_SG_REL_ CGW_CCU SG_ 138 RLPSS_Local_Crc1Val 1500;
BA_ "Version" SG_ 138 RLPSS_Local_Crc1Val "19.12.07";
BA_ "Description" SG_ 138 RLPSS_Local_AlvCnt1Val "For the first transmission request for a data element the counter shall be initialized with 0 and shall be incremented by 1

for every subsequent send request. When the counter reaches the maximum value(0xE), then it shall restart with 0 for the next send request";
BA_ "GenSigSendType" SG_ 138 RLPSS_Local_AlvCnt1Val 4;
BA_ "UserSigValidity" SG_ 138 RLPSS_Local_AlvCnt1Val 0;
BA_REL_ "GenSigTimeoutTime" BU_SG_REL_ CGW_CCU SG_ 138 RLPSS_Local_AlvCnt1Val 1500;
BA_ "Version" SG_ 138 RLPSS_Local_AlvCnt1Val "19.12.07";
BA_ "Description" SG_ 138 RLPSS_L_StSldFwdMvBtn "RLPSS_SlideForwardMoveButton";
BA_ "GenSigSendType" SG_ 138 RLPSS_L_StSldFwdMvBtn 4;
BA_ "UserSigValidity" SG_ 138 RLPSS_L_StSldFwdMvBtn 0;
BA_REL_ "GenSigTimeoutTime" BU_SG_REL_ ATS SG_ 138 RLPSS_L_StSldFwdMvBtn 1500;
BA_REL_ "GenSigTimeoutTime" BU_SG_REL_ CGW_CCU SG_ 138 RLPSS_L_StSldFwdMvBtn 1500;
BA_ "NetworkRequest" SG_ 138 RLPSS_L_StSldFwdMvBtn 0;
BA_ "NetworkRequestHoldingTime" SG_ 138 RLPSS_L_StSldFwdMvBtn 5000;
BA_ "Version" SG_ 138 RLPSS_L_StSldFwdMvBtn "19.12.07";
BA_ "Description" SG_ 138 RLPSS_L_StRclFwdMvBtn "RLPSS_ReclinerForwardMoveButton";
BA_ "GenSigSendType" SG_ 138 RLPSS_L_StRclFwdMvBtn 4;
BA_ "UserSigValidity" SG_ 138 RLPSS_L_StRclFwdMvBtn 0;
BA_REL_ "GenSigTimeoutTime" BU_SG_REL_ ATS SG_ 138 RLPSS_L_StRclFwdMvBtn 1500;
BA_REL_ "GenSigTimeoutTime" BU_SG_REL_ CGW_CCU SG_ 138 RLPSS_L_StRclFwdMvBtn 1500;
BA_ "NetworkRequest" SG_ 138 RLPSS_L_StRclFwdMvBtn 0;
BA_ "NetworkRequestHoldingTime" SG_ 138 RLPSS_L_StRclFwdMvBtn 5000;
BA_ "Version" SG_ 138 RLPSS_L_StRclFwdMvBtn "19.12.07";
BA_ "Description" SG_ 138 RLPSS_L_StSldBwdMvBtn "RLPSS_SlideBackwardMoveButton";
BA_ "GenSigSendType" SG_ 138 RLPSS_L_StSldBwdMvBtn 4;
BA_ "UserSigValidity" SG_ 138 RLPSS_L_StSldBwdMvBtn 0;
BA_REL_ "GenSigTimeoutTime" BU_SG_REL_ ATS SG_ 138 RLPSS_L_StSldBwdMvBtn 1500;
BA_REL_ "GenSigTimeoutTime" BU_SG_REL_ CGW_CCU SG_ 138 RLPSS_L_StSldBwdMvBtn 1500;
BA_ "NetworkRequest" SG_ 138 RLPSS_L_StSldBwdMvBtn 0;
BA_ "NetworkRequestHoldingTime" SG_ 138 RLPSS_L_StSldBwdMvBtn 5000;
BA_ "Version" SG_ 138 RLPSS_L_StSldBwdMvBtn "19.12.07";
BA_ "Description" SG_ 138 RLPSS_L_StRclBwdMvBtn "RLPSS_ReclinerBackwardMoveButton";
BA_ "GenSigSendType" SG_ 138 RLPSS_L_StRclBwdMvBtn 4;
BA_ "UserSigValidity" SG_ 138 RLPSS_L_StRclBwdMvBtn 0;
BA_REL_ "GenSigTimeoutTime" BU_SG_REL_ ATS SG_ 138 RLPSS_L_StRclBwdMvBtn 1500;
BA_REL_ "GenSigTimeoutTime" BU_SG_REL_ CGW_CCU SG_ 138 RLPSS_L_StRclBwdMvBtn 1500;
BA_ "NetworkRequest" SG_ 138 RLPSS_L_StRclBwdMvBtn 0;
BA_ "NetworkRequestHoldingTime" SG_ 138 RLPSS_L_StRclBwdMvBtn 5000;
BA_ "Version" SG_ 138 RLPSS_L_StRclBwdMvBtn "19.12.07";
BA_ "Description" SG_ 138 RLPSS_L_StTltUpMvBtn "RLPSS_TiltUpMoveButton";
BA_ "GenSigSendType" SG_ 138 RLPSS_L_StTltUpMvBtn 4;
BA_ "UserSigValidity" SG_ 138 RLPSS_L_StTltUpMvBtn 0;
BA_REL_ "GenSigTimeoutTime" BU_SG_REL_ ATS SG_ 138 RLPSS_L_StTltUpMvBtn 1500;
BA_REL_ "GenSigTimeoutTime" BU_SG_REL_ CGW_CCU SG_ 138 RLPSS_L_StTltUpMvBtn 1500;
BA_ "NetworkRequest" SG_ 138 RLPSS_L_StTltUpMvBtn 0;
BA_ "NetworkRequestHoldingTime" SG_ 138 RLPSS_L_StTltUpMvBtn 5000;
BA_ "Version" SG_ 138 RLPSS_L_StTltUpMvBtn "19.12.07";
BA_ "Description" SG_ 138 RLPSS_L_StTltDnMvBtn "RLPSS_TiltDownMoveButton";
BA_ "GenSigSendType" SG_ 138 RLPSS_L_StTltDnMvBtn 4;
BA_ "UserSigValidity" SG_ 138 RLPSS_L_StTltDnMvBtn 0;
BA_REL_ "GenSigTimeoutTime" BU_SG_REL_ ATS SG_ 138 RLPSS_L_StTltDnMvBtn 1500;
BA_REL_ "GenSigTimeoutTime" BU_SG_REL_ CGW_CCU SG_ 138 RLPSS_L_StTltDnMvBtn 1500;
BA_ "NetworkRequest" SG_ 138 RLPSS_L_StTltDnMvBtn 0;
BA_ "NetworkRequestHoldingTime" SG_ 138 RLPSS_L_StTltDnMvBtn 5000;
BA_ "Version" SG_ 138 RLPSS_L_StTltDnMvBtn "19.12.07";
BA_ "Description" SG_ 138 RLPSS_L_StHRestUpMvBtn "RLPSS_Head Rest UpMoveButton";
BA_ "GenSigSendType" SG_ 138 RLPSS_L_StHRestUpMvBtn 4;
BA_ "UserSigValidity" SG_ 138 RLPSS_L_StHRestUpMvBtn 0;
BA_REL_ "GenSigTimeoutTime" BU_SG_REL_ ATS SG_ 138 RLPSS_L_StHRestUpMvBtn 1500;
BA_REL_ "GenSigTimeoutTime" BU_SG_REL_ CGW_CCU SG_ 138 RLPSS_L_StHRestUpMvBtn 1500;
BA_ "NetworkRequest" SG_ 138 RLPSS_L_StHRestUpMvBtn 0;
BA_ "NetworkRequestHoldingTime" SG_ 138 RLPSS_L_StHRestUpMvBtn 5000;
BA_ "Version" SG_ 138 RLPSS_L_StHRestUpMvBtn "19.12.07";
BA_ "Description" SG_ 138 RLPSS_L_StHRestDnMvBtn "RLPSS_Head Rest DownMoveButton";
BA_ "GenSigSendType" SG_ 138 RLPSS_L_StHRestDnMvBtn 4;
BA_ "UserSigValidity" SG_ 138 RLPSS_L_StHRestDnMvBtn 0;
BA_REL_ "GenSigTimeoutTime" BU_SG_REL_ ATS SG_ 138 RLPSS_L_StHRestDnMvBtn 1500;
BA_REL_ "GenSigTimeoutTime" BU_SG_REL_ CGW_CCU SG_ 138 RLPSS_L_StHRestDnMvBtn 1500;
BA_ "NetworkRequest" SG_ 138 RLPSS_L_StHRestDnMvBtn 0;
BA_ "NetworkRequestHoldingTime" SG_ 138 RLPSS_L_StHRestDnMvBtn 5000;
BA_ "Version" SG_ 138 RLPSS_L_StHRestDnMvBtn "19.12.07";
BA_ "Description" SG_ 138 RLPSS_L_StHRestFwdMvBtn "RLPSS_Head Rest ForwardMoveButton";
BA_ "GenSigSendType" SG_ 138 RLPSS_L_StHRestFwdMvBtn 4;
BA_ "UserSigValidity" SG_ 138 RLPSS_L_StHRestFwdMvBtn 0;
BA_REL_ "GenSigTimeoutTime" BU_SG_REL_ ATS SG_ 138 RLPSS_L_StHRestFwdMvBtn 1500;
BA_REL_ "GenSigTimeoutTime" BU_SG_REL_ CGW_CCU SG_ 138 RLPSS_L_StHRestFwdMvBtn 1500;
BA_ "NetworkRequest" SG_ 138 RLPSS_L_StHRestFwdMvBtn 0;
BA_ "NetworkRequestHoldingTime" SG_ 138 RLPSS_L_StHRestFwdMvBtn 5000;
BA_ "Version" SG_ 138 RLPSS_L_StHRestFwdMvBtn "19.12.07";
BA_ "Description" SG_ 138 RLPSS_L_StHRestBwdMvBtn "RLPSS_Head Rest BackwardMoveButton";
BA_ "GenSigSendType" SG_ 138 RLPSS_L_StHRestBwdMvBtn 4;
BA_ "UserSigValidity" SG_ 138 RLPSS_L_StHRestBwdMvBtn 0;
BA_REL_ "GenSigTimeoutTime" BU_SG_REL_ ATS SG_ 138 RLPSS_L_StHRestBwdMvBtn 1500;
BA_REL_ "GenSigTimeoutTime" BU_SG_REL_ CGW_CCU SG_ 138 RLPSS_L_StHRestBwdMvBtn 1500;
BA_ "NetworkRequest" SG_ 138 RLPSS_L_StHRestBwdMvBtn 0;
BA_ "NetworkRequestHoldingTime" SG_ 138 RLPSS_L_StHRestBwdMvBtn 5000;
BA_ "Version" SG_ 138 RLPSS_L_StHRestBwdMvBtn "19.12.07";
BA_ "Description" SG_ 138 RLPSS_L_StLegRestUpBtn "RLPSS_Leg Rest Up MoveButton";
BA_ "GenSigSendType" SG_ 138 RLPSS_L_StLegRestUpBtn 4;
BA_ "UserSigValidity" SG_ 138 RLPSS_L_StLegRestUpBtn 0;
BA_REL_ "GenSigTimeoutTime" BU_SG_REL_ ATS SG_ 138 RLPSS_L_StLegRestUpBtn 1500;
BA_REL_ "GenSigTimeoutTime" BU_SG_REL_ CGW_CCU SG_ 138 RLPSS_L_StLegRestUpBtn 1500;
BA_ "NetworkRequest" SG_ 138 RLPSS_L_StLegRestUpBtn 0;
BA_ "NetworkRequestHoldingTime" SG_ 138 RLPSS_L_StLegRestUpBtn 5000;
BA_ "Version" SG_ 138 RLPSS_L_StLegRestUpBtn "20.08.07";
BA_ "Description" SG_ 138 RLPSS_L_StLegRestDnBtn "RLPSS_Leg Rest Down MoveButton";
BA_ "GenSigSendType" SG_ 138 RLPSS_L_StLegRestDnBtn 4;
BA_ "UserSigValidity" SG_ 138 RLPSS_L_StLegRestDnBtn 0;
BA_REL_ "GenSigTimeoutTime" BU_SG_REL_ ATS SG_ 138 RLPSS_L_StLegRestDnBtn 1500;
BA_REL_ "GenSigTimeoutTime" BU_SG_REL_ CGW_CCU SG_ 138 RLPSS_L_StLegRestDnBtn 1500;
BA_ "NetworkRequest" SG_ 138 RLPSS_L_StLegRestDnBtn 0;
BA_ "NetworkRequestHoldingTime" SG_ 138 RLPSS_L_StLegRestDnBtn 5000;
BA_ "Version" SG_ 138 RLPSS_L_StLegRestDnBtn "20.08.07";
BA_ "Description" SG_ 138 RLPSS_L_StLegRestExtUpBtn "RLPSS_Leg Rest Forward Move Button";
BA_ "GenSigSendType" SG_ 138 RLPSS_L_StLegRestExtUpBtn 4;
BA_ "UserSigValidity" SG_ 138 RLPSS_L_StLegRestExtUpBtn 0;
BA_REL_ "GenSigTimeoutTime" BU_SG_REL_ ATS SG_ 138 RLPSS_L_StLegRestExtUpBtn 1500;
BA_REL_ "GenSigTimeoutTime" BU_SG_REL_ CGW_CCU SG_ 138 RLPSS_L_StLegRestExtUpBtn 1500;
BA_ "NetworkRequest" SG_ 138 RLPSS_L_StLegRestExtUpBtn 0;
BA_ "NetworkRequestHoldingTime" SG_ 138 RLPSS_L_StLegRestExtUpBtn 5000;
BA_ "Version" SG_ 138 RLPSS_L_StLegRestExtUpBtn "20.08.07";
BA_ "Description" SG_ 138 RLPSS_L_StLegRestExtDnBtn "RLPSS_Leg Rest Backward Move Button";
BA_ "GenSigSendType" SG_ 138 RLPSS_L_StLegRestExtDnBtn 4;
BA_ "UserSigValidity" SG_ 138 RLPSS_L_StLegRestExtDnBtn 0;
BA_REL_ "GenSigTimeoutTime" BU_SG_REL_ ATS SG_ 138 RLPSS_L_StLegRestExtDnBtn 1500;
BA_REL_ "GenSigTimeoutTime" BU_SG_REL_ CGW_CCU SG_ 138 RLPSS_L_StLegRestExtDnBtn 1500;
BA_ "NetworkRequest" SG_ 138 RLPSS_L_StLegRestExtDnBtn 0;
BA_ "NetworkRequestHoldingTime" SG_ 138 RLPSS_L_StLegRestExtDnBtn 5000;
BA_ "Version" SG_ 138 RLPSS_L_StLegRestExtDnBtn "20.08.07";
BA_ "GenMsgSendType" BO_ 143 0;
BA_ "Description" SG_ 143 RLSAU_L_AirSptTimeRValueSet "Air Support Time(Massage Time) USM R Value";
BA_ "GenSigSendType" SG_ 143 RLSAU_L_AirSptTimeRValueSet 4;
BA_ "UserSigValidity" SG_ 143 RLSAU_L_AirSptTimeRValueSet 3;
BA_REL_ "GenSigTimeoutTime" BU_SG_REL_ ATS SG_ 143 RLSAU_L_AirSptTimeRValueSet 1500;
BA_REL_ "GenSigTimeoutTime" BU_SG_REL_ CGW_CCU SG_ 143 RLSAU_L_AirSptTimeRValueSet 1500;
BA_ "NetworkRequest" SG_ 143 RLSAU_L_AirSptTimeRValueSet 0;
BA_ "NetworkRequestHoldingTime" SG_ 143 RLSAU_L_AirSptTimeRValueSet 5000;
BA_ "Version" SG_ 143 RLSAU_L_AirSptTimeRValueSet "19.12.07";
BA_ "Description" SG_ 143 RLSAU_L_RLSmtAirSptRValueSet "Seat Smart Support Function USM R Value";
BA_ "GenSigSendType" SG_ 143 RLSAU_L_RLSmtAirSptRValueSet 4;
BA_ "UserSigValidity" SG_ 143 RLSAU_L_RLSmtAirSptRValueSet 3;
BA_REL_ "GenSigTimeoutTime" BU_SG_REL_ ATS SG_ 143 RLSAU_L_RLSmtAirSptRValueSet 1500;
BA_REL_ "GenSigTimeoutTime" BU_SG_REL_ CGW_CCU SG_ 143 RLSAU_L_RLSmtAirSptRValueSet 1500;
BA_ "NetworkRequest" SG_ 143 RLSAU_L_RLSmtAirSptRValueSet 0;
BA_ "NetworkRequestHoldingTime" SG_ 143 RLSAU_L_RLSmtAirSptRValueSet 5000;
BA_ "Version" SG_ 143 RLSAU_L_RLSmtAirSptRValueSet "19.12.07";
BA_ "Description" SG_ 143 RLSAU_L_LumbarDefSta "Back Lumbar Def State";
BA_ "GenSigSendType" SG_ 143 RLSAU_L_LumbarDefSta 4;
BA_ "UserSigValidity" SG_ 143 RLSAU_L_LumbarDefSta 3;
BA_REL_ "GenSigTimeoutTime" BU_SG_REL_ ATS SG_ 143 RLSAU_L_LumbarDefSta 1500;
BA_REL_ "GenSigTimeoutTime" BU_SG_REL_ CGW_CCU SG_ 143 RLSAU_L_LumbarDefSta 1500;
BA_ "NetworkRequest" SG_ 143 RLSAU_L_LumbarDefSta 0;
BA_ "NetworkRequestHoldingTime" SG_ 143 RLSAU_L_LumbarDefSta 5000;
BA_ "Version" SG_ 143 RLSAU_L_LumbarDefSta "20.08.00";
BA_ "Description" SG_ 143 RLSAU_L_LumbarUpSta "Back Lumbar Up State";
BA_ "GenSigSendType" SG_ 143 RLSAU_L_LumbarUpSta 4;
BA_ "UserSigValidity" SG_ 143 RLSAU_L_LumbarUpSta 3;
BA_REL_ "GenSigTimeoutTime" BU_SG_REL_ ATS SG_ 143 RLSAU_L_LumbarUpSta 1500;
BA_REL_ "GenSigTimeoutTime" BU_SG_REL_ CGW_CCU SG_ 143 RLSAU_L_LumbarUpSta 1500;
BA_ "NetworkRequest" SG_ 143 RLSAU_L_LumbarUpSta 0;
BA_ "NetworkRequestHoldingTime" SG_ 143 RLSAU_L_LumbarUpSta 5000;
BA_ "Version" SG_ 143 RLSAU_L_LumbarUpSta "20.04.02";
BA_ "Description" SG_ 143 RLSAU_L_LumbarMidSta "Back Lumbar Mid State";
BA_ "GenSigSendType" SG_ 143 RLSAU_L_LumbarMidSta 4;
BA_ "UserSigValidity" SG_ 143 RLSAU_L_LumbarMidSta 3;
BA_REL_ "GenSigTimeoutTime" BU_SG_REL_ ATS SG_ 143 RLSAU_L_LumbarMidSta 1500;
BA_REL_ "GenSigTimeoutTime" BU_SG_REL_ CGW_CCU SG_ 143 RLSAU_L_LumbarMidSta 1500;
BA_ "NetworkRequest" SG_ 143 RLSAU_L_LumbarMidSta 0;
BA_ "NetworkRequestHoldingTime" SG_ 143 RLSAU_L_LumbarMidSta 5000;
BA_ "Version" SG_ 143 RLSAU_L_LumbarMidSta "20.04.02";
BA_ "Description" SG_ 143 RLSAU_L_LumbarLowSta "Back Lumbar Low State";
BA_ "GenSigSendType" SG_ 143 RLSAU_L_LumbarLowSta 4;
BA_ "UserSigValidity" SG_ 143 RLSAU_L_LumbarLowSta 3;
BA_REL_ "GenSigTimeoutTime" BU_SG_REL_ ATS SG_ 143 RLSAU_L_LumbarLowSta 1500;
BA_REL_ "GenSigTimeoutTime" BU_SG_REL_ CGW_CCU SG_ 143 RLSAU_L_LumbarLowSta 1500;
BA_ "NetworkRequest" SG_ 143 RLSAU_L_LumbarLowSta 0;
BA_ "NetworkRequestHoldingTime" SG_ 143 RLSAU_L_LumbarLowSta 5000;
BA_ "Version" SG_ 143 RLSAU_L_LumbarLowSta "20.04.02";
BA_ "Description" SG_ 143 RLSAU_L_BolsterInfSta "Back Bolster Inflate State";
BA_ "GenSigSendType" SG_ 143 RLSAU_L_BolsterInfSta 4;
BA_ "UserSigValidity" SG_ 143 RLSAU_L_BolsterInfSta 3;
BA_REL_ "GenSigTimeoutTime" BU_SG_REL_ ATS SG_ 143 RLSAU_L_BolsterInfSta 1500;
BA_REL_ "GenSigTimeoutTime" BU_SG_REL_ CGW_CCU SG_ 143 RLSAU_L_BolsterInfSta 1500;
BA_ "NetworkRequest" SG_ 143 RLSAU_L_BolsterInfSta 0;
BA_ "NetworkRequestHoldingTime" SG_ 143 RLSAU_L_BolsterInfSta 5000;
BA_ "Version" SG_ 143 RLSAU_L_BolsterInfSta "20.04.02";
BA_ "Description" SG_ 143 RLSAU_L_BolsterDefSta "Back Bolster Deflate State";
BA_ "GenSigSendType" SG_ 143 RLSAU_L_BolsterDefSta 4;
BA_ "UserSigValidity" SG_ 143 RLSAU_L_BolsterDefSta 3;
BA_REL_ "GenSigTimeoutTime" BU_SG_REL_ ATS SG_ 143 RLSAU_L_BolsterDefSta 1500;
BA_REL_ "GenSigTimeoutTime" BU_SG_REL_ CGW_CCU SG_ 143 RLSAU_L_BolsterDefSta 1500;
BA_ "NetworkRequest" SG_ 143 RLSAU_L_BolsterDefSta 0;
BA_ "NetworkRequestHoldingTime" SG_ 143 RLSAU_L_BolsterDefSta 5000;
BA_ "Version" SG_ 143 RLSAU_L_BolsterDefSta "20.04.02";
BA_ "Description" SG_ 143 RLSAU_L_BackSoftRValueSet "Back Soft USM R Value";
BA_ "GenSigSendType" SG_ 143 RLSAU_L_BackSoftRValueSet 4;
BA_ "UserSigValidity" SG_ 143 RLSAU_L_BackSoftRValueSet 3;
BA_REL_ "GenSigTimeoutTime" BU_SG_REL_ ATS SG_ 143 RLSAU_L_BackSoftRValueSet 1500;
BA_REL_ "GenSigTimeoutTime" BU_SG_REL_ CGW_CCU SG_ 143 RLSAU_L_BackSoftRValueSet 1500;
BA_ "NetworkRequest" SG_ 143 RLSAU_L_BackSoftRValueSet 0;
BA_ "NetworkRequestHoldingTime" SG_ 143 RLSAU_L_BackSoftRValueSet 5000;
BA_ "Version" SG_ 143 RLSAU_L_BackSoftRValueSet "20.04.02";
BA_ "Description" SG_ 143 RLSAU_L_ActiveSw "Active Switch(Massage Strenth Control) Staus";
BA_ "GenSigSendType" SG_ 143 RLSAU_L_ActiveSw 4;
BA_ "UserSigValidity" SG_ 143 RLSAU_L_ActiveSw 3;
BA_REL_ "GenSigTimeoutTime" BU_SG_REL_ ATS SG_ 143 RLSAU_L_ActiveSw 1500;
BA_ "NetworkRequest" SG_ 143 RLSAU_L_ActiveSw 0;
BA_ "NetworkRequestHoldingTime" SG_ 143 RLSAU_L_ActiveSw 5000;
BA_ "Version" SG_ 143 RLSAU_L_ActiveSw "21.06.11";
BA_ "Description" SG_ 143 RLSAU_L_AirSptModeRValueSet "Air Support Mode(Massage Mode) USM R Value";
BA_ "GenSigSendType" SG_ 143 RLSAU_L_AirSptModeRValueSet 4;
BA_ "UserSigValidity" SG_ 143 RLSAU_L_AirSptModeRValueSet 3;
BA_REL_ "GenSigTimeoutTime" BU_SG_REL_ ATS SG_ 143 RLSAU_L_AirSptModeRValueSet 1500;
BA_REL_ "GenSigTimeoutTime" BU_SG_REL_ CGW_CCU SG_ 143 RLSAU_L_AirSptModeRValueSet 1500;
BA_ "NetworkRequest" SG_ 143 RLSAU_L_AirSptModeRValueSet 0;
BA_ "NetworkRequestHoldingTime" SG_ 143 RLSAU_L_AirSptModeRValueSet 5000;
BA_ "Version" SG_ 143 RLSAU_L_AirSptModeRValueSet "19.12.07";
BA_ "Description" SG_ 143 RLSAU_L_MoodTrpyRValueSet "Rear Left Seat Mood Therapy R Value";
BA_ "GenSigSendType" SG_ 143 RLSAU_L_MoodTrpyRValueSet 4;
BA_ "UserSigValidity" SG_ 143 RLSAU_L_MoodTrpyRValueSet 3;
BA_REL_ "GenSigTimeoutTime" BU_SG_REL_ CGW_CCU SG_ 143 RLSAU_L_MoodTrpyRValueSet 1500;
BA_ "NetworkRequest" SG_ 143 RLSAU_L_MoodTrpyRValueSet 0;
BA_ "NetworkRequestHoldingTime" SG_ 143 RLSAU_L_MoodTrpyRValueSet 5000;
BA_ "Version" SG_ 143 RLSAU_L_MoodTrpyRValueSet "20.07.03";
BA_ "Description" SG_ 143 RLSAU_L_MoodTrpyCareSta "Rear Left Seat Mood Therapy Care Mode R Value";
BA_ "GenSigSendType" SG_ 143 RLSAU_L_MoodTrpyCareSta 4;
BA_ "UserSigValidity" SG_ 143 RLSAU_L_MoodTrpyCareSta 3;
BA_REL_ "GenSigTimeoutTime" BU_SG_REL_ CGW_CCU SG_ 143 RLSAU_L_MoodTrpyCareSta 1500;
BA_ "NetworkRequest" SG_ 143 RLSAU_L_MoodTrpyCareSta 0;
BA_ "NetworkRequestHoldingTime" SG_ 143 RLSAU_L_MoodTrpyCareSta 5000;
BA_ "Version" SG_ 143 RLSAU_L_MoodTrpyCareSta "20.07.12";
BA_ "Description" SG_ 143 RLSAU_L_MoodTrpyComfSta "Rear Left Seat Mood Therapy Comfort Mode R Value";
BA_ "GenSigSendType" SG_ 143 RLSAU_L_MoodTrpyComfSta 4;
BA_ "UserSigValidity" SG_ 143 RLSAU_L_MoodTrpyComfSta 3;
BA_REL_ "GenSigTimeoutTime" BU_SG_REL_ CGW_CCU SG_ 143 RLSAU_L_MoodTrpyComfSta 1500;
BA_ "NetworkRequest" SG_ 143 RLSAU_L_MoodTrpyComfSta 0;
BA_ "NetworkRequestHoldingTime" SG_ 143 RLSAU_L_MoodTrpyComfSta 5000;
BA_ "Version" SG_ 143 RLSAU_L_MoodTrpyComfSta "20.07.12";
BA_ "Description" SG_ 143 RLSAU_L_AirSptStrRValueSet "Air Support Strenth(Massage Strenth) USM R Value";
BA_ "GenSigSendType" SG_ 143 RLSAU_L_AirSptStrRValueSet 4;
BA_ "UserSigValidity" SG_ 143 RLSAU_L_AirSptStrRValueSet 3;
BA_REL_ "GenSigTimeoutTime" BU_SG_REL_ ATS SG_ 143 RLSAU_L_AirSptStrRValueSet 1500;
BA_REL_ "GenSigTimeoutTime" BU_SG_REL_ CGW_CCU SG_ 143 RLSAU_L_AirSptStrRValueSet 1500;
BA_ "NetworkRequest" SG_ 143 RLSAU_L_AirSptStrRValueSet 0;
BA_ "NetworkRequestHoldingTime" SG_ 143 RLSAU_L_AirSptStrRValueSet 5000;
BA_ "Version" SG_ 143 RLSAU_L_AirSptStrRValueSet "20.06.05";
BA_ "GenMsgSendType" BO_ 159 0;
BA_ "Description" SG_ 159 RRSAU_L_AirSptTimeRValueSet "Air Support Time(Massage Time) USM R Value";
BA_ "GenSigSendType" SG_ 159 RRSAU_L_AirSptTimeRValueSet 4;
BA_ "UserSigValidity" SG_ 159 RRSAU_L_AirSptTimeRValueSet 3;
BA_REL_ "GenSigTimeoutTime" BU_SG_REL_ ATS SG_ 159 RRSAU_L_AirSptTimeRValueSet 1500;
BA_REL_ "GenSigTimeoutTime" BU_SG_REL_ CGW_CCU SG_ 159 RRSAU_L_AirSptTimeRValueSet 1500;
BA_ "NetworkRequest" SG_ 159 RRSAU_L_AirSptTimeRValueSet 0;
BA_ "NetworkRequestHoldingTime" SG_ 159 RRSAU_L_AirSptTimeRValueSet 5000;
BA_ "Version" SG_ 159 RRSAU_L_AirSptTimeRValueSet "19.12.07";
BA_ "Description" SG_ 159 RRSAU_L_RRSmtAirSptRValueSet "Seat Smart Air Support Function USM R Value";
BA_ "GenSigSendType" SG_ 159 RRSAU_L_RRSmtAirSptRValueSet 4;
BA_ "UserSigValidity" SG_ 159 RRSAU_L_RRSmtAirSptRValueSet 3;
BA_REL_ "GenSigTimeoutTime" BU_SG_REL_ ATS SG_ 159 RRSAU_L_RRSmtAirSptRValueSet 1500;
BA_REL_ "GenSigTimeoutTime" BU_SG_REL_ CGW_CCU SG_ 159 RRSAU_L_RRSmtAirSptRValueSet 1500;
BA_ "NetworkRequest" SG_ 159 RRSAU_L_RRSmtAirSptRValueSet 0;
BA_ "NetworkRequestHoldingTime" SG_ 159 RRSAU_L_RRSmtAirSptRValueSet 5000;
BA_ "Version" SG_ 159 RRSAU_L_RRSmtAirSptRValueSet "19.12.07";
BA_ "Description" SG_ 159 RRSAU_L_LumbarDefSta "Back Lumbar Deflate State";
BA_ "GenSigSendType" SG_ 159 RRSAU_L_LumbarDefSta 4;
BA_ "UserSigValidity" SG_ 159 RRSAU_L_LumbarDefSta 3;
BA_REL_ "GenSigTimeoutTime" BU_SG_REL_ ATS SG_ 159 RRSAU_L_LumbarDefSta 1500;
BA_REL_ "GenSigTimeoutTime" BU_SG_REL_ CGW_CCU SG_ 159 RRSAU_L_LumbarDefSta 1500;
BA_ "NetworkRequest" SG_ 159 RRSAU_L_LumbarDefSta 0;
BA_ "NetworkRequestHoldingTime" SG_ 159 RRSAU_L_LumbarDefSta 5000;
BA_ "Version" SG_ 159 RRSAU_L_LumbarDefSta "20.08.00";
BA_ "Description" SG_ 159 RRSAU_L_LumbarUpSta "Back Lumbar Up State";
BA_ "GenSigSendType" SG_ 159 RRSAU_L_LumbarUpSta 4;
BA_ "UserSigValidity" SG_ 159 RRSAU_L_LumbarUpSta 3;
BA_REL_ "GenSigTimeoutTime" BU_SG_REL_ ATS SG_ 159 RRSAU_L_LumbarUpSta 1500;
BA_REL_ "GenSigTimeoutTime" BU_SG_REL_ CGW_CCU SG_ 159 RRSAU_L_LumbarUpSta 1500;
BA_ "NetworkRequest" SG_ 159 RRSAU_L_LumbarUpSta 0;
BA_ "NetworkRequestHoldingTime" SG_ 159 RRSAU_L_LumbarUpSta 5000;
BA_ "Version" SG_ 159 RRSAU_L_LumbarUpSta "20.04.02";
BA_ "Description" SG_ 159 RRSAU_L_LumbarMidSta "Back Lumbar Mid State";
BA_ "GenSigSendType" SG_ 159 RRSAU_L_LumbarMidSta 4;
BA_ "UserSigValidity" SG_ 159 RRSAU_L_LumbarMidSta 3;
BA_REL_ "GenSigTimeoutTime" BU_SG_REL_ ATS SG_ 159 RRSAU_L_LumbarMidSta 1500;
BA_REL_ "GenSigTimeoutTime" BU_SG_REL_ CGW_CCU SG_ 159 RRSAU_L_LumbarMidSta 1500;
BA_ "NetworkRequest" SG_ 159 RRSAU_L_LumbarMidSta 0;
BA_ "NetworkRequestHoldingTime" SG_ 159 RRSAU_L_LumbarMidSta 5000;
BA_ "Version" SG_ 159 RRSAU_L_LumbarMidSta "20.04.02";
BA_ "Description" SG_ 159 RRSAU_L_LumbarLowSta "Back Lumbar Low State";
BA_ "GenSigSendType" SG_ 159 RRSAU_L_LumbarLowSta 4;
BA_ "UserSigValidity" SG_ 159 RRSAU_L_LumbarLowSta 3;
BA_REL_ "GenSigTimeoutTime" BU_SG_REL_ ATS SG_ 159 RRSAU_L_LumbarLowSta 1500;
BA_REL_ "GenSigTimeoutTime" BU_SG_REL_ CGW_CCU SG_ 159 RRSAU_L_LumbarLowSta 1500;
BA_ "NetworkRequest" SG_ 159 RRSAU_L_LumbarLowSta 0;
BA_ "NetworkRequestHoldingTime" SG_ 159 RRSAU_L_LumbarLowSta 5000;
BA_ "Version" SG_ 159 RRSAU_L_LumbarLowSta "20.04.02";
BA_ "Description" SG_ 159 RRSAU_L_BolsterInfSta "Back Bolster Inflate State";
BA_ "GenSigSendType" SG_ 159 RRSAU_L_BolsterInfSta 4;
BA_ "UserSigValidity" SG_ 159 RRSAU_L_BolsterInfSta 3;
BA_REL_ "GenSigTimeoutTime" BU_SG_REL_ ATS SG_ 159 RRSAU_L_BolsterInfSta 1500;
BA_REL_ "GenSigTimeoutTime" BU_SG_REL_ CGW_CCU SG_ 159 RRSAU_L_BolsterInfSta 1500;
BA_ "NetworkRequest" SG_ 159 RRSAU_L_BolsterInfSta 0;
BA_ "NetworkRequestHoldingTime" SG_ 159 RRSAU_L_BolsterInfSta 5000;
BA_ "Version" SG_ 159 RRSAU_L_BolsterInfSta "20.04.02";
BA_ "Description" SG_ 159 RRSAU_L_BolsterDefSta "Back Bolster Deflate State";
BA_ "GenSigSendType" SG_ 159 RRSAU_L_BolsterDefSta 4;
BA_ "UserSigValidity" SG_ 159 RRSAU_L_BolsterDefSta 3;
BA_REL_ "GenSigTimeoutTime" BU_SG_REL_ ATS SG_ 159 RRSAU_L_BolsterDefSta 1500;
BA_REL_ "GenSigTimeoutTime" BU_SG_REL_ CGW_CCU SG_ 159 RRSAU_L_BolsterDefSta 1500;
BA_ "NetworkRequest" SG_ 159 RRSAU_L_BolsterDefSta 0;
BA_ "NetworkRequestHoldingTime" SG_ 159 RRSAU_L_BolsterDefSta 5000;
BA_ "Version" SG_ 159 RRSAU_L_BolsterDefSta "20.04.02";
BA_ "Description" SG_ 159 RRSAU_L_BackSoftRValueSet "Back Soft USM R Value";
BA_ "GenSigSendType" SG_ 159 RRSAU_L_BackSoftRValueSet 4;
BA_ "UserSigValidity" SG_ 159 RRSAU_L_BackSoftRValueSet 3;
BA_REL_ "GenSigTimeoutTime" BU_SG_REL_ ATS SG_ 159 RRSAU_L_BackSoftRValueSet 1500;
BA_REL_ "GenSigTimeoutTime" BU_SG_REL_ CGW_CCU SG_ 159 RRSAU_L_BackSoftRValueSet 1500;
BA_ "NetworkRequest" SG_ 159 RRSAU_L_BackSoftRValueSet 0;
BA_ "NetworkRequestHoldingTime" SG_ 159 RRSAU_L_BackSoftRValueSet 5000;
BA_ "Version" SG_ 159 RRSAU_L_BackSoftRValueSet "20.04.02";
BA_ "Description" SG_ 159 RRSAU_L_ActiveSw "Active Switch(Massage Strenth Control) Staus";
BA_ "GenSigSendType" SG_ 159 RRSAU_L_ActiveSw 4;
BA_ "UserSigValidity" SG_ 159 RRSAU_L_ActiveSw 3;
BA_REL_ "GenSigTimeoutTime" BU_SG_REL_ ATS SG_ 159 RRSAU_L_ActiveSw 1500;
BA_ "NetworkRequest" SG_ 159 RRSAU_L_ActiveSw 0;
BA_ "NetworkRequestHoldingTime" SG_ 159 RRSAU_L_ActiveSw 5000;
BA_ "Version" SG_ 159 RRSAU_L_ActiveSw "21.01.06";
BA_ "Description" SG_ 159 RRSAU_L_AirSptModeRValueSet "Air Support Mode(Massage Mode) USM R Value";
BA_ "GenSigSendType" SG_ 159 RRSAU_L_AirSptModeRValueSet 4;
BA_ "UserSigValidity" SG_ 159 RRSAU_L_AirSptModeRValueSet 3;
BA_REL_ "GenSigTimeoutTime" BU_SG_REL_ ATS SG_ 159 RRSAU_L_AirSptModeRValueSet 1500;
BA_REL_ "GenSigTimeoutTime" BU_SG_REL_ CGW_CCU SG_ 159 RRSAU_L_AirSptModeRValueSet 1500;
BA_ "NetworkRequest" SG_ 159 RRSAU_L_AirSptModeRValueSet 0;
BA_ "NetworkRequestHoldingTime" SG_ 159 RRSAU_L_AirSptModeRValueSet 5000;
BA_ "Version" SG_ 159 RRSAU_L_AirSptModeRValueSet "19.12.07";
BA_ "Description" SG_ 159 RRSAU_L_MoodTrpyRValueSet "Rear Right Seat Mood Therapy R Value";
BA_ "GenSigSendType" SG_ 159 RRSAU_L_MoodTrpyRValueSet 4;
BA_ "UserSigValidity" SG_ 159 RRSAU_L_MoodTrpyRValueSet 3;
BA_REL_ "GenSigTimeoutTime" BU_SG_REL_ CGW_CCU SG_ 159 RRSAU_L_MoodTrpyRValueSet 1500;
BA_ "NetworkRequest" SG_ 159 RRSAU_L_MoodTrpyRValueSet 0;
BA_ "NetworkRequestHoldingTime" SG_ 159 RRSAU_L_MoodTrpyRValueSet 5000;
BA_ "Version" SG_ 159 RRSAU_L_MoodTrpyRValueSet "20.07.03";
BA_ "Description" SG_ 159 RRSAU_L_MoodTrpyCareSta "Rear Right Seat Mood Therapy Care Mode R Value";
BA_ "GenSigSendType" SG_ 159 RRSAU_L_MoodTrpyCareSta 4;
BA_ "UserSigValidity" SG_ 159 RRSAU_L_MoodTrpyCareSta 3;
BA_REL_ "GenSigTimeoutTime" BU_SG_REL_ CGW_CCU SG_ 159 RRSAU_L_MoodTrpyCareSta 1500;
BA_ "NetworkRequest" SG_ 159 RRSAU_L_MoodTrpyCareSta 0;
BA_ "NetworkRequestHoldingTime" SG_ 159 RRSAU_L_MoodTrpyCareSta 5000;
BA_ "Version" SG_ 159 RRSAU_L_MoodTrpyCareSta "20.07.12";
BA_ "Description" SG_ 159 RRSAU_L_MoodTrpyComfSta "Rear Right Seat Mood Therapy Comfort Mode R Value";
BA_ "GenSigSendType" SG_ 159 RRSAU_L_MoodTrpyComfSta 4;
BA_ "UserSigValidity" SG_ 159 RRSAU_L_MoodTrpyComfSta 3;
BA_REL_ "GenSigTimeoutTime" BU_SG_REL_ CGW_CCU SG_ 159 RRSAU_L_MoodTrpyComfSta 1500;
BA_ "NetworkRequest" SG_ 159 RRSAU_L_MoodTrpyComfSta 0;
BA_ "NetworkRequestHoldingTime" SG_ 159 RRSAU_L_MoodTrpyComfSta 5000;
BA_ "Version" SG_ 159 RRSAU_L_MoodTrpyComfSta "20.07.12";
BA_ "Description" SG_ 159 RRSAU_L_AirSptStrRValueSet "Air Support Strenth(Massage Strenth) USM R Value";
BA_ "GenSigSendType" SG_ 159 RRSAU_L_AirSptStrRValueSet 4;
BA_ "UserSigValidity" SG_ 159 RRSAU_L_AirSptStrRValueSet 3;
BA_REL_ "GenSigTimeoutTime" BU_SG_REL_ ATS SG_ 159 RRSAU_L_AirSptStrRValueSet 1500;
BA_REL_ "GenSigTimeoutTime" BU_SG_REL_ CGW_CCU SG_ 159 RRSAU_L_AirSptStrRValueSet 1500;
BA_ "NetworkRequest" SG_ 159 RRSAU_L_AirSptStrRValueSet 0;
BA_ "NetworkRequestHoldingTime" SG_ 159 RRSAU_L_AirSptStrRValueSet 5000;
BA_ "Version" SG_ 159 RRSAU_L_AirSptStrRValueSet "20.06.05";
BA_ "GenMsgCycleTime" BO_ 1253 0;
BA_ "Description" SG_ 1253 SMK_Crc1Val "The data area for CRC calculation is based on the data length (DLC) of the message DB.

The CRC shall be calculated over the entire data block (excluding the CRC bytes) including the user data, alive counter and Data ID 

 

- CRC Polynomial (0x1D) , Initial Value : 0x00, XOR value : 0xFF, Data ID Mode : Both, Data ID : Message ID + 0xF800 

- The initial value is for CRC calculation and the message should be sent with the calculated result value. 

The mathematical expression to 8 bit CRC polynomial is given here. G(x) = x8 + x4 + x3 + x2 + 1";
BA_ "GenSigSendType" SG_ 1253 SMK_Crc1Val 4;
BA_ "GenSigStartValue" SG_ 1253 SMK_Crc1Val 255;
BA_ "UserSigValidity" SG_ 1253 SMK_Crc1Val 0;
BA_ "Version" SG_ 1253 SMK_Crc1Val "18.11.08";
BA_ "Description" SG_ 1253 SMK_AlvCnt1Val "For the first transmission request for a data element the counter shall be initialized with 0 and shall be incremented by 1

for every subsequent send request. When the counter reaches the maximum value(0xE), then it shall restart with 0 for the next send request";
BA_ "GenSigSendType" SG_ 1253 SMK_AlvCnt1Val 4;
BA_ "UserSigValidity" SG_ 1253 SMK_AlvCnt1Val 0;
BA_ "Version" SG_ 1253 SMK_AlvCnt1Val "18.11.08";
BA_ "GenSigSendType" SG_ 1253 DoorLock_PsvDrLkReq 4;
BA_ "UserSigValidity" SG_ 1253 DoorLock_PsvDrLkReq 0;
BA_ "Version" SG_ 1253 DoorLock_PsvDrLkReq "17.12.00";
BA_ "GenSigSendType" SG_ 1253 DoorLock_PsvDrUnLkReq 4;
BA_ "UserSigValidity" SG_ 1253 DoorLock_PsvDrUnLkReq 0;
BA_ "Version" SG_ 1253 DoorLock_PsvDrUnLkReq "17.12.00";
BA_ "Description" SG_ 1253 DoorLock_DrvDrPsvAcsReq "-(Old)C_P_FL";
BA_ "GenSigSendType" SG_ 1253 DoorLock_DrvDrPsvAcsReq 4;
BA_ "UserSigValidity" SG_ 1253 DoorLock_DrvDrPsvAcsReq 0;
BA_ "Version" SG_ 1253 DoorLock_DrvDrPsvAcsReq "17.12.00";
BA_ "Description" SG_ 1253 DoorLock_AsstDrPsvAcsReq "-(Old)C_P_FR";
BA_ "GenSigSendType" SG_ 1253 DoorLock_AsstDrPsvAcsReq 4;
BA_ "UserSigValidity" SG_ 1253 DoorLock_AsstDrPsvAcsReq 0;
BA_ "Version" SG_ 1253 DoorLock_AsstDrPsvAcsReq "17.12.00";
BA_ "Description" SG_ 1253 DoorLock_TrnkTlgtPsvAcsReq "-(Old)C_PassiveTrunk_TG";
BA_ "GenSigSendType" SG_ 1253 DoorLock_TrnkTlgtPsvAcsReq 4;
BA_ "UserSigValidity" SG_ 1253 DoorLock_TrnkTlgtPsvAcsReq 0;
BA_ "Version" SG_ 1253 DoorLock_TrnkTlgtPsvAcsReq "17.12.00";
BA_ "Description" SG_ 1253 DoorLock_RrLftDrPsvAcsReq "-(Old)C_P_RL";
BA_ "GenSigSendType" SG_ 1253 DoorLock_RrLftDrPsvAcsReq 4;
BA_ "UserSigValidity" SG_ 1253 DoorLock_RrLftDrPsvAcsReq 0;
BA_ "Version" SG_ 1253 DoorLock_RrLftDrPsvAcsReq "17.12.00";
BA_ "Description" SG_ 1253 DoorLock_RrRtDrPsvAcsReq "-(Old)C_P_RR";
BA_ "GenSigSendType" SG_ 1253 DoorLock_RrRtDrPsvAcsReq 4;
BA_ "UserSigValidity" SG_ 1253 DoorLock_RrRtDrPsvAcsReq 0;
BA_ "Version" SG_ 1253 DoorLock_RrRtDrPsvAcsReq "17.12.00";
BA_ "Description" SG_ 1253 Auth_Req "Request IAU(NFC / Fingerprint) authentication

##2G##SMK-SMKmsg03-C_SMK_AuthReq";
BA_ "GenSigSendType" SG_ 1253 Auth_Req 4;
BA_ "UserSigValidity" SG_ 1253 Auth_Req 0;
BA_ "NetworkRequest" SG_ 1253 Auth_Req 0;
BA_ "NetworkRequestHoldingTime" SG_ 1253 Auth_Req 5000;
BA_ "Version" SG_ 1253 Auth_Req "19.01.09";
BA_ "Description" SG_ 1253 RSPA_DigitalKeyAuth "Authenticaion by Digital key in RSPA mode";
BA_ "GenSigSendType" SG_ 1253 RSPA_DigitalKeyAuth 4;
BA_ "UserSigValidity" SG_ 1253 RSPA_DigitalKeyAuth 0;
BA_ "Version" SG_ 1253 RSPA_DigitalKeyAuth "19.07.02";
BA_ "Description" SG_ 1253 Auth_Method "This signal is for a send Authentication result and authentication method.

- Fob, TP, Fingerprint, NFC(Digital Key, Card Key), BLE, Face Recognition, Digital key Passive";
BA_ "GenSigSendType" SG_ 1253 Auth_Method 4;
BA_ "UserSigValidity" SG_ 1253 Auth_Method 0;
BA_REL_ "GenSigTimeoutTime" BU_SG_REL_ FPM SG_ 1253 Auth_Method 0;
BA_ "NetworkRequest" SG_ 1253 Auth_Method 0;
BA_ "NetworkRequestHoldingTime" SG_ 1253 Auth_Method 5000;
BA_ "Version" SG_ 1253 Auth_Method "20.03.07";
BA_ "Description" SG_ 1253 RSPA_CanTmotFlagSta "This Signal repesents Timeout State of CAN signals.(From RSPA Unit)

When RSPA Related signal have can timeout, this signal set value 0x1(RSPA Timeout)



This signal would use to determin why vehicle's engine is stoped.";
BA_ "GenSigSendType" SG_ 1253 RSPA_CanTmotFlagSta 4;
BA_ "UserSigValidity" SG_ 1253 RSPA_CanTmotFlagSta 0;
BA_ "Version" SG_ 1253 RSPA_CanTmotFlagSta "17.12.00";
BA_ "Description" SG_ 1253 Auth_ISKLearnFdbck "This signal is Learning Feedback";
BA_ "GenSigSendType" SG_ 1253 Auth_ISKLearnFdbck 4;
BA_ "UserSigValidity" SG_ 1253 Auth_ISKLearnFdbck 0;
BA_ "NetworkRequest" SG_ 1253 Auth_ISKLearnFdbck 0;
BA_ "NetworkRequestHoldingTime" SG_ 1253 Auth_ISKLearnFdbck 5000;
BA_ "Version" SG_ 1253 Auth_ISKLearnFdbck "19.01.02";
BA_ "GenSigSendType" SG_ 1253 Mirror_SmrtWlcmMirrReq 4;
BA_ "UserSigValidity" SG_ 1253 Mirror_SmrtWlcmMirrReq 0;
BA_ "NetworkRequest" SG_ 1253 Mirror_SmrtWlcmMirrReq 0;
BA_ "NetworkRequestHoldingTime" SG_ 1253 Mirror_SmrtWlcmMirrReq 5000;
BA_ "Version" SG_ 1253 Mirror_SmrtWlcmMirrReq "17.12.00";
BA_ "Description" SG_ 1253 SecureCom_Req "This signal for starting secure communication.

##2G##SMK-SMKmsg03-C_SMK_SecureCommReq";
BA_ "GenSigSendType" SG_ 1253 SecureCom_Req 4;
BA_ "UserSigValidity" SG_ 1253 SecureCom_Req 0;
BA_ "NetworkRequest" SG_ 1253 SecureCom_Req 0;
BA_ "NetworkRequestHoldingTime" SG_ 1253 SecureCom_Req 5000;
BA_ "Version" SG_ 1253 SecureCom_Req "19.01.09";
BA_ "Description" SG_ 1253 Auth_Event "This signal is for a send Authentication event";
BA_ "GenSigSendType" SG_ 1253 Auth_Event 4;
BA_ "UserSigValidity" SG_ 1253 Auth_Event 0;
BA_ "NetworkRequest" SG_ 1253 Auth_Event 0;
BA_ "NetworkRequestHoldingTime" SG_ 1253 Auth_Event 5000;
BA_ "Version" SG_ 1253 Auth_Event "20.03.07";
VAL_ 1554 AMP_UpdateIGNIhn 0 "off(default)" 1 "Cranking inhibit" 2 "IGN, Cranking inhibit" 3 "Reserved" 4 "Reserved" 5 "Reserved" 6 "Reserved" 7 "error inicator" ;
VAL_ 1554 AMP_NaviVoice_PriorityState 0 "Navi Voice Priority Off" 1 "Navi Voice Priority ON" 2 "Unused" 3 "Invalid" ;
VAL_ 1554 AMP_MajorVer 0 "0x0x00~0xFE:Valid" 254 "0x0x00~0xFE:Valid" 255 "Invalid" ;
VAL_ 1554 AMP_MinorVer 0 "0x0x00~0xFE:Valid" 254 "0x0x00~0xFE:Valid" 255 "Invalid" ;
VAL_ 1554 AMP_TuningMajorVer 0 "0x0x00~0xFE:Valid" 254 "0x0x00~0xFE:Valid" 255 "Invalid" ;
VAL_ 1554 AMP_TuningMinorVer 0 "0x0x00~0xFE:Valid" 254 "0x0x00~0xFE:Valid" 255 "Invalid" ;
VAL_ 694 ASAU_NotFootMsgOperStaWarn 0 "OFF" 1 "ON" 2 "Reserved" 3 "Reserved" ;
VAL_ 678 APSM_ReadingMemReq 0 "None" 1 "ReadingMem" 2 "Reset" 3 "Error Indicator" ;
VAL_ 678 APSM_IMSWngDis 0 "Default" 1 "Inhibit Ast IMS" 2 "Reserved" 3 "Invaild" ;
VAL_ 678 APSM_RestMemReq 0 "None" 1 "RestMem" 2 "Reset" 3 "Error Indicator" ;
VAL_ 678 APSM_ReturnMemReq 0 "None" 1 "ReturnMem" 2 "Reset" 3 "Error Indicator" ;
VAL_ 678 APSM_AvWtcMemReq 0 "None" 1 "AvWtcMem" 2 "Reset" 3 "Error Indicator" ;
VAL_ 140 ATS_DATC_FrPsModeSet 0 "Reserved" 1 "Vent" 2 "BL" 3 "Floor" 4 "Reserved" 5 "Reserved" 6 "Reserved" 7 "Reserved" 8 "Reserved" 9 "Reserved" 10 "Reserved" 11 "Reserved" 12 "Reserved" 13 "Reserved" 14 "Reserved" 15 "Invalid" ;
VAL_ 140 ATS_DATC_FrPsAutoSet 0 "reserved" 1 "AUTO ON" 2 "reserved" 3 "Invalid" ;
VAL_ 140 ATS_DATC_FrPsBlowerSet 0 "DATC Off" 1 "0 level (Do not use)" 2 "1 level" 3 "2 level" 4 "3 level" 5 "4 level" 6 "5 level" 7 "6 level" 8 "7 level" 9 "8 level" 15 "Invalid" ;
VAL_ 140 ATS_DATC_FrPsBlowerUpDn 0 "Reserved" 1 "Up" 2 "Down" 3 "Invalid" ;
VAL_ 140 ATS_DATC_FrDrMultiAutoBlower 0 "Reserved" 1 "Low" 2 "Medium" 3 "High" 4 "Reserved" 5 "Reserved" 6 "Reserved" 7 "Invalid" ;
VAL_ 140 ATS_DATC_FrPsMultiAutoBlower 0 "Reserved" 1 "Low" 2 "Medium" 3 "High" 4 "Reserved" 5 "Reserved" 6 "Reserved" 7 "Invalid" ;
VAL_ 140 ATS_DATC_RrDrMultiAutoBlower 0 "Reserved" 1 "Low" 2 "Medium" 3 "High" 4 "Reserved" 5 "Reserved" 6 "Reserved" 7 "Invalid" ;
VAL_ 140 ATS_DATC_FragranceStrhSet 0 "Default" 1 "Off" 2 "Low" 3 "Medium" 4 "High" 5 "Reserved" 6 "Reserved" 7 "Invalid" ;
VAL_ 140 ATS_DATC_FragranceKindSet 0 "Default" 1 "First" 2 "Second" 3 "Reserved" 4 "Reserved" 5 "Reserved" 6 "Reserved" 7 "Invalid" ;
VAL_ 140 ATS_DATC_FragranceBttnMnlSet 0 "Default" 1 "Off" 2 "On" 3 "Invalid" ;
VAL_ 140 ATS_DATC_TempUnitSet 0 "Off" 1 "˚C (Centigrade)" 2 "˚F (Fahrenheit)" 3 "Invalid" ;
VAL_ 158 ATS_DATC_FrDrBlowerSet 0 "DATC Off" 1 "0 level (Do not use)" 2 "1 level" 3 "2 level" 4 "3level" 5 "4 level" 6 "5 level" 7 "6 level" 8 "7 level" 9 "8 level" 15 "Invalid" ;
VAL_ 158 ATS_DATC_RrDrTempUpDn 0 "Reserved" 1 "Temp Up" 2 "Temp Down" 3 "Invalid" ;
VAL_ 158 ATS_DATC_RrDrBlowerSet 0 "Off" 1 "0 level" 2 "1 level" 3 "2 level" 4 "3 level" 5 "4 level" 6 "5 level" 7 "6 level" 8 "7 level" 9 "8 level" 14 "reserved" 15 "Invalid" ;
VAL_ 158 ATS_DATC_RrDrModeSet 0 "Off" 1 "VENT" 2 "BL" 3 "FLOOR" 12 "reserved" 13 "reserved" 14 "reserved" 15 "Invalid" ;
VAL_ 158 ATS_DATC_FrDrModeSet 0 "Reserved" 1 "VENT" 2 "BL" 3 "FLOOR" 4 "MIX" 5 "reserved" 6 "reserved" 7 "7 Mode DEF VENT" 8 "reserved" 9 "MODE DEF VENT FLOOR" 10 "7 Mode DEF" 11 "Reserved" 12 "Reserved" 13 "Reserved" 14 "Reserved" 15 "Invalid" ;
VAL_ 158 ATS_DATC_RrOnOffSet 0 "Function Off" 1 "Function On" 2 "reserved" 3 "Invalid" ;
VAL_ 158 ATS_DATC_IntakeSet 0 "REC Off (Fresh On)" 1 "REC ON (Fresh Off)" 2 "reserved" 3 "Invalid" ;
VAL_ 158 ATS_DATC_OffReq 0 "Reserved" 1 "Request" 2 "reserved" 3 "Invalid" ;
VAL_ 158 ATS_DATC_FrDrAutoSet 0 "reserved" 1 "AUTO ON" 2 "reserved" 3 "Invalid" ;
VAL_ 158 ATS_DATC_FrPsTempUpDn 0 "Reserved" 1 "Temp Up" 2 "Temp Down" 3 "Invalid" ;
VAL_ 158 ATS_DATC_FrDefog 0 "Defog Off" 1 "Defog On" 2 "reserved" 3 "Invalid" ;
VAL_ 158 ATS_DATC_RrSyncSet 0 "Reserved" 1 "NOT SYNC" 2 "Rear SYNC" 3 "Invalid" ;
VAL_ 158 ATS_DATC_AcSet 0 "AC Off" 1 "AC ON" 2 "reserved" 3 "Invalid" ;
VAL_ 158 ATS_DATC_AirCleaningSet 0 "Air Cleaning System Off" 1 "Air Cleaning System On" 2 "Air Cleaning System Not Support" 3 "Invalid" ;
VAL_ 158 ATS_DATC_FrDrBlowerUpDn 0 "Reserved" 1 "Up" 2 "Down" 3 "Invalid" ;
VAL_ 158 ATS_DATC_FrDrTempUpDn 0 "Reserved" 1 "Temp Up" 2 "Temp Down" 3 "Invalid" ;
VAL_ 158 ATS_DATC_RrDrAutoSet 0 "Auto Off" 1 "Auto On" 2 "Not Used" 3 "Invalid" ;
VAL_ 157 ATS_DATC_FrDrTempSetC 0 "Blank" 1 "LO" 2 "PHY=HEX*0.5 + 14" 3 "PHY=HEX*0.5 + 14" 4 "PHY=HEX*0.5 + 14" 5 "PHY=HEX*0.5 + 14" 6 "PHY=HEX*0.5 + 14" 7 "PHY=HEX*0.5 + 14" 8 "PHY=HEX*0.5 + 14" 9 "PHY=HEX*0.5 + 14" 10 "PHY=HEX*0.5 + 14" 11 "PHY=HEX*0.5 + 14" 12 "PHY=HEX*0.5 + 14" 13 "PHY=HEX*0.5 + 14" 14 "PHY=HEX*0.5 + 14" 15 "PHY=HEX*0.5 + 14" 16 "PHY=HEX*0.5 + 14" 17 "PHY=HEX*0.5 + 14" 18 "PHY=HEX*0.5 + 14" 19 "PHY=HEX*0.5 + 14" 20 "PHY=HEX*0.5 + 14" 21 "PHY=HEX*0.5 + 14" 22 "PHY=HEX*0.5 + 14" 23 "PHY=HEX*0.5 + 14" 24 "PHY=HEX*0.5 + 14" 25 "PHY=HEX*0.5 + 14" 26 "PHY=HEX*0.5 + 14" 27 "PHY=HEX*0.5 + 14" 28 "PHY=HEX*0.5 + 14" 29 "PHY=HEX*0.5 + 14" 30 "PHY=HEX*0.5 + 14" 31 "PHY=HEX*0.5 + 14" 32 "PHY=HEX*0.5 + 14" 33 "PHY=HEX*0.5 + 14" 34 "PHY=HEX*0.5 + 14" 35 "PHY=HEX*0.5 + 14" 36 "PHY=HEX*0.5 + 14" 37 "0x25~0xFD:Reserved" 253 "0x25~0xFD:Reserved" 254 "HI" 255 "Invalid" ;
VAL_ 157 ATS_DATC_RrDrBlowerUpDn 0 "Reserved" 1 "Blower Up" 2 "Blower Down" 3 "Invalid" ;
VAL_ 157 ATS_DATC_FrSyncSet 0 "Reserved" 1 "NOT SYNC" 2 "SYNC" 3 "Invalid" ;
VAL_ 157 ATS_DATC_RrDrTempSetC 0 "Blank" 1 "LO" 2 "PHY=HEX*0.5 + 14" 3 "PHY=HEX*0.5 + 14" 4 "PHY=HEX*0.5 + 14" 5 "PHY=HEX*0.5 + 14" 6 "PHY=HEX*0.5 + 14" 7 "PHY=HEX*0.5 + 14" 8 "PHY=HEX*0.5 + 14" 9 "PHY=HEX*0.5 + 14" 10 "PHY=HEX*0.5 + 14" 11 "PHY=HEX*0.5 + 14" 12 "PHY=HEX*0.5 + 14" 13 "PHY=HEX*0.5 + 14" 14 "PHY=HEX*0.5 + 14" 15 "PHY=HEX*0.5 + 14" 16 "PHY=HEX*0.5 + 14" 17 "PHY=HEX*0.5 + 14" 18 "PHY=HEX*0.5 + 14" 19 "PHY=HEX*0.5 + 14" 20 "PHY=HEX*0.5 + 14" 21 "PHY=HEX*0.5 + 14" 22 "PHY=HEX*0.5 + 14" 23 "PHY=HEX*0.5 + 14" 24 "PHY=HEX*0.5 + 14" 25 "PHY=HEX*0.5 + 14" 26 "PHY=HEX*0.5 + 14" 27 "PHY=HEX*0.5 + 14" 28 "PHY=HEX*0.5 + 14" 29 "PHY=HEX*0.5 + 14" 30 "PHY=HEX*0.5 + 14" 31 "PHY=HEX*0.5 + 14" 32 "PHY=HEX*0.5 + 14" 33 "PHY=HEX*0.5 + 14" 34 "PHY=HEX*0.5 + 14" 35 "PHY=HEX*0.5 + 14" 36 "PHY=HEX*0.5 + 14" 37 "0x25~0xFC:Reserved" 252 "0x25~0xFC:Reserved" 254 "HI" 255 "Invalid" ;
VAL_ 157 ATS_DATC_RrDrTempSetF 0 "Blank" 1 "LO" 2 "PHY=HEX*1+56" 3 "PHY=HEX*1+56" 4 "PHY=HEX*1+56" 5 "PHY=HEX*1+56" 6 "PHY=HEX*1+56" 7 "PHY=HEX*1+56" 8 "PHY=HEX*1+56" 9 "PHY=HEX*1+56" 10 "PHY=HEX*1+56" 11 "PHY=HEX*1+56" 12 "PHY=HEX*1+56" 13 "PHY=HEX*1+56" 14 "PHY=HEX*1+56" 15 "PHY=HEX*1+56" 16 "PHY=HEX*1+56" 17 "PHY=HEX*1+56" 18 "PHY=HEX*1+56" 19 "PHY=HEX*1+56" 20 "PHY=HEX*1+56" 21 "PHY=HEX*1+56" 22 "PHY=HEX*1+56" 23 "PHY=HEX*1+56" 24 "PHY=HEX*1+56" 25 "PHY=HEX*1+56" 26 "PHY=HEX*1+56" 27 "PHY=HEX*1+56" 28 "PHY=HEX*1+56" 29 "PHY=HEX*1+56" 30 "PHY=HEX*1+56" 31 "PHY=HEX*1+56" 32 "PHY=HEX*1+56" 33 "PHY=HEX*1+56" 34 "PHY=HEX*1+56" 35 "PHY=HEX*1+56" 36 "PHY=HEX*1+56" 37 "0x25~0xFC:Reserved" 252 "0x25~0xFC:Reserved" 254 "HI" 255 "Invalid" ;
VAL_ 157 ATS_DATC_FrPsTempSetC 0 "Blank" 1 "LO" 2 "PHY=HEX*0.5 + 14" 3 "PHY=HEX*0.5 + 14" 4 "PHY=HEX*0.5 + 14" 5 "PHY=HEX*0.5 + 14" 6 "PHY=HEX*0.5 + 14" 7 "PHY=HEX*0.5 + 14" 8 "PHY=HEX*0.5 + 14" 9 "PHY=HEX*0.5 + 14" 10 "PHY=HEX*0.5 + 14" 11 "PHY=HEX*0.5 + 14" 12 "PHY=HEX*0.5 + 14" 13 "PHY=HEX*0.5 + 14" 14 "PHY=HEX*0.5 + 14" 15 "PHY=HEX*0.5 + 14" 16 "PHY=HEX*0.5 + 14" 17 "PHY=HEX*0.5 + 14" 18 "PHY=HEX*0.5 + 14" 19 "PHY=HEX*0.5 + 14" 20 "PHY=HEX*0.5 + 14" 21 "PHY=HEX*0.5 + 14" 22 "PHY=HEX*0.5 + 14" 23 "PHY=HEX*0.5 + 14" 24 "PHY=HEX*0.5 + 14" 25 "PHY=HEX*0.5 + 14" 26 "PHY=HEX*0.5 + 14" 27 "PHY=HEX*0.5 + 14" 28 "PHY=HEX*0.5 + 14" 29 "PHY=HEX*0.5 + 14" 30 "PHY=HEX*0.5 + 14" 31 "PHY=HEX*0.5 + 14" 32 "PHY=HEX*0.5 + 14" 33 "PHY=HEX*0.5 + 14" 34 "PHY=HEX*0.5 + 14" 35 "PHY=HEX*0.5 + 14" 36 "PHY=HEX*0.5 + 14" 37 "0x25~0xFD:Reserved" 253 "0x25~0xFD:Reserved" 254 "HI" 255 "Invalid" ;
VAL_ 157 ATS_DATC_FrPsTempSetF 0 "Blank" 1 "LO" 2 "PHY=HEX*1+56" 3 "PHY=HEX*1+56" 4 "PHY=HEX*1+56" 5 "PHY=HEX*1+56" 6 "PHY=HEX*1+56" 7 "PHY=HEX*1+56" 8 "PHY=HEX*1+56" 9 "PHY=HEX*1+56" 10 "PHY=HEX*1+56" 11 "PHY=HEX*1+56" 12 "PHY=HEX*1+56" 13 "PHY=HEX*1+56" 14 "PHY=HEX*1+56" 15 "PHY=HEX*1+56" 16 "PHY=HEX*1+56" 17 "PHY=HEX*1+56" 18 "PHY=HEX*1+56" 19 "PHY=HEX*1+56" 20 "PHY=HEX*1+56" 21 "PHY=HEX*1+56" 22 "PHY=HEX*1+56" 23 "PHY=HEX*1+56" 24 "PHY=HEX*1+56" 25 "PHY=HEX*1+56" 26 "PHY=HEX*1+56" 27 "PHY=HEX*1+56" 28 "PHY=HEX*1+56" 29 "PHY=HEX*1+56" 30 "PHY=HEX*1+56" 31 "PHY=HEX*1+56" 32 "PHY=HEX*1+56" 33 "PHY=HEX*1+56" 34 "PHY=HEX*1+56" 35 "PHY=HEX*1+56" 36 "PHY=HEX*1+56" 37 "0x25~0xFC:Reserved" 252 "0x25~0xFC:Reserved" 254 "HI" 255 "Invalid" ;
VAL_ 157 ATS_DATC_FrDrTempSetF 0 "Blank" 1 "LO" 2 "PHY=HEX*1 + 56" 3 "PHY=HEX*1 + 56" 4 "PHY=HEX*1 + 56" 5 "PHY=HEX*1 + 56" 6 "PHY=HEX*1 + 56" 7 "PHY=HEX*1 + 56" 8 "PHY=HEX*1 + 56" 9 "PHY=HEX*1 + 56" 10 "PHY=HEX*1 + 56" 11 "PHY=HEX*1 + 56" 12 "PHY=HEX*1 + 56" 13 "PHY=HEX*1 + 56" 14 "PHY=HEX*1 + 56" 15 "PHY=HEX*1 + 56" 16 "PHY=HEX*1 + 56" 17 "PHY=HEX*1 + 56" 18 "PHY=HEX*1 + 56" 19 "PHY=HEX*1 + 56" 20 "PHY=HEX*1 + 56" 21 "PHY=HEX*1 + 56" 22 "PHY=HEX*1 + 56" 23 "PHY=HEX*1 + 56" 24 "PHY=HEX*1 + 56" 25 "PHY=HEX*1 + 56" 26 "PHY=HEX*1 + 56" 27 "PHY=HEX*1 + 56" 28 "PHY=HEX*1 + 56" 29 "PHY=HEX*1 + 56" 30 "PHY=HEX*1 + 56" 31 "PHY=HEX*1 + 56" 32 "PHY=HEX*1 + 56" 33 "PHY=HEX*1 + 56" 34 "PHY=HEX*1 + 56" 35 "PHY=HEX*1 + 56" 36 "PHY=HEX*1 + 56" 37 "0x25~0xFD:Reserved" 253 "0x25~0xFD:Reserved" 254 "HI" 255 "Invalid" ;
VAL_ 2323816449 C_CtrlDrLockRlyCCS_Copy_2 0 "Off (default)" 1 "On (remote Lock Command)" 2 "Reserved" 3 "Invalid" ;
VAL_ 2323816449 C_TeleStrgWhlHeatingCmdIBOX_Copy_2 0 "Off (default)" 1 "On(Remote Heating On)" 2 "Reserved" 3 "Invalid" ;
VAL_ 2323816449 C_TeleDefoggerHeatingCmdIBOX_Copy_2 0 "Off (default)" 1 "On(Remote Heating On)" 2 "Reserved" 3 "Invalid" ;
VAL_ 2323816449 C_TeleDrvSeatOpCmdIBOX_Copy_2 0 "Init" 1 "Unused" 2 "Seat Heat&Vent OFF" 3 "Seat_Vent_Low" 4 "Seat_Vent_Mid" 5 "Seat_Vent_High" 6 "Seat_Heat_Low" 7 "Seat_Heat_Mid" 8 "Seat_Heat_High" 9 "Unused" 10 "Unused" 11 "Unused" 12 "Unused" 13 "Unused" 14 "Unused" 15 "Invalid" ;
VAL_ 2323816449 C_CtrlDrUnlockRlyCCS_Copy_2 0 "0ff" 1 "On (Remote Unlock Command)" 2 "Reserved" 3 "Invalid" ;
VAL_ 2323816449 C_TeleAstSeatOpCmdIBOX_Copy_2 0 "Init" 1 "Unused" 2 "Seat Heat&Vent OFF" 3 "Seat_Vent_Low" 4 "Seat_Vent_Mid" 5 "Seat_Vent_High" 6 "Seat_Heat_Low" 7 "Seat_Heat_Mid" 8 "Seat_Heat_High" 9 "Unused" 10 "Unused" 11 "Unused" 12 "Unused" 13 "Unused" 14 "Unused" 15 "Invalid" ;
VAL_ 2323816449 C_TeleRRSeatOpCmdIBOX_Copy_2 0 "Init" 1 "Unused" 2 "Seat Heat&Vent OFF" 3 "Seat_Vent_Low" 4 "Seat_Vent_Mid" 5 "Seat_Vent_High" 6 "Seat_Heat_Low" 7 "Seat_Heat_Mid" 8 "Seat_Heat_High" 9 "Unused" 10 "Unused" 11 "Unused" 12 "Unused" 13 "Unused" 14 "Unused" 15 "Invalid" ;
VAL_ 2323816449 C_TeleRLSeatOpCmdIBOX_Copy_1 0 "Init" 1 "Unused" 2 "Seat Heat&Vent OFF" 3 "Seat_Vent_Low" 4 "Seat_Vent_Mid" 5 "Seat_Vent_High" 6 "Seat_Heat_Low" 7 "Seat_Heat_Mid" 8 "Seat_Heat_High" 9 "Unused" 10 "Unused" 11 "Unused" 12 "Unused" 13 "Unused" 14 "Unused" 15 "Invalid" ;
VAL_ 2323816449 C_DrvWindowCmdAVN_Copy_2 0 "No action" 1 "Manual Down" 2 "Manual Up" 3 "25% Open" 4 "50% Open" 5 "Auto Down" 6 "Auto Up" 7 "15% Open" 8 "Unused" 9 "Unused" 10 "Unused" 11 "Unused" 12 "Unused" 13 "Unused" 14 "Unused" 15 "Invalid" ;
VAL_ 2323816449 C_HazardFromCCS_Copy_2 0 "Off" 1 "On (Remote Hazard On)" 2 "Reserved" 3 "Invalid" ;
VAL_ 2323816449 C_AstWindowCmdAVN_Copy_2 0 "No action" 1 "Manual Down" 2 "Manual Up" 3 "25% Open" 4 "50%Open" 5 "Auto Down" 6 "Auto Up" 7 "15% Open" 8 "Unused" 9 "Unused" 10 "Unused" 11 "Unused" 12 "Unused" 13 "Unused" 14 "Unused" 15 "Invalid" ;
VAL_ 2323816449 C_RRWindowCmdAVN_Copy_2 0 "No action" 1 "Manual Down" 2 "Manual Up" 3 "25% Open" 4 "50% Open" 5 "Auto Down" 6 "Auto Up" 7 "15% Open" 8 "Unused" 9 "Unused" 10 "Unused" 11 "Unused" 12 "Unused" 13 "Unused" 14 "Unused" 15 "Invalid" ;
VAL_ 2323816449 C_RLWindowCmdAVN_Copy_2 0 "No action" 1 "Manual Down" 2 "Manual Up" 3 "25% Open" 4 "50% Open" 5 "Auto Down" 6 "Auto UP" 7 "15% Open" 8 "Unused" 9 "Unused" 10 "Unused" 11 "Unused" 12 "Unused" 13 "Unused" 14 "Unused" 15 "Invalid" ;
VAL_ 2323816449 TailCtrlReq_Copy 0 "No Action(Default)" 1 "Tail Off" 2 "Tail On" 3 "Error Indicator" ;
VAL_ 2323816449 HazardCtrlReq_Copy 0 "No Action(Default)" 1 "Hazard Off" 2 "Hazard On" 3 "Error Indicator" ;
VAL_ 2323816449 C_PanicFromCCS_Copy_2 0 "Off" 1 "On (Remote Horn and Hazard On)" 2 "Reserved" 3 "Invalid" ;
VAL_ 2323816449 RAC_AirCleaningCtrlReq_Copy_1 0 "Deactive air cleaning control" 1 "Active air cleaning control" 2 "Not used" 3 "invalid" ;
VAL_ 2323816449 C_PreCrankReq_Copy 0 "Default" 1 "Req On" 2 "Not Support" 3 "Invalid" ;
VAL_ 2323816450 C_EsyAcsProfileID_CCU 0 "Default" 1 "Gueset" 2 "Profile 1" 3 "Profile 2" 4 "Reserved" 5 "Reserved" 6 "Reserved" 7 "Reserved" 8 "Reserved" 9 "Reserved" 10 "Reserved" 11 "Reserved" 12 "Reserved" 13 "Reserved" 14 "Reserved" 15 "Invalid" ;
VAL_ 2382594049 DATC_DrvTempCDis 0 "Blank Display" 1 "'LO' Display" 254 "'HI' Display" 255 "Error Indicator" ;
VAL_ 2382594049 DATC_DrvTempFDis 0 "Blank Display" 1 "'LO' Display" 254 "'HI' Display" 255 "Error Indicator" ;
VAL_ 2382594049 DATC_PassTempCDis 0 "Blank Display" 1 "'LO' Display" 254 "'HI' Display" 255 "Error Indicator" ;
VAL_ 2382594049 DATC_PassTempFDis 0 "Blank Display" 1 "'LO' Display" 254 "'HI' Display" 255 "Error Indicator" ;
VAL_ 2382594049 DATC_TempDispSta 0 "OLD Set Temp Display range" 1 "NEW Set Temp Display Range" 2 "Not used" 3 "Error Indicator" ;
VAL_ 2382594561 DATC_FrDrvModDis 0 "Off(Blank Display, 토출모드 미표시 예) Auto 시)" 1 "VENT" 2 "B_L" 3 "FLOOR" 4 "MIX (7 MODE DEF FLOOR)" 5 "DEF (MAX DEF)" 6 "AUTO DEFOG" 7 "7 MODE DEF VENT" 8 "MODE AUTO" 9 "7 MODE DEF VENT FLOOR" 10 "7 MODE DEF" 11 "DEF VENT (Arrow)" 12 "DEF FLOOR (Arrow)" 13 "DEF VENT FLOOR (Arrow)" 14 "DEF (Arrow)" 15 "Error Indicator" ;
VAL_ 2382594561 DATC_FrPassModDis 0 "Off(Blank Display, 토출모드 미표시 예) Auto 시)" 1 "VENT" 2 "B_L" 3 "FLOOR" 4 "MIX (7 MODE DEF FLOOR)" 5 "DEF (MAX DEF)" 6 "AUTO DEFOG" 7 "7 MODE DEF VENT" 8 "MODE AUTO" 9 "7 MODE DEF VENT FLOOR" 10 "7 MODE DEF" 11 "DEF VENT (Arrow)" 12 "DEF FLOOR (Arrow)" 13 "DEF VENT FLOOR (Arrow)" 14 "DEF (Arrow)" 15 "Error Indicator" ;
VAL_ 2382594561 DATC_ClmtTxtPopupOSD 0 "Default" 1 "AirCleaning SYS ON" 2 "AirCleaning SYS OFF" 3 "High Dust AirCleaning ON" 4 "High Dust AirCleaning OFF" 5 "Sensor AirCleaning SYS ON & Closing Window" 6 "Opening Warning" 7 "Auto AirCleaning SYS ON" 8 "Smart Ventilation On" 9 "Washer Intake On" 10 "Rear Climate OFF by ROA" 11 "0x0B~0xFE:Reserved" 254 "0x0B~0xFE:Reserved" 255 "Error Indicator" ;
VAL_ 2382594561 DATC_TempDispUnitSta 0 "Centigrade(℃)" 1 "Fahrenheit(℉)" 2 "Not used" 3 "Error Indicator" ;
VAL_ 2382594561 DATC_DrvAutoDis 0 "AUTO Off" 1 "AUTO On" 2 "Not used" 3 "Error Indicator" ;
VAL_ 2382594561 DATC_FrClmtScrnDis 0 "Deactived" 1 "Actived" 2 "Not used" 3 "Error Indicator" ;
VAL_ 2382594561 DATC_AcDis 0 "A/C Off" 1 "A/C ON" 2 "Not used" 3 "Error Indicator" ;
VAL_ 2382594561 DATC_IntakeSta 0 "Default" 1 "REC (Fresh off)" 2 "FRE (REC off)" 3 "Error Indicator" ;
VAL_ 2424580353 DATC_StrWhlHtrSwReq 0 "Default" 1 "OFF" 2 "ON" 3 "Error Indicator" ;
VAL_ 2424580353 DATC_RrDefSw 0 "Default" 1 "OFF" 2 "ON" 3 "Error Indicator" ;
VAL_ 2424580353 DATC_FLStOpReq 0 "Default" 1 "Integrated control OFF" 2 "OFF" 3 "Left Seat Ventilation 1st ON" 4 "Left Seat Ventilation 1st&2nd ON" 5 "Left Seat Ventilation 1st&2nd&3rd ON" 6 "Left Seat Warmer 1st ON" 7 "Left Seat Warmer 1st&2nd ON" 8 "Left Seat Warmer 1st&2nd&3rd ON" 9 "Not Used" 10 "Not Used" 11 "Not Used" 12 "Not Used" 13 "Not Used" 14 "Not Used" 15 "Error Indicator" ;
VAL_ 2424580353 DATC_FRStOpReq 0 "Default" 1 "Integrated control OFF" 2 "OFF" 3 "Right Seat Ventilation 1st ON" 4 "Right Seat Ventilation 1st&2nd ON" 5 "Right Seat Ventilation 1st&2nd&3rd ON" 6 "Right Seat Warmer 1st ON" 7 "Right Seat Warmer 1st&2nd ON" 8 "Right Seat Warmer 1st&2nd&3rd ON" 9 "Not Used" 10 "Not Used" 11 "Not Used" 12 "Not Used" 13 "Not Used" 14 "Not Used" 15 "Error Indicaotr" ;
VAL_ 2424580353 DATC_RRStHtrSwReq 0 "Default" 1 "OFF" 2 "ON" 3 "Error Indicator" ;
VAL_ 2424580353 DATC_RRStVentSwReq 0 "Default" 1 "OFF" 2 "ON" 3 "Error Indicator" ;
VAL_ 2424580353 DATC_RLStHtrSwReq 0 "Default" 1 "OFF" 2 "ON" 3 "Error Indicator" ;
VAL_ 2424580353 DATC_RLStVentSwReq 0 "Default" 1 "OFF" 2 "ON" 3 "Error Indicator" ;
VAL_ 2424580353 DATC_WdwClsReq 0 "Default" 1 "Close Request" 2 "Reserved" 3 "Error Indicator" ;
VAL_ 2424580353 DATC_RRSyncDis 0 "Rear SYNC Off" 1 "Rear SYNC On" 2 "Not used" 3 "Error Indicator" ;
VAL_ 2563126529 AMP_MTSVolumeStep 0 "0x0x0~0xFD:MTS Volume" 253 "0x0x0~0xFD:MTS Volume" 254 "Request amp supported MTS Set" 255 "Invalid" ;
VAL_ 2390994433 AMP_Beep1VolumeStep 0 "0x0x0~0xFD:Beep1 Volume" 253 "0x0x0~0xFD:Beep1 Volume" 254 "Req.amp. Beep1 settings" 255 "Invalid" ;
VAL_ 2390994433 AMP_Analog_OutputCh_Select 65535 "Invalid" ;
VAL_ 2390994433 AMP_Beep1_OutputCh_Select 65535 "Invaild" ;
VAL_ 2390994433 AMP_Beep1KBDVolumeStep 0 "0x0x0~0xFE:keyboard Beep Volume" 254 "0x0x0~0xFE:keyboard Beep Volume" 255 "Invalid" ;
VAL_ 2390994433 AMP_SPDIF_OutputCh_Select 65535 "Invaild" ;
VAL_ 2479157761 HU_LanguageInfo 0 "Off" 1 "Korea" 2 "English(US)" 3 "English(UK)" 4 "Simplified chinese" 5 "Traditional chinese" 6 "French(EU)" 7 "Spanish(EU)" 8 "Arabic" 9 "Czech" 10 "Danish" 11 "German" 12 "Italian" 13 "Dutch" 14 "Polish" 15 "Portuguese" 16 "Russain" 17 "Slovak" 18 "Swedish" 19 "Turkish" 20 "French(US)" 21 "Spanish(US)" 22 "English(India)" 23 "Norwegian" 24 "Finnish" 25 "Indonesian" 26 "Brazilian Portuguese" 27 "Malay" 28 "Hungarian" 29 "English (Australia)" 30 "Japanese" 31 "Hindi" 32 "Hebrew" 33 "Greek" 34 "Ukrainian" 35 "Slovenian" 36 "Bulgarian" 37 "Croatian" 38 "Romanian" 39 "0x27~0xFE:Reserved" 254 "0x27~0xFE:Reserved" 255 "Invalid" ;
VAL_ 2479157761 HU_MuteStatus 0 "Off" 1 "Mute On" 2 "reserved" 3 "Invalid" ;
VAL_ 2479157761 HU_WelcomeReady 0 "Default" 1 "Ready" 2 "Reserved" 3 "Invalid" ;
VAL_ 2479157761 HU_UsmSupport 0 "Not support" 1 "Support" 2 "reserved" 3 "Invalid" ;
VAL_ 2479157761 HU_NaviStatus 0 "Booting" 1 "Normal Operation" 2 "No SD Card(Map)" 3 "Invalid" ;
VAL_ 2479157761 HU_NaviDisp 0 "Non_Navi" 1 "Navi" 2 "reserved" 3 "Invalid" ;
VAL_ 2479157761 HU_BVM_Display_Message 0 "Not Used" 1 "No Message" 2 "Rain_Warning Message" 3 "Reserved" 4 "Reserved" 5 "Reserved" 6 "Reserved" 7 "Invalid" ;
VAL_ 2479157761 HU_SVM_View_Display 0 "Not Used" 1 "AVM Display View OFF" 31 "Invalid" 2 "AVM Display View ON(LH)" 3 "AVM Display View ON(RH)" 4 "Reserved" 5 "Reserved" 6 "Reserved" 7 "Reserved" 8 "Reserved" 9 "Reserved" 10 "Reserved" 11 "Reserved" 12 "Reserved" 13 "Reserved" 14 "Reserved" 15 "Reserved" 16 "Reserved" 17 "Reserved" 18 "Reserved" 19 "Reserved" 20 "Reserved" 21 "Reserved" 22 "Reserved" 23 "Reserved" 24 "Reserved" 25 "Reserved" 26 "Reserved" 27 "Reserved" 28 "Reserved" 29 "Reserved" 30 "Reserved" ;
VAL_ 2479157761 HU_NaviCamSettingStatus 0 "Navi Camera Alert Setting Status" 1 "Navi Camera Alert Setting Status" 2 "Navi Camera Alert Setting Status" 3 "Navi Camera Alert Setting Status" 4 "Navi Camera Alert Setting Status" 5 "Navi Camera Alert Setting Status" 6 "Navi Camera Alert Setting Status" 7 "Navi Camera Alert Setting Status" 8 "Navi Camera Alert Setting Status" 9 "Navi Camera Alert Setting Status" 10 "Navi Camera Alert Setting Status" 11 "Navi Camera Alert Setting Status" 12 "Navi Camera Alert Setting Status" 13 "Navi Camera Alert Setting Status" 14 "Navi Camera Alert Setting Status" 15 "Navi Camera Alert Setting Status" 16 "Navi Camera Alert Setting Status" 17 "Navi Camera Alert Setting Status" 18 "Navi Camera Alert Setting Status" 19 "Navi Camera Alert Setting Status" 20 "Navi Camera Alert Setting Status" 21 "Navi Camera Alert Setting Status" 22 "Navi Camera Alert Setting Status" 23 "Navi Camera Alert Setting Status" 24 "Navi Camera Alert Setting Status" 25 "Navi Camera Alert Setting Status" 26 "Navi Camera Alert Setting Status" 27 "Navi Camera Alert Setting Status" 28 "Navi Camera Alert Setting Status" 29 "Navi Camera Alert Setting Status" 30 "Navi Camera Alert Setting Status" 31 "Navi Camera Alert Setting Status" 32 "0x20~0xFE:Reserved" 254 "0x20~0xFE:Reserved" 255 "Invalid" ;
VAL_ 2479157761 HU_EVSupport 0 "Not support" 1 "Support" 2 "Reserved" 3 "Invalid" ;
VAL_ 2479157761 HU_AutoBrightState_New 0 "Default" 1 "0x1~0x3FE:Brightness" 1022 "0x1~0x3FE:Brightness" 1023 "Invalid" ;
VAL_ 2479157761 HU_VolumeStatus 63 "Invalid" ;
VAL_ 2298626049 HU_DSW_HeadPoseYawStat 0 "yaw < -40°" 1 "-40°≤ yaw < -35°" 2 "-35°≤ yaw < -30°" 3 "-30°≤ yaw < -25°" 4 "-25°≤ yaw < -20°" 5 "-20°≤ yaw < -15°" 6 "-15°≤ yaw < -10°" 7 "-10°≤ yaw < -5°" 8 "-5°≤ yaw < 0°" 9 "0°≤ yaw < 5°" 10 "5°≤ yaw < 10°" 11 "10°≤ yaw < 15°" 12 "15°≤ yaw < 20°" 13 "20°≤ yaw < 25°" 14 "25°≤ yaw < 30°" 15 "30°≤ yaw < 35°" 16 "35°≤ yaw < 40°" 17 "40°≤ yaw" 18 "Reserved" 19 "Reserved" 20 "Reserved" 21 "Reserved" 22 "Reserved" 23 "Reserved" 24 "Reserved" 25 "Reserved" 26 "Reserved" 27 "Reserved" 28 "Reserved" 29 "Reserved" 30 "Reserved" 31 "Invalid" ;
VAL_ 2298626049 HU_DSW_EyeOpenStat 0 "0~10%" 1 "11~20%" 2 "21~30%" 3 "31~40%" 4 "41~50%" 5 "51~60%" 6 "61~100%" 7 "Invalid" ;
VAL_ 2298626049 HU_DSW_RightEyeOpenStat 0 "0~5%" 1 "6~10%" 2 "11~15%" 3 "16~20%" 4 "21~25%" 5 "26~30%" 6 "31~35%" 7 "36~40%" 8 "41~45%" 9 "46~50%" 10 "51~55%" 11 "56~60%" 12 "61~65%" 13 "66~70%" 14 "71~75%" 15 "76~80%" 16 "81~85%" 17 "86~90%" 18 "91~95%" 19 "96~100%" 20 "Reserved" 21 "Reserved" 22 "Reserved" 23 "Reserved" 24 "Reserved" 25 "Reserved" 26 "Reserved" 27 "Reserved" 28 "Reserved" 29 "Reserved" 30 "Reserved" 31 "Invalid" ;
VAL_ 2298626049 HU_DSW_LatestNumBlink 0 "No blink" 1 "1 blink" 2 "2 blinks" 3 "3 blinks" 4 "4 blinks" 5 "5 or more blinks" 6 "Reserved" 7 "Invalid" ;
VAL_ 2298626049 HU_DSW_HeadPosePitchStat 0 "pitch < -30°" 1 "-30°≤ pitch < -25°" 2 "-25°≤ pitch < -20°" 3 "-20°≤ pitch < -15°" 4 "-15°≤ pitch < -10°" 5 "-10°≤ pitch < -5°" 6 "-5°≤ pitch < 0°" 7 "0°≤ pitch < 5°" 8 "5°≤ pitch < 10°" 9 "10°≤ pitch < 15°" 10 "15°≤ pitch < 20°" 11 "20°≤ pitch < 25°" 12 "25°≤ pitch < 30°" 13 "30°≤ pitch" 14 "Reserved" 15 "Invalid" ;
VAL_ 2298626049 HU_DSW_FaceDectStat 0 "Not detected" 1 "Detected" 2 "Reserved" 3 "Invalid" ;
VAL_ 2298626049 HU_DSW_CamBlckdSta 0 "No blockage" 1 "Camera blockage" 2 "Reserved" 3 "Invalid" ;
VAL_ 2298626049 HU_DSW_EyeGazePitchStat 0 "pitch < -30°" 1 "-30°≤ pitch < -25°" 2 "-25°≤ pitch < -20°" 3 "-20°≤ pitch < -15°" 4 "-15°≤ pitch < -10°" 5 "-10°≤ pitch < -5°" 6 "-5°≤ pitch < 0°" 7 "0°≤ pitch < 5°" 8 "5°≤ pitch < 10°" 9 "10°≤ pitch < 15°" 10 "15°≤ pitch < 20°" 11 "20°≤ pitch < 25°" 12 "25°≤ pitch < 30°" 13 "30°≤ pitch" 14 "Reserved" 15 "Invalid" ;
VAL_ 2298626049 HU_DSW_FakeStat 0 "Real face" 1 "Photo (fake)" 2 "Reserved" 3 "Invalid" ;
VAL_ 2298626049 HU_DSW_DistWrngTypSta 0 "No warning" 1 "Distraction warning" 2 "Drowsiness warning" 3 "Invalid" ;
VAL_ 2298626049 HU_DSW_PerclosStat 0 "0~9%" 1 "10~14%" 2 "15%~" 3 "Invalid" ;
VAL_ 2298626049 HU_DSW_LongBlinkStat 0 "no long blink" 1 "2 long blinks" 2 "3 long blinks" 3 "Invalid" ;
VAL_ 2298626049 HU_DSW_TalkStat 0 "no talk" 1 "talking" 2 "yawn" 3 "Invalid" ;
VAL_ 2298626049 HU_DSW_DistFtgWrngSta 0 "Default" 1 "Not distracted and not drowsy" 2 "Distracted or drowsy" 3 "Invalid" ;
VAL_ 2298626049 HU_DSW_EyeGazeYawStat 0 "yaw < -40°" 1 "-40°≤ yaw < -35°" 2 "-35°≤ yaw < -30°" 3 "-30°≤ yaw < -25°" 4 "-25°≤ yaw < -20°" 5 "-20°≤ yaw < -15°" 6 "-15°≤ yaw < -10°" 7 "-10°≤ yaw < -5°" 8 "-5°≤ yaw < 0°" 9 "0°≤ yaw < 5°" 10 "5°≤ yaw < 10°" 11 "10°≤ yaw < 15°" 12 "15°≤ yaw < 20°" 13 "20°≤ yaw < 25°" 14 "25°≤ yaw < 30°" 15 "30°≤ yaw < 35°" 16 "35°≤ yaw < 40°" 17 "40°≤ yaw" 18 "Reserved" 19 "Reserved" 20 "Reserved" 21 "Reserved" 22 "Reserved" 23 "Reserved" 24 "Reserved" 25 "Reserved" 26 "Reserved" 27 "Reserved" 28 "Reserved" 29 "Reserved" 30 "Reserved" 31 "Invalid" ;
VAL_ 2298626049 HU_DSW_SymSta 0 "Default (No Option)" 1 "System Active" 2 "System Ready" 3 "Camera blockage" 4 "Interior view camera Fail" 5 "ECU Fail" 6 "Off" 7 "Invalid" ;
VAL_ 2298626049 HU_DSW_EyeStat 0 "Closed" 1 "Opened" 2 "Reserved" 3 "Invalid" ;
VAL_ 2298626049 HU_DSW_LatestLongClosedStat 0 "None" 1 "Occur" 2 "Reserved" 3 "Invalid" ;
VAL_ 2298626049 HU_DSW_LeftEyeOpenStat 0 "0~5%" 1 "6~10%" 2 "11~15%" 3 "16~20%" 4 "21~25%" 5 "26~30%" 6 "31~35%" 7 "36~40%" 8 "41~45%" 9 "46~50%" 10 "51~55%" 11 "56~60%" 12 "61~65%" 13 "66~70%" 14 "71~75%" 15 "76~80%" 16 "81~85%" 17 "86~90%" 18 "91~95%" 19 "96~100%" 20 "Reserved" 21 "Reserved" 22 "Reserved" 23 "Reserved" 24 "Reserved" 25 "Reserved" 26 "Reserved" 27 "Reserved" 28 "Reserved" 29 "Reserved" 30 "Reserved" 31 "Invalid" ;
VAL_ 2462365953 SEG_V2_3_Offset 0 "0x0x0~0x1FFE:Distance" 8190 "0x0x0~0x1FFE:Distance" 8191 "Invalid" ;
VAL_ 2462365953 SEG_V2_3_PathIndex 0 "Unknown" 1 "Reserved" 2 "Reserved" 3 "Reserved" 4 "Reserved" 5 "Reserved" 6 "Reserved" 7 "Reserved" 63 "Invalid" 8 "General Path Index" 9 "General Path Index" 10 "General Path Index" 11 "General Path Index" 12 "General Path Index" 13 "General Path Index" 14 "General Path Index" 15 "General Path Index" 16 "General Path Index" 17 "General Path Index" 18 "General Path Index" 19 "General Path Index" 20 "General Path Index" 21 "General Path Index" 22 "General Path Index" 23 "General Path Index" 24 "General Path Index" 25 "General Path Index" 26 "General Path Index" 27 "General Path Index" 28 "General Path Index" 29 "General Path Index" 30 "General Path Index" 31 "General Path Index" 32 "General Path Index" 33 "General Path Index" 34 "General Path Index" 35 "General Path Index" 36 "General Path Index" 37 "General Path Index" 38 "General Path Index" 39 "General Path Index" 40 "General Path Index" 41 "General Path Index" 42 "General Path Index" 43 "General Path Index" 44 "General Path Index" 45 "General Path Index" 46 "General Path Index" 47 "General Path Index" 48 "General Path Index" 49 "General Path Index" 50 "General Path Index" 51 "General Path Index" 52 "General Path Index" 53 "General Path Index" 54 "General Path Index" 55 "General Path Index" 56 "General Path Index" 57 "General Path Index" 58 "General Path Index" 59 "General Path Index" 60 "General Path Index" 61 "General Path Index" 62 "General Path Index" ;
VAL_ 2462365953 SEG_V2_3_CalculatedRoute 0 "Not Calculated Route(MPP)" 1 "Part of Calculated Route" 2 "Off Route or Recalculating" 3 "Invalid" ;
VAL_ 2462365953 SEG_V2_3_FuncRoadClass 0 "Unknown" 1 "Freeway" 2 "Arterial(City freeway)" 3 "County" 4 "Collector" 5 "Local" 6 "Etc(ferry, unpaved)" 7 "Invalid" ;
VAL_ 2462365953 SEG_V2_3_SpeedLimit 0 "Unknown" 1 "Under 5kph(mph)" 16 "75kph(mph)" 17 "80kph(mph)" 18 "85kph(mph)" 19 "90kph(mph)" 20 "95kph(mph)" 21 "100kph(mph)" 22 "105kph(mph)" 23 "110kph(mph)" 24 "115kph(mph)" 25 "120kph(mph)" 26 "125kph(mph)" 27 "130kph(mph)" 28 "135kph(mph)" 29 "140kph(mph)" 30 "Unlimited" 31 "Invalid" 2 "7kph(mph)" 3 "10kph(mph)" 4 "15kph(mph)" 5 "20kph(mph)" 6 "25kph(mph)" 7 "30kph(mph)" 8 "35kph(mph)" 9 "40kph(mph)" 10 "45kph(mph)" 11 "50kph(mph)" 12 "55kph(mph)" 13 "60kph(mph)" 14 "65kph(mph)" 15 "70kph(mph)" ;
VAL_ 2462365953 SEG_V2_3_FormOfWay 0 "Unkonwn" 1 "Main road(nondisjunction)" 2 "Main road(disjunction)" 3 "JC" 4 "Plural Junction M" 5 "IC" 6 "Reserved" 7 "Service Area" 8 "Reserved" 9 "Roundabout" 10 "P turn" 11 "U trun" 12 "Pedestrian" 13 "Frontage Road" 14 "Intersection internal(Plural Junction)" 15 "Invalid" ;
VAL_ 2462365953 SEG_V2_3_DirectionLanes 0 "Unknown" 1 "Lane count" 2 "Lane count" 3 "Lane count" 4 "Lane count" 5 "Lane count" 6 "Lane count" 7 "Lane count" 8 "Lane count" 9 "Lane count" 10 "Lane count" 11 "Lane count" 12 "Lane count" 13 "Lane count" 14 "Lane count" 15 "Invalid" ;
VAL_ 2462365953 SEG_V2_3_SpeedLimitUnder5 0 "0kph(mph)" 1 "1kph(mph)" 2 "2kph(mph)" 3 "3kph(mph)" 4 "4kph(mph)" 5 "reserved" 6 "reserved" 7 "Invalid" ;
VAL_ 2462365953 SEG_V2_3_DividedRoad 0 "Part of a divided road" 1 "Not part of a divided road" 2 "Unknown" 3 "Invalid" ;
VAL_ 2462365953 SEG_V2_3_CyclicCounter 0 "Cyclic Counter" 1 "Cyclic Counter" 2 "Cyclic Counter" 3 "Cyclic Counter" 4 "Reserved" 5 "Reserved" 6 "Reserved" 7 "Invalid" ;
VAL_ 2462365953 SEG_V2_3_Retransmission 0 "False" 1 "True" 2 "Reserved" 3 "Invalid" ;
VAL_ 1076 IAU_ProfileIDRVal 0 "Default" 1 "Guest" 2 "Profile1" 3 "Profile2" 4 "Reserved" 5 "Reserved" 6 "Reserved" 7 "Reserved" 8 "Reserved" 9 "Reserved" 10 "Reserved" 11 "Reserved" 12 "Reserved" 13 "Reserved" 14 "Reserved" 15 "Invalid" ;
VAL_ 1076 IAU_ISKLearnState 0 "Default" 1 "Learning" 2 "Neutral" 3 "Reserved" ;
VAL_ 1076 IAU_DigitalKeyProcessingSta 0 "None" 1 "DeviceOnWPC" 2 "DeviceRegistering" 3 "PhoneRegistered" 4 "All Phone Key Deleted" 5 "NFCCard1Registered" 6 "Server Registering" 7 "NFCCard1Deleted" 8 "BLE Searching" 9 "Owner Phone key Deleted" 10 "Valet Off Searching" 11 "Server Registering Fail" 12 "Reserved" 13 "Reserved" 14 "Reserved" 15 "Invalid" ;
VAL_ 1076 IAU_DigitalKeyExit 0 "Normal" 1 "Check System" 2 "NFC Not Detected" 3 "Fob Not Detected" 4 "Canceled by User (Timeout)" 5 "Device not Available" 6 "ProcessFail" 7 "Check Card Save" 8 "Certificate Update" 9 "Valet Off Fail" 10 "CardNotAvailable" 11 "DigitalKeyDisabled" 12 "KeyNotSaved" 13 "Reserved" 14 "Reserved" 15 "Invalid" ;
VAL_ 1076 IAU_DigitalKeyEnblRVal 0 "Default" 1 "Disable" 2 "Enable" 3 "Invalid" ;
VAL_ 1076 IAU_OwnerPhnRegRVal 0 "Default" 1 "Disable" 2 "Enable" 3 "Invalid" ;
VAL_ 1076 IAU_NFCCard1RegRVal 0 "Default" 1 "Disable" 2 "Enable" 3 "Invalid" ;
VAL_ 1076 IAU_RdyToSendAuthDataSta 0 "None" 1 "Ready to Send data" 2 "Not Used" 3 "Error Indicator" ;
VAL_ 1076 IAU_DISPWrng 0 "None" 1 "Auth_Fail2 (DigitalKey)" 2 "ReAuth_Warning" 3 "IAU Error" 4 "DigitalKey Saved" 5 "Auth_Fail2 (FP)" 6 "Auth_Fail2 (DigitalKey or FP)" 7 "BiometricKey Saved" 8 "DigitalKey and BiometricKey Saved" 9 "Reserved" 10 "Reserved" 11 "Reserved" 12 "Reserved" 13 "Reserved" 14 "Reserved" 15 "Invalid" ;
VAL_ 1076 IAU_DigitalKey2Opt 0 "Default (Not applied)" 1 "Digital Key Light (NFC)" 2 "Digital Key Medium (NFC/BLE)" 3 "Digital Key Full (NFC/BLE/UWB)" 4 "Reserved" 5 "Reserved" 6 "Reserved" 7 "invalid" ;
VAL_ 1076 IAUwFPMLearnState 0 "Default(Normal)" 1 "Learning" 2 "Neutralizing" 3 "Invalid" ;
VAL_ 1227 DrvIMS_MemoryP1Req 0 "None" 1 "P1" 2 "Not Used" 3 "Error Indicator" ;
VAL_ 1227 DrvIMS_PlyBckP2Req 0 "None" 1 "P2" 2 "Not Used" 3 "Error Indicator" ;
VAL_ 1227 DrvIMS_PlyBckP3Req 0 "None" 1 "P3" 2 "Not Used" 3 "Error Indicator" ;
VAL_ 1227 DrvIMS_PlyBckStpReq 0 "Off" 1 "Stop" 2 "Not Used" 3 "Error Indicator" ;
VAL_ 1227 SmrtIMS_PlyBckReq 0 "None" 1 "0x1~0x97E:Smart IMS DB Number(1~2430)" 2430 "0x1~0x97E:Smart IMS DB Number(1~2430)" 2431 "0x97F~0xFFE:RESERVED" 4094 "0x97F~0xFFE:RESERVED" 4095 "Invalid" ;
VAL_ 1227 DrvIMS_MemoryP2Req 0 "None" 1 "P2" 2 "Not Used" 3 "Error Indicator" ;
VAL_ 1227 SmrtIMS_ImgDBVal 0 "none" 1 "Smart IMS Image DB 1~30" 2 "Smart IMS Image DB 1~30" 3 "Smart IMS Image DB 1~30" 4 "Smart IMS Image DB 1~30" 5 "Smart IMS Image DB 1~30" 6 "Smart IMS Image DB 1~30" 7 "Smart IMS Image DB 1~30" 8 "Smart IMS Image DB 1~30" 9 "Smart IMS Image DB 1~30" 10 "Smart IMS Image DB 1~30" 11 "Smart IMS Image DB 1~30" 12 "Smart IMS Image DB 1~30" 13 "Smart IMS Image DB 1~30" 14 "Smart IMS Image DB 1~30" 15 "Smart IMS Image DB 1~30" 16 "Smart IMS Image DB 1~30" 17 "Smart IMS Image DB 1~30" 18 "Smart IMS Image DB 1~30" 19 "Smart IMS Image DB 1~30" 20 "Smart IMS Image DB 1~30" 21 "Smart IMS Image DB 1~30" 22 "Smart IMS Image DB 1~30" 23 "Smart IMS Image DB 1~30" 24 "Smart IMS Image DB 1~30" 25 "Smart IMS Image DB 1~30" 26 "Smart IMS Image DB 1~30" 27 "Smart IMS Image DB 1~30" 28 "Smart IMS Image DB 1~30" 29 "Smart IMS Image DB 1~30" 30 "Smart IMS Image DB 1~30" 31 "Invalid" ;
VAL_ 1227 SmrtIMS_PlyBckStpReq 0 "OFF" 1 "On" 2 "Not Used" 3 "Error Indicator" ;
VAL_ 1227 DrvIMS_MemoryP3Req 0 "None" 1 "P3" 2 "Not Used" 3 "Error Indicator" ;
VAL_ 1227 SmrtIMS_EnterSwSta 0 "off" 1 "on" 2 "reserved" 3 "invalid" ;
VAL_ 1227 DrvIMS_BzrReq 0 "Off" 1 "On" 2 "Not Used" 3 "Error Indicator" ;
VAL_ 1227 DrvIMS_ErrConWmgDis 0 "Off" 1 "On" 2 "Not Used" 3 "Error Indicator" ;
VAL_ 1227 DrvIMS_MemorySetEnaSta 0 "Disable" 1 "Enable" 2 "Not Used" 3 "Error Indicator" ;
VAL_ 1227 DrvIMS_PlyBckP1Req 0 "None" 1 "P1" 2 "Not Used" 3 "Error Indicator" ;
VAL_ 1252 RKE_BtnReq 0 "None" 1 "Lock" 2 "Unlock" 3 "Trunk(Or Tail Gate)" 4 "Panic" 5 "Panic Stop" 6 "Two Step Unlock Warning or India Door Lock/Unlock Sound ON/OFF Set" 7 "Remote Cranking Stop" 8 "Remote Cranking Start" 9 "Forward(RSPA)" 10 "Backward/Parking(RSPA)" 11 "Pause(RSPA)" 12 "Trunk Hold(or Tailgate Hold)" 13 "Trunk Stop(or Tailgate Stop)" 14 "Not Used" 15 "Error Indicator" ;
VAL_ 1252 RKE_WdwUpDnReq 0 "None" 1 "Remote Window Open" 2 "Remote Window Close" 3 "Remote Window Stop" 4 "Reseved" 5 "Reseved" 6 "Not Used" 7 "Error Indicator" ;
VAL_ 1252 RKE_TrnkTlgtBtnReq 0 "Default" 1 "TailgateTrunkOn" 2 "Off" 3 "Reserved" 4 "Reserved" 5 "Reseved" 6 "Reseved" 7 "Error Indiator" ;
VAL_ 1252 RKE_ID 0 "None" 1 "ID1" 2 "ID2" 3 "ID3" 4 "ID4" 5 "Reseved" 6 "Not Used" 7 "Error Indicator" ;
VAL_ 1252 RKE_PwrDrAllOpnClsReq 0 "None" 1 "Open" 2 "Close" 3 "Stop" 4 "Reserved" 5 "Reserved" 6 "Reserved" 7 "Reserved" ;
VAL_ 681 RLPSM_ReturnMemReq 0 "None" 1 "ReturnMem" 2 "Reset" 3 "Error Indicator" ;
VAL_ 681 RLPSM_RearModeWngDis 0 "Default" 1 "Mode-Fail (Not Initialized)" 2 "Reserved" 3 "Reserved" 4 "Reserved" 5 "Reserved" 6 "Reserved" 7 "Invaild" ;
VAL_ 681 RLPSM_RestMemReq 0 "None" 1 "RestMem" 2 "Reset" 3 "Error Indicator" ;
VAL_ 138 RLPSS_L_StSldFwdMvBtn 0 "Default" 1 "Off" 2 "On" 3 "Invalid" ;
VAL_ 138 RLPSS_L_StRclFwdMvBtn 0 "Default" 1 "Off" 2 "On" 3 "Invalid" ;
VAL_ 138 RLPSS_L_StSldBwdMvBtn 0 "Default" 1 "Off" 2 "On" 3 "Invalid" ;
VAL_ 138 RLPSS_L_StRclBwdMvBtn 0 "Default" 1 "Off" 2 "On" 3 "Invalid" ;
VAL_ 138 RLPSS_L_StTltUpMvBtn 0 "Default" 1 "Off" 2 "On" 3 "Invalid" ;
VAL_ 138 RLPSS_L_StTltDnMvBtn 0 "Default" 1 "Off" 2 "On" 3 "Invalid" ;
VAL_ 138 RLPSS_L_StHRestUpMvBtn 0 "Default" 1 "Off" 2 "On" 3 "Invalid" ;
VAL_ 138 RLPSS_L_StHRestDnMvBtn 0 "Default" 1 "Off" 2 "On" 3 "Invalid" ;
VAL_ 138 RLPSS_L_StHRestFwdMvBtn 0 "Default" 1 "Off" 2 "On" 3 "Invalid" ;
VAL_ 138 RLPSS_L_StHRestBwdMvBtn 0 "Default" 1 "Off" 2 "On" 3 "Invalid" ;
VAL_ 138 RLPSS_L_StLegRestUpBtn 0 "Default" 1 "Off" 2 "On" 3 "Invalid" ;
VAL_ 138 RLPSS_L_StLegRestDnBtn 0 "Default" 1 "Off" 2 "On" 3 "Invalid" ;
VAL_ 138 RLPSS_L_StLegRestExtUpBtn 0 "Default" 1 "Off" 2 "On" 3 "Invalid" ;
VAL_ 138 RLPSS_L_StLegRestExtDnBtn 0 "Default" 1 "Off" 2 "On" 3 "Invalid" ;
VAL_ 143 RLSAU_L_AirSptTimeRValueSet 0 "Default" 1 "Short" 2 "Normal" 3 "Long" 4 "Reserved" 5 "Reserved" 6 "Reserved" 7 "Reserved" ;
VAL_ 143 RLSAU_L_RLSmtAirSptRValueSet 0 "Default" 1 "Off" 2 "On" 3 "Invalid" ;
VAL_ 143 RLSAU_L_LumbarDefSta 0 "Default" 1 "Off" 2 "On" 3 "Invalid" ;
VAL_ 143 RLSAU_L_LumbarUpSta 0 "Defualt" 1 "Off" 2 "On" 3 "Invalid" ;
VAL_ 143 RLSAU_L_LumbarMidSta 0 "Default" 1 "Off" 2 "On" 3 "Invalid" ;
VAL_ 143 RLSAU_L_LumbarLowSta 0 "Default" 1 "Off" 2 "On" 3 "Invalid" ;
VAL_ 143 RLSAU_L_BolsterInfSta 0 "Defalut" 1 "Off" 2 "On" 3 "Invalid" ;
VAL_ 143 RLSAU_L_BolsterDefSta 0 "Default" 1 "Off" 2 "On" 3 "Invalid" ;
VAL_ 143 RLSAU_L_BackSoftRValueSet 0 "Default" 1 "Off" 2 "Soft" 3 "Mid" 4 "Hard" 5 "Reserved" 6 "Reserved" 7 "Reserved" ;
VAL_ 143 RLSAU_L_ActiveSw 0 "Default" 1 "Off" 2 "On" 3 "Invalid" ;
VAL_ 143 RLSAU_L_AirSptModeRValueSet 0 "Default" 1 "Mode 1" 2 "Mode 2" 3 "Mode 3" 4 "Mode 4" 5 "Mode 5" 6 "Reserved" 7 "Reserved" ;
VAL_ 143 RLSAU_L_MoodTrpyRValueSet 0 "Defualt" 1 "Off" 2 "On" 3 "Invalid" ;
VAL_ 143 RLSAU_L_MoodTrpyCareSta 0 "Defualt" 1 "Off" 2 "On" 3 "Invalid" ;
VAL_ 143 RLSAU_L_MoodTrpyComfSta 0 "Defualt" 1 "Off" 2 "On" 3 "Invalid" ;
VAL_ 143 RLSAU_L_AirSptStrRValueSet 0 "Default" 1 "Low" 2 "Mid" 3 "High" 4 "Off" 5 "Reserved" 6 "Reserved" 7 "Reserved" ;
VAL_ 159 RRSAU_L_AirSptTimeRValueSet 0 "Default" 1 "Short" 2 "Normal" 3 "Long" 4 "Reserved" 5 "Reserved" 6 "Reserved" 7 "Reserved" ;
VAL_ 159 RRSAU_L_RRSmtAirSptRValueSet 0 "Default" 1 "Off" 2 "On" 3 "Invalid" ;
VAL_ 159 RRSAU_L_LumbarDefSta 0 "Default" 1 "Off" 2 "On" 3 "Invalid" ;
VAL_ 159 RRSAU_L_LumbarUpSta 0 "Default" 1 "Off" 2 "On" 3 "Invalid" ;
VAL_ 159 RRSAU_L_LumbarMidSta 0 "Default" 1 "Off" 2 "On" 3 "Invalid" ;
VAL_ 159 RRSAU_L_LumbarLowSta 0 "Default" 1 "Off" 2 "On" 3 "Invalid" ;
VAL_ 159 RRSAU_L_BolsterInfSta 0 "Default" 1 "Off" 2 "On" 3 "Invalid" ;
VAL_ 159 RRSAU_L_BolsterDefSta 0 "Default" 1 "Off" 2 "On" 3 "Invalid" ;
VAL_ 159 RRSAU_L_BackSoftRValueSet 0 "Default" 1 "Off" 2 "Soft" 3 "Mid" 4 "Hard" 5 "Reserved" 6 "Reserved" 7 "Reserved" ;
VAL_ 159 RRSAU_L_ActiveSw 0 "Default" 1 "Off" 2 "On" 3 "Invalid" ;
VAL_ 159 RRSAU_L_AirSptModeRValueSet 0 "Default" 1 "Mode 1" 2 "Mode 2" 3 "Mode 3" 4 "Mode 4" 5 "Mode 5" 6 "Reserved" 7 "Reserved" ;
VAL_ 159 RRSAU_L_MoodTrpyRValueSet 0 "Default" 1 "Off" 2 "On" 3 "Invalid" ;
VAL_ 159 RRSAU_L_MoodTrpyCareSta 0 "Default" 1 "Off" 2 "On" 3 "Invalid" ;
VAL_ 159 RRSAU_L_MoodTrpyComfSta 0 "Default" 1 "Off" 2 "On" 3 "Invalid" ;
VAL_ 159 RRSAU_L_AirSptStrRValueSet 0 "Default" 1 "Low" 2 "Mid" 3 "High" 4 "Off" 5 "Reserved" 6 "Reserved" 7 "Reserved" ;
VAL_ 1253 DoorLock_PsvDrLkReq 0 "None" 1 "Lock" 2 "PassiveTrunkLock" 3 "Reserved" 4 "Reserved" 5 "Reseved" 6 "Not Used" 7 "Error Indicator" ;
VAL_ 1253 DoorLock_PsvDrUnLkReq 0 "None" 1 "UnLock" 2 "Unlock only DRV Door" 3 "PIC_Key_Reminder" 4 "Reserved" 5 "Reseved" 6 "Not Used" 7 "Error Indicator" ;
VAL_ 1253 DoorLock_DrvDrPsvAcsReq 0 "Off" 1 "On" 2 "Not Used" 3 "Error Indicator" ;
VAL_ 1253 DoorLock_AsstDrPsvAcsReq 0 "Off" 1 "On" 2 "Not Used" 3 "Error Indicator" ;
VAL_ 1253 DoorLock_TrnkTlgtPsvAcsReq 0 "Off" 1 "On" 2 "Not Used" 3 "Error Indicator" ;
VAL_ 1253 DoorLock_RrLftDrPsvAcsReq 0 "Off" 1 "On" 2 "Not Used" 3 "Error Indicator" ;
VAL_ 1253 DoorLock_RrRtDrPsvAcsReq 0 "Off" 1 "On" 2 "Not Used" 3 "Error Indicator" ;
VAL_ 1253 Auth_Req 0 "None" 1 "" 2 "Auth Request for Terminal Function" 3 "Reserved" 4 "Reserved" 5 "Reserved" 6 "Reserved" 7 "Reserved" ;
VAL_ 1253 RSPA_DigitalKeyAuth 0 "Default" 1 "Digital Key Auth" 2 "Not used" 3 "Error Indicator" ;
VAL_ 1253 Auth_Method 0 "None Auth" 1 "Auth by FOB" 2 "Auth by TP" 3 "Auth by FP" 4 "Auth by NFC (DK or Card)" 5 "Auth Fail" 6 "Auth by BLE (CHINA)" 7 "FRU" 8 "Auth by Digital Key RKE" 9 "Auth by Digital Key Passive" 10 "Reserve" 11 "Reserve" 12 "Reserve" 13 "Reserve" 14 "Not used" 15 "Error Indicator" ;
VAL_ 1253 RSPA_CanTmotFlagSta 0 "Default(No Timeout)" 1 "RSPA CAN Timeout" 2 "Not Used" 3 "Error Indicator" ;
VAL_ 1253 Auth_ISKLearnFdbck 0 "Default (Normal)" 1 "Positive" 2 "Mismatch ISK" 3 "Mismatch RN" 4 "Save Failed ISK" 5 "Timeout" 6 "Not Learnt" 7 "Reserved" 8 "Reserved" 9 "Reserved" 10 "Reserved" 11 "Reserved" 12 "Reserved" 13 "Reserved" 14 "not used" 15 "Error Indicator" ;
VAL_ 1253 Mirror_SmrtWlcmMirrReq 0 "Default" 1 "Fold(Away)" 2 "Unfold(Access)" 3 "Error Indicator" ;
VAL_ 1253 SecureCom_Req 0 "None" 1 "Auth Request for secure communication" 2 "Not used" 3 "Not used" 4 "Not used" 5 "Not used" 6 "Not used" 7 "Error Indicator" ;
VAL_ 1253 Auth_Event 0 "Default" 1 "Lock" 2 "Unlcok" 3 "Start" 4 "Trunk" 5 "Reserved" 6 "Reserved" 7 "Reserved" 8 "Reserved" 9 "Reserved" 10 "Reserved" 11 "Reserved" 12 "Reserved" 13 "Reserved" 14 "Not Used" 15 "Invalid" ;
